VERSION ""

NS_ :

BS_:

BU_: ESP_ABR Vector__XXX

BA_DEF_ BO_ "GenMsgCycleTime" INT 0 65535;
BA_DEF_DEF_ "GenMsgCycleTime" 0;

CM_ "Converted from Mercedes 204_CHASSIS_AEJ2010_1.dat binary database.";

BO_ 1 EIS_A1: 8 ESP_ABR
 SG_ ISw_Stat : 5|3@1+ (1,0) [0|7] "" Vector__XXX

CM_ SG_ 1 ISw_Stat "ISw_Stat [source enum/value-table reference]";
 SG_ Ign_On_StProc_Inact : 4|1@1+ (1,0) [0|1] "" Vector__XXX

CM_ SG_ 1 Ign_On_StProc_Inact "Ign_On_StProc_Inact [source boolean]";
 SG_ TxPkPosn_Rq : 3|1@1+ (1,0) [0|1] "" Vector__XXX

CM_ SG_ 1 TxPkPosn_Rq "TxPkPosn_Rq [source boolean]";
 SG_ TxPkPosn_Emg_Rq : 2|1@1+ (1,0) [0|1] "" Vector__XXX

CM_ SG_ 1 TxPkPosn_Emg_Rq "TxPkPosn_Emg_Rq [source boolean]";
 SG_ TxPkPosn_Rq_SBC_Enbl : 0|1@1+ (1,0) [0|1] "" Vector__XXX

CM_ SG_ 1 TxPkPosn_Rq_SBC_Enbl "TxPkPosn_Rq_SBC_Enbl [source boolean]";
 SG_ KG_IgnCtrl_Actv : 15|1@1+ (1,0) [0|1] "" Vector__XXX

CM_ SG_ 1 KG_IgnCtrl_Actv "KG_IgnCtrl_Actv [source boolean]";
 SG_ EngSt_Enbl_Rq_KG : 14|1@1+ (1,0) [0|1] "" Vector__XXX

CM_ SG_ 1 EngSt_Enbl_Rq_KG "EngSt_Enbl_Rq_KG [source boolean]";
 SG_ KG_StSw_Psd : 13|1@1+ (1,0) [0|1] "" Vector__XXX

CM_ SG_ 1 KG_StSw_Psd "KG_StSw_Psd [source boolean]";
 SG_ AutoDrLk_Rq_Src : 8|2@1+ (1,0) [0|3] "" Vector__XXX

CM_ SG_ 1 AutoDrLk_Rq_Src "AutoDrLk_Rq_Src [source enum/value-table reference]";
 SG_ AutoDrLk_Stat : 18|2@1+ (1,0) [0|3] "" Vector__XXX

CM_ SG_ 1 AutoDrLk_Stat "AutoDrLk_Stat [source enum/value-table reference]";
 SG_ SPCR_Conf_EIS : 30|2@1+ (1,0) [0|3] "" Vector__XXX

CM_ SG_ 1 SPCR_Conf_EIS "SPCR_Conf_EIS [source enum/value-table reference]";
 SG_ CLkS_DL_Stat : 26|2@1+ (1,0) [0|3] "" Vector__XXX

CM_ SG_ 1 CLkS_DL_Stat "CLkS_DL_Stat [source enum/value-table reference]";
 SG_ CLkS_Gas_Dr_Stat : 24|2@1+ (1,0) [0|3] "" Vector__XXX

CM_ SG_ 1 CLkS_Gas_Dr_Stat "CLkS_Gas_Dr_Stat [source enum/value-table reference]";
 SG_ CLkS_Dr_FL_Stat : 38|2@1+ (1,0) [0|3] "" Vector__XXX

CM_ SG_ 1 CLkS_Dr_FL_Stat "CLkS_Dr_FL_Stat [source enum/value-table reference]";
 SG_ CLkS_Dr_FR_Stat : 36|2@1+ (1,0) [0|3] "" Vector__XXX

CM_ SG_ 1 CLkS_Dr_FR_Stat "CLkS_Dr_FR_Stat [source enum/value-table reference]";
 SG_ CLkS_Dr_RL_Stat : 34|2@1+ (1,0) [0|3] "" Vector__XXX

CM_ SG_ 1 CLkS_Dr_RL_Stat "CLkS_Dr_RL_Stat [source enum/value-table reference]";
 SG_ CLkS_Dr_RR_Stat : 32|2@1+ (1,0) [0|3] "" Vector__XXX

CM_ SG_ 1 CLkS_Dr_RR_Stat "CLkS_Dr_RR_Stat [source enum/value-table reference]";
 SG_ KeyLine1_Appr : 47|1@1+ (1,0) [0|1] "" Vector__XXX

CM_ SG_ 1 KeyLine1_Appr "KeyLine1_Appr [source boolean]";
 SG_ KeyLine2_Appr : 46|1@1+ (1,0) [0|1] "" Vector__XXX

CM_ SG_ 1 KeyLine2_Appr "KeyLine2_Appr [source boolean]";
 SG_ KeyLine3_Appr : 45|1@1+ (1,0) [0|1] "" Vector__XXX

CM_ SG_ 1 KeyLine3_Appr "KeyLine3_Appr [source boolean]";
 SG_ KeyLine4_Appr : 44|1@1+ (1,0) [0|1] "" Vector__XXX

CM_ SG_ 1 KeyLine4_Appr "KeyLine4_Appr [source boolean]";
 SG_ KeyLine5_Appr : 43|1@1+ (1,0) [0|1] "" Vector__XXX

CM_ SG_ 1 KeyLine5_Appr "KeyLine5_Appr [source boolean]";
 SG_ KeyLine6_Appr : 42|1@1+ (1,0) [0|1] "" Vector__XXX

CM_ SG_ 1 KeyLine6_Appr "KeyLine6_Appr [source boolean]";
 SG_ KeyLine7_Appr : 41|1@1+ (1,0) [0|1] "" Vector__XXX

CM_ SG_ 1 KeyLine7_Appr "KeyLine7_Appr [source boolean]";
 SG_ KeyLine8_Appr : 40|1@1+ (1,0) [0|1] "" Vector__XXX

CM_ SG_ 1 KeyLine8_Appr "KeyLine8_Appr [source boolean]";
 SG_ CLkS_Lk_Stat3 : 53|3@1+ (1,0) [0|7] "" Vector__XXX

CM_ SG_ 1 CLkS_Lk_Stat3 "CLkS_Lk_Stat3 [source enum/value-table reference]";
 SG_ SPCR_AcustWarn_Rq_EIS : 52|1@1+ (1,0) [0|1] "" Vector__XXX

CM_ SG_ 1 SPCR_AcustWarn_Rq_EIS "SPCR_AcustWarn_Rq_EIS [source boolean]";
 SG_ MC_EIS_A1 : 48|4@1+ (1,0) [0|15] "" Vector__XXX

CM_ SG_ 1 MC_EIS_A1 "MC_EIS_A1";
 SG_ CRC_EIS_A1 : 56|8@1+ (1,0) [0|255] "" Vector__XXX

CM_ SG_ 1 CRC_EIS_A1 "CRC_EIS_A1";

BA_ "GenMsgCycleTime" BO_ 1 29;

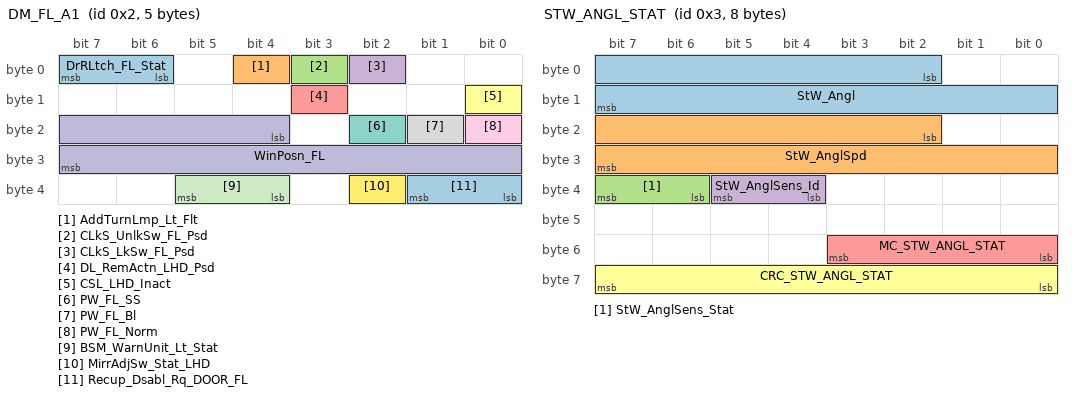
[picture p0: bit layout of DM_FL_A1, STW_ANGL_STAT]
BO_ 2 DM_FL_A1: 5 ESP_ABR
 SG_ DrRLtch_FL_Stat : 6|2@1+ (1,0) [0|3] "" Vector__XXX

CM_ SG_ 2 DrRLtch_FL_Stat "DrRLtch_FL_Stat [source enum/value-table reference]";
 SG_ AddTurnLmp_Lt_Flt : 4|1@1+ (1,0) [0|1] "" Vector__XXX

CM_ SG_ 2 AddTurnLmp_Lt_Flt "AddTurnLmp_Lt_Flt [source boolean]";
 SG_ CLkS_UnlkSw_FL_Psd : 3|1@1+ (1,0) [0|1] "" Vector__XXX

CM_ SG_ 2 CLkS_UnlkSw_FL_Psd "CLkS_UnlkSw_FL_Psd [source boolean]";
 SG_ CLkS_LkSw_FL_Psd : 2|1@1+ (1,0) [0|1] "" Vector__XXX

CM_ SG_ 2 CLkS_LkSw_FL_Psd "CLkS_LkSw_FL_Psd [source boolean]";
 SG_ DL_RemActn_LHD_Psd : 11|1@1+ (1,0) [0|1] "" Vector__XXX

CM_ SG_ 2 DL_RemActn_LHD_Psd "DL_RemActn_LHD_Psd [source boolean]";
 SG_ CSL_LHD_Inact : 8|1@1+ (1,0) [0|1] "" Vector__XXX

CM_ SG_ 2 CSL_LHD_Inact "CSL_LHD_Inact [source boolean]";
 SG_ PW_FL_SS : 18|1@1+ (1,0) [0|1] "" Vector__XXX

CM_ SG_ 2 PW_FL_SS "PW_FL_SS [source boolean]";
 SG_ PW_FL_Bl : 17|1@1+ (1,0) [0|1] "" Vector__XXX

CM_ SG_ 2 PW_FL_Bl "PW_FL_Bl [source boolean]";
 SG_ PW_FL_Norm : 16|1@1+ (1,0) [0|1] "" Vector__XXX

CM_ SG_ 2 PW_FL_Norm "PW_FL_Norm [source boolean]";
 SG_ WinPosn_FL : 20|12@1+ (0.25,-512) [-512|511.75] "1/RotorRevol" Vector__XXX

CM_ SG_ 2 WinPosn_FL "WinPosn_FL";
 SG_ BSM_WarnUnit_Lt_Stat : 36|2@1+ (1,0) [0|3] "" Vector__XXX

CM_ SG_ 2 BSM_WarnUnit_Lt_Stat "BSM_WarnUnit_Lt_Stat [source enum/value-table reference]";
 SG_ MirrAdjSw_Stat_LHD : 34|1@1+ (1,0) [0|1] "" Vector__XXX

CM_ SG_ 2 MirrAdjSw_Stat_LHD "MirrAdjSw_Stat_LHD [source boolean]";
 SG_ Recup_Dsabl_Rq_DOOR_FL : 32|2@1+ (1,0) [0|3] "" Vector__XXX

CM_ SG_ 2 Recup_Dsabl_Rq_DOOR_FL "Recup_Dsabl_Rq_DOOR_FL [source enum/value-table reference]";

BA_ "GenMsgCycleTime" BO_ 2 13;

BO_ 3 STW_ANGL_STAT: 8 ESP_ABR
 SG_ StW_Angl : 2|14@1+ (0.5,-2048) [-2048|6143.5] "deg" Vector__XXX

CM_ SG_ 3 StW_Angl "StW_Angl";
 SG_ StW_AnglSpd : 18|14@1+ (0.5,-2048) [-2048|6143.5] "deg/s" Vector__XXX

CM_ SG_ 3 StW_AnglSpd "StW_AnglSpd";
 SG_ StW_AnglSens_Stat : 38|2@1+ (1,0) [0|3] "" Vector__XXX

CM_ SG_ 3 StW_AnglSens_Stat "StW_AnglSens_Stat [source enum/value-table reference]";
 SG_ StW_AnglSens_Id : 36|2@1+ (1,0) [0|3] "" Vector__XXX

CM_ SG_ 3 StW_AnglSens_Id "StW_AnglSens_Id [source enum/value-table reference]";
 SG_ MC_STW_ANGL_STAT : 48|4@1+ (1,0) [0|15] "" Vector__XXX

CM_ SG_ 3 MC_STW_ANGL_STAT "MC_STW_ANGL_STAT";
 SG_ CRC_STW_ANGL_STAT : 56|8@1+ (1,0) [0|255] "" Vector__XXX

CM_ SG_ 3 CRC_STW_ANGL_STAT "CRC_STW_ANGL_STAT";

BA_ "GenMsgCycleTime" BO_ 3 6;

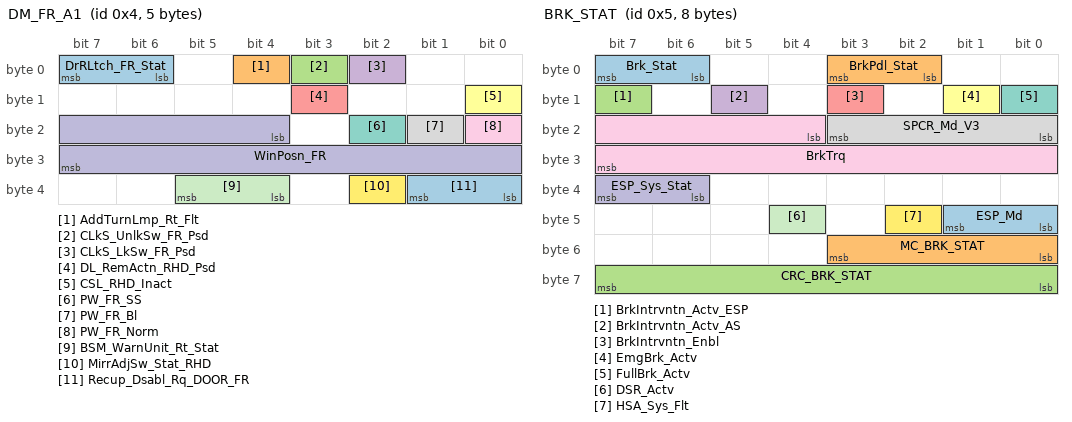
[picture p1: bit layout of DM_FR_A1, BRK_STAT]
BO_ 4 DM_FR_A1: 5 ESP_ABR
 SG_ DrRLtch_FR_Stat : 6|2@1+ (1,0) [0|3] "" Vector__XXX

CM_ SG_ 4 DrRLtch_FR_Stat "DrRLtch_FR_Stat [source enum/value-table reference]";
 SG_ AddTurnLmp_Rt_Flt : 4|1@1+ (1,0) [0|1] "" Vector__XXX

CM_ SG_ 4 AddTurnLmp_Rt_Flt "AddTurnLmp_Rt_Flt [source boolean]";
 SG_ CLkS_UnlkSw_FR_Psd : 3|1@1+ (1,0) [0|1] "" Vector__XXX

CM_ SG_ 4 CLkS_UnlkSw_FR_Psd "CLkS_UnlkSw_FR_Psd [source boolean]";
 SG_ CLkS_LkSw_FR_Psd : 2|1@1+ (1,0) [0|1] "" Vector__XXX

CM_ SG_ 4 CLkS_LkSw_FR_Psd "CLkS_LkSw_FR_Psd [source boolean]";
 SG_ DL_RemActn_RHD_Psd : 11|1@1+ (1,0) [0|1] "" Vector__XXX

CM_ SG_ 4 DL_RemActn_RHD_Psd "DL_RemActn_RHD_Psd [source boolean]";
 SG_ CSL_RHD_Inact : 8|1@1+ (1,0) [0|1] "" Vector__XXX

CM_ SG_ 4 CSL_RHD_Inact "CSL_RHD_Inact [source boolean]";
 SG_ PW_FR_SS : 18|1@1+ (1,0) [0|1] "" Vector__XXX

CM_ SG_ 4 PW_FR_SS "PW_FR_SS [source boolean]";
 SG_ PW_FR_Bl : 17|1@1+ (1,0) [0|1] "" Vector__XXX

CM_ SG_ 4 PW_FR_Bl "PW_FR_Bl [source boolean]";
 SG_ PW_FR_Norm : 16|1@1+ (1,0) [0|1] "" Vector__XXX

CM_ SG_ 4 PW_FR_Norm "PW_FR_Norm [source boolean]";
 SG_ WinPosn_FR : 20|12@1+ (0.25,-512) [-512|511.75] "1/RotorRevol" Vector__XXX

CM_ SG_ 4 WinPosn_FR "WinPosn_FR";
 SG_ BSM_WarnUnit_Rt_Stat : 36|2@1+ (1,0) [0|3] "" Vector__XXX

CM_ SG_ 4 BSM_WarnUnit_Rt_Stat "BSM_WarnUnit_Rt_Stat [source enum/value-table reference]";
 SG_ MirrAdjSw_Stat_RHD : 34|1@1+ (1,0) [0|1] "" Vector__XXX

CM_ SG_ 4 MirrAdjSw_Stat_RHD "MirrAdjSw_Stat_RHD [source boolean]";
 SG_ Recup_Dsabl_Rq_DOOR_FR : 32|2@1+ (1,0) [0|3] "" Vector__XXX

CM_ SG_ 4 Recup_Dsabl_Rq_DOOR_FR "Recup_Dsabl_Rq_DOOR_FR [source enum/value-table reference]";

BA_ "GenMsgCycleTime" BO_ 4 13;

BO_ 5 BRK_STAT: 8 ESP_ABR
 SG_ Brk_Stat : 6|2@1+ (1,0) [0|3] "" Vector__XXX

CM_ SG_ 5 Brk_Stat "Brk_Stat [source enum/value-table reference]";
 SG_ BrkPdl_Stat : 2|2@1+ (1,0) [0|3] "" Vector__XXX

CM_ SG_ 5 BrkPdl_Stat "BrkPdl_Stat [source enum/value-table reference]";
 SG_ BrkIntrvntn_Actv_ESP : 15|1@1+ (1,0) [0|1] "" Vector__XXX

CM_ SG_ 5 BrkIntrvntn_Actv_ESP "BrkIntrvntn_Actv_ESP [source boolean]";
 SG_ BrkIntrvntn_Actv_AS : 13|1@1+ (1,0) [0|1] "" Vector__XXX

CM_ SG_ 5 BrkIntrvntn_Actv_AS "BrkIntrvntn_Actv_AS [source boolean]";
 SG_ BrkIntrvntn_Enbl : 11|1@1+ (1,0) [0|1] "" Vector__XXX

CM_ SG_ 5 BrkIntrvntn_Enbl "BrkIntrvntn_Enbl [source boolean]";
 SG_ EmgBrk_Actv : 9|1@1+ (1,0) [0|1] "" Vector__XXX

CM_ SG_ 5 EmgBrk_Actv "EmgBrk_Actv [source boolean]";
 SG_ FullBrk_Actv : 8|1@1+ (1,0) [0|1] "" Vector__XXX

CM_ SG_ 5 FullBrk_Actv "FullBrk_Actv [source boolean]";
 SG_ SPCR_Md_V3 : 16|4@1+ (1,0) [0|15] "" Vector__XXX

CM_ SG_ 5 SPCR_Md_V3 "SPCR_Md_V3 [source enum/value-table reference]";
 SG_ BrkTrq : 20|12@1+ (3,0) [0|12285] "Nm" Vector__XXX

CM_ SG_ 5 BrkTrq "BrkTrq";
 SG_ ESP_Sys_Stat : 38|2@1+ (1,0) [0|3] "" Vector__XXX

CM_ SG_ 5 ESP_Sys_Stat "ESP_Sys_Stat [source enum/value-table reference]";
 SG_ DSR_Actv : 44|1@1+ (1,0) [0|1] "" Vector__XXX

CM_ SG_ 5 DSR_Actv "DSR_Actv [source boolean]";
 SG_ HSA_Sys_Flt : 42|1@1+ (1,0) [0|1] "" Vector__XXX

CM_ SG_ 5 HSA_Sys_Flt "HSA_Sys_Flt [source boolean]";
 SG_ ESP_Md : 40|2@1+ (1,0) [0|3] "" Vector__XXX

CM_ SG_ 5 ESP_Md "ESP_Md [source enum/value-table reference]";
 SG_ MC_BRK_STAT : 48|4@1+ (1,0) [0|15] "" Vector__XXX

CM_ SG_ 5 MC_BRK_STAT "MC_BRK_STAT";
 SG_ CRC_BRK_STAT : 56|8@1+ (1,0) [0|255] "" Vector__XXX

CM_ SG_ 5 CRC_BRK_STAT "CRC_BRK_STAT";

BA_ "GenMsgCycleTime" BO_ 5 15;

BO_ 14 STW_ANGLHP_STAT: 8 ESP_ABR
 SG_ StW_AnglHP : 2|14@1+ (0.10000000149,-819.200012207) [-819.200012207|819.100012206] "deg" Vector__XXX

CM_ SG_ 14 StW_AnglHP "StW_AnglHP";
 SG_ StW_AnglHP_Sens_Stat : 38|2@1+ (1,0) [0|3] "" Vector__XXX

CM_ SG_ 14 StW_AnglHP_Sens_Stat "StW_AnglHP_Sens_Stat [source enum/value-table reference]";
 SG_ StW_AnglHP_Sens_Id : 36|2@1+ (1,0) [0|3] "" Vector__XXX

CM_ SG_ 14 StW_AnglHP_Sens_Id "StW_AnglHP_Sens_Id [source enum/value-table reference]";
 SG_ MC_STW_ANGLHP_STAT : 48|4@1+ (1,0) [0|15] "" Vector__XXX

CM_ SG_ 14 MC_STW_ANGLHP_STAT "MC_STW_ANGLHP_STAT";
 SG_ CRC_STW_ANGLHP_STAT : 56|8@1+ (1,0) [0|255] "" Vector__XXX

CM_ SG_ 14 CRC_STW_ANGLHP_STAT "CRC_STW_ANGLHP_STAT";

BA_ "GenMsgCycleTime" BO_ 14 5;

BO_ 15 CGW_STAT: 1 ESP_ABR
 SG_ CGW_Rout_Stat : 6|2@1+ (1,0) [0|3] "" Vector__XXX

CM_ SG_ 15 CGW_Rout_Stat "CGW_Rout_Stat [source enum/value-table reference]";
 SG_ BusFlt_PrmntActv : 5|1@1+ (1,0) [0|1] "" Vector__XXX

CM_ SG_ 15 BusFlt_PrmntActv "BusFlt_PrmntActv [source boolean]";

BA_ "GenMsgCycleTime" BO_ 15 2;

BO_ 21 CTRL_U_A2: 2 ESP_ABR
 SG_ SwIllLvl : 0|8@1+ (1,0) [0|255] "%" Vector__XXX

CM_ SG_ 21 SwIllLvl "SwIllLvl";
 SG_ DispBrt_IC : 8|8@1+ (1,0) [0|255] "%" Vector__XXX

CM_ SG_ 21 DispBrt_IC "DispBrt_IC [source enum/value-table reference]";

BA_ "GenMsgCycleTime" BO_ 21 2;

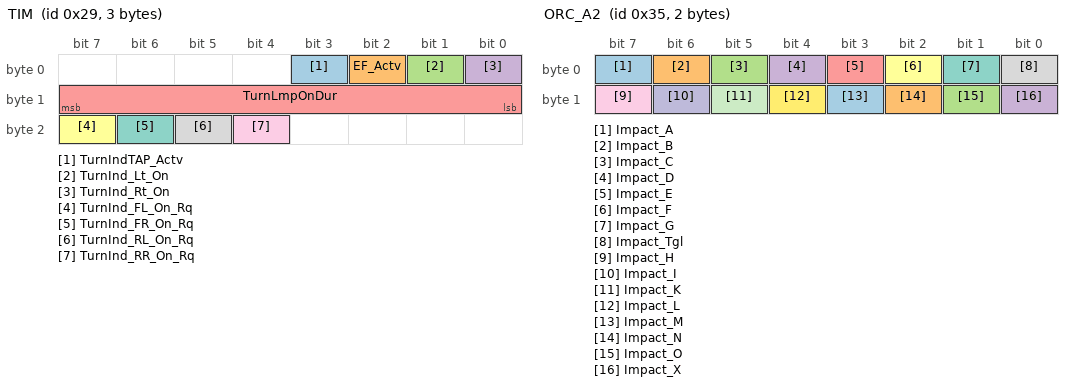
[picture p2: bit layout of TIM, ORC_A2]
BO_ 41 TIM: 3 ESP_ABR
 SG_ TurnIndTAP_Actv : 3|1@1+ (1,0) [0|1] "" Vector__XXX

CM_ SG_ 41 TurnIndTAP_Actv "TurnIndTAP_Actv [source boolean]";
 SG_ EF_Actv : 2|1@1+ (1,0) [0|1] "" Vector__XXX

CM_ SG_ 41 EF_Actv "EF_Actv [source boolean]";
 SG_ TurnInd_Lt_On : 1|1@1+ (1,0) [0|1] "" Vector__XXX

CM_ SG_ 41 TurnInd_Lt_On "TurnInd_Lt_On [source boolean]";
 SG_ TurnInd_Rt_On : 0|1@1+ (1,0) [0|1] "" Vector__XXX

CM_ SG_ 41 TurnInd_Rt_On "TurnInd_Rt_On [source boolean]";
 SG_ TurnLmpOnDur : 8|8@1+ (10,0) [0|2550] "ms" Vector__XXX

CM_ SG_ 41 TurnLmpOnDur "TurnLmpOnDur";
 SG_ TurnInd_FL_On_Rq : 23|1@1+ (1,0) [0|1] "" Vector__XXX

CM_ SG_ 41 TurnInd_FL_On_Rq "TurnInd_FL_On_Rq [source boolean]";
 SG_ TurnInd_FR_On_Rq : 22|1@1+ (1,0) [0|1] "" Vector__XXX

CM_ SG_ 41 TurnInd_FR_On_Rq "TurnInd_FR_On_Rq [source boolean]";
 SG_ TurnInd_RL_On_Rq : 21|1@1+ (1,0) [0|1] "" Vector__XXX

CM_ SG_ 41 TurnInd_RL_On_Rq "TurnInd_RL_On_Rq [source boolean]";
 SG_ TurnInd_RR_On_Rq : 20|1@1+ (1,0) [0|1] "" Vector__XXX

CM_ SG_ 41 TurnInd_RR_On_Rq "TurnInd_RR_On_Rq [source boolean]";

BA_ "GenMsgCycleTime" BO_ 41 9;

BO_ 53 ORC_A2: 2 ESP_ABR
 SG_ Impact_A : 7|1@1+ (1,0) [0|1] "" Vector__XXX

CM_ SG_ 53 Impact_A "Impact_A [source boolean]";
 SG_ Impact_B : 6|1@1+ (1,0) [0|1] "" Vector__XXX

CM_ SG_ 53 Impact_B "Impact_B [source boolean]";
 SG_ Impact_C : 5|1@1+ (1,0) [0|1] "" Vector__XXX

CM_ SG_ 53 Impact_C "Impact_C [source boolean]";
 SG_ Impact_D : 4|1@1+ (1,0) [0|1] "" Vector__XXX

CM_ SG_ 53 Impact_D "Impact_D [source boolean]";
 SG_ Impact_E : 3|1@1+ (1,0) [0|1] "" Vector__XXX

CM_ SG_ 53 Impact_E "Impact_E [source boolean]";
 SG_ Impact_F : 2|1@1+ (1,0) [0|1] "" Vector__XXX

CM_ SG_ 53 Impact_F "Impact_F [source boolean]";
 SG_ Impact_G : 1|1@1+ (1,0) [0|1] "" Vector__XXX

CM_ SG_ 53 Impact_G "Impact_G [source boolean]";
 SG_ Impact_Tgl : 0|1@1+ (1,0) [0|1] "" Vector__XXX

CM_ SG_ 53 Impact_Tgl "Impact_Tgl [source boolean]";
 SG_ Impact_H : 15|1@1+ (1,0) [0|1] "" Vector__XXX

CM_ SG_ 53 Impact_H "Impact_H [source boolean]";
 SG_ Impact_I : 14|1@1+ (1,0) [0|1] "" Vector__XXX

CM_ SG_ 53 Impact_I "Impact_I [source boolean]";
 SG_ Impact_K : 13|1@1+ (1,0) [0|1] "" Vector__XXX

CM_ SG_ 53 Impact_K "Impact_K [source boolean]";
 SG_ Impact_L : 12|1@1+ (1,0) [0|1] "" Vector__XXX

CM_ SG_ 53 Impact_L "Impact_L [source boolean]";
 SG_ Impact_M : 11|1@1+ (1,0) [0|1] "" Vector__XXX

CM_ SG_ 53 Impact_M "Impact_M [source boolean]";
 SG_ Impact_N : 10|1@1+ (1,0) [0|1] "" Vector__XXX

CM_ SG_ 53 Impact_N "Impact_N [source boolean]";
 SG_ Impact_O : 9|1@1+ (1,0) [0|1] "" Vector__XXX

CM_ SG_ 53 Impact_O "Impact_O [source boolean]";
 SG_ Impact_X : 8|1@1+ (1,0) [0|1] "" Vector__XXX

CM_ SG_ 53 Impact_X "Impact_X [source boolean]";

BA_ "GenMsgCycleTime" BO_ 53 16;

BO_ 69 STW_ACTN_RQ: 8 ESP_ABR
 SG_ SpdCtrlLvr_Stat : 2|6@1+ (1,0) [0|63] "" Vector__XXX

CM_ SG_ 69 SpdCtrlLvr_Stat "SpdCtrlLvr_Stat [source enum/value-table reference]";
 SG_ VSL_Enbl_Rq : 1|1@1+ (1,0) [0|1] "" Vector__XXX

CM_ SG_ 69 VSL_Enbl_Rq "VSL_Enbl_Rq [source boolean]";
 SG_ SpdCtrlLvrStat_Inv : 0|1@1+ (1,0) [0|1] "" Vector__XXX

CM_ SG_ 69 SpdCtrlLvrStat_Inv "SpdCtrlLvrStat_Inv [source boolean]";
 SG_ DTR_Dist_Rq : 8|8@1+ (1,0) [0|255] "" Vector__XXX

CM_ SG_ 69 DTR_Dist_Rq "DTR_Dist_Rq";
 SG_ TurnIndLvr_Stat : 22|2@1+ (1,0) [0|3] "" Vector__XXX

CM_ SG_ 69 TurnIndLvr_Stat "TurnIndLvr_Stat [source enum/value-table reference]";
 SG_ HiBmLvr_Stat : 20|2@1+ (1,0) [0|3] "" Vector__XXX

CM_ SG_ 69 HiBmLvr_Stat "HiBmLvr_Stat [source enum/value-table reference]";
 SG_ WprWashSw_Psd : 18|2@1+ (1,0) [0|3] "" Vector__XXX

CM_ SG_ 69 WprWashSw_Psd "WprWashSw_Psd [source enum/value-table reference]";
 SG_ WprWash_R_Sw_Posn_V2 : 16|2@1+ (1,0) [0|3] "" Vector__XXX

CM_ SG_ 69 WprWash_R_Sw_Posn_V2 "WprWash_R_Sw_Posn_V2 [source enum/value-table reference]";
 SG_ StW_Lvr_Stat : 29|3@1+ (1,0) [0|7] "" Vector__XXX

CM_ SG_ 69 StW_Lvr_Stat "StW_Lvr_Stat [source enum/value-table reference]";
 SG_ StW_Cond_Flt : 28|1@1+ (1,0) [0|1] "" Vector__XXX

CM_ SG_ 69 StW_Cond_Flt "StW_Cond_Flt [source boolean]";
 SG_ StW_Cond_Psd : 26|2@1+ (1,0) [0|3] "" Vector__XXX

CM_ SG_ 69 StW_Cond_Psd "StW_Cond_Psd [source enum/value-table reference]";
 SG_ HrnSw_Psd : 24|2@1+ (1,0) [0|3] "" Vector__XXX

CM_ SG_ 69 HrnSw_Psd "HrnSw_Psd [source enum/value-table reference]";
 SG_ StW_Sw00_Psd : 39|1@1+ (1,0) [0|1] "" Vector__XXX

CM_ SG_ 69 StW_Sw00_Psd "StW_Sw00_Psd [source boolean]";
 SG_ StW_Sw01_Psd : 38|1@1+ (1,0) [0|1] "" Vector__XXX

CM_ SG_ 69 StW_Sw01_Psd "StW_Sw01_Psd [source boolean]";
 SG_ StW_Sw02_Psd : 37|1@1+ (1,0) [0|1] "" Vector__XXX

CM_ SG_ 69 StW_Sw02_Psd "StW_Sw02_Psd [source boolean]";
 SG_ StW_Sw03_Psd : 36|1@1+ (1,0) [0|1] "" Vector__XXX

CM_ SG_ 69 StW_Sw03_Psd "StW_Sw03_Psd [source boolean]";
 SG_ StW_Sw04_Psd : 35|1@1+ (1,0) [0|1] "" Vector__XXX

CM_ SG_ 69 StW_Sw04_Psd "StW_Sw04_Psd [source boolean]";
 SG_ StW_Sw05_Psd : 34|1@1+ (1,0) [0|1] "" Vector__XXX

CM_ SG_ 69 StW_Sw05_Psd "StW_Sw05_Psd [source boolean]";
 SG_ StW_Sw06_Psd : 33|1@1+ (1,0) [0|1] "" Vector__XXX

CM_ SG_ 69 StW_Sw06_Psd "StW_Sw06_Psd [source boolean]";
 SG_ StW_Sw07_Psd : 32|1@1+ (1,0) [0|1] "" Vector__XXX

CM_ SG_ 69 StW_Sw07_Psd "StW_Sw07_Psd [source boolean]";
 SG_ StW_Sw08_Psd : 47|1@1+ (1,0) [0|1] "" Vector__XXX

CM_ SG_ 69 StW_Sw08_Psd "StW_Sw08_Psd [source boolean]";
 SG_ StW_Sw09_Psd : 46|1@1+ (1,0) [0|1] "" Vector__XXX

CM_ SG_ 69 StW_Sw09_Psd "StW_Sw09_Psd [source boolean]";
 SG_ StW_Sw10_Psd : 45|1@1+ (1,0) [0|1] "" Vector__XXX

CM_ SG_ 69 StW_Sw10_Psd "StW_Sw10_Psd [source boolean]";
 SG_ StW_Sw11_Psd : 44|1@1+ (1,0) [0|1] "" Vector__XXX

CM_ SG_ 69 StW_Sw11_Psd "StW_Sw11_Psd [source boolean]";
 SG_ StW_Sw12_Psd : 43|1@1+ (1,0) [0|1] "" Vector__XXX

CM_ SG_ 69 StW_Sw12_Psd "StW_Sw12_Psd [source boolean]";
 SG_ StW_Sw13_Psd : 42|1@1+ (1,0) [0|1] "" Vector__XXX

CM_ SG_ 69 StW_Sw13_Psd "StW_Sw13_Psd [source boolean]";
 SG_ StW_Sw14_Psd : 41|1@1+ (1,0) [0|1] "" Vector__XXX

CM_ SG_ 69 StW_Sw14_Psd "StW_Sw14_Psd [source boolean]";
 SG_ StW_Sw15_Psd : 40|1@1+ (1,0) [0|1] "" Vector__XXX

CM_ SG_ 69 StW_Sw15_Psd "StW_Sw15_Psd [source boolean]";
 SG_ WprSw6Posn : 53|3@1+ (1,0) [0|7] "" Vector__XXX

CM_ SG_ 69 WprSw6Posn "WprSw6Posn [source enum/value-table reference]";
 SG_ MC_STW_ACTN_RQ : 48|4@1+ (1,0) [0|15] "" Vector__XXX

CM_ SG_ 69 MC_STW_ACTN_RQ "MC_STW_ACTN_RQ";
 SG_ CRC_STW_ACTN_RQ : 56|8@1+ (1,0) [0|255] "" Vector__XXX

CM_ SG_ 69 CRC_STW_ACTN_RQ "CRC_STW_ACTN_RQ";

BA_ "GenMsgCycleTime" BO_ 69 31;

BO_ 95 BRK_STAT2: 8 ESP_ABR
 SG_ BrkTrq_D : 4|12@1+ (3,0) [0|12285] "Nm" Vector__XXX

CM_ SG_ 95 BrkTrq_D "BrkTrq_D";
 SG_ ECO_StVlvCurr_Rq : 16|4@1+ (100,0) [0|1500] "mA" Vector__XXX

CM_ SG_ 95 ECO_StVlvCurr_Rq "ECO_StVlvCurr_Rq";
 SG_ BrkTrqGrdnt_D : 20|12@1+ (97.6797790527,-200048) [-200048|199950.695221] "Nm/s" Vector__XXX

CM_ SG_ 95 BrkTrqGrdnt_D "BrkTrqGrdnt_D";
 SG_ MC_BRK_STAT2 : 48|4@1+ (1,0) [0|15] "" Vector__XXX

CM_ SG_ 95 MC_BRK_STAT2 "MC_BRK_STAT2";
 SG_ CRC_BRK_STAT2 : 56|8@1+ (1,0) [0|255] "" Vector__XXX

CM_ SG_ 95 CRC_BRK_STAT2 "CRC_BRK_STAT2";

BA_ "GenMsgCycleTime" BO_ 95 5;

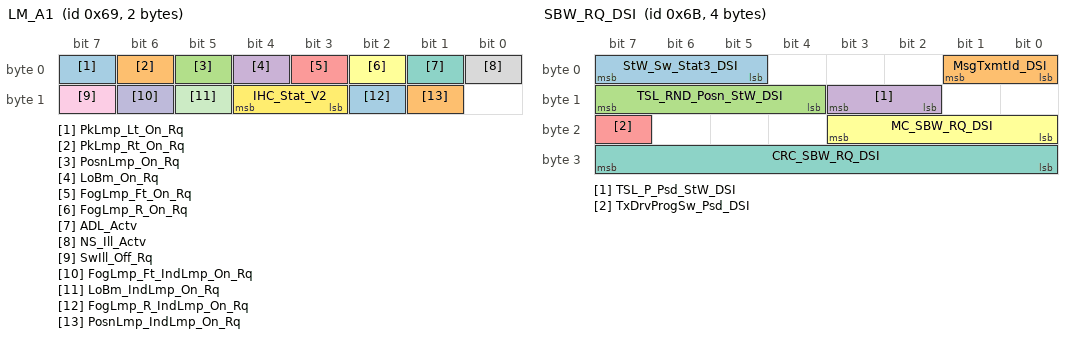
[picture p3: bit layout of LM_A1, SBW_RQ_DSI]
BO_ 105 LM_A1: 2 ESP_ABR
 SG_ PkLmp_Lt_On_Rq : 7|1@1+ (1,0) [0|1] "" Vector__XXX

CM_ SG_ 105 PkLmp_Lt_On_Rq "PkLmp_Lt_On_Rq [source boolean]";
 SG_ PkLmp_Rt_On_Rq : 6|1@1+ (1,0) [0|1] "" Vector__XXX

CM_ SG_ 105 PkLmp_Rt_On_Rq "PkLmp_Rt_On_Rq [source boolean]";
 SG_ PosnLmp_On_Rq : 5|1@1+ (1,0) [0|1] "" Vector__XXX

CM_ SG_ 105 PosnLmp_On_Rq "PosnLmp_On_Rq [source boolean]";
 SG_ LoBm_On_Rq : 4|1@1+ (1,0) [0|1] "" Vector__XXX

CM_ SG_ 105 LoBm_On_Rq "LoBm_On_Rq [source boolean]";
 SG_ FogLmp_Ft_On_Rq : 3|1@1+ (1,0) [0|1] "" Vector__XXX

CM_ SG_ 105 FogLmp_Ft_On_Rq "FogLmp_Ft_On_Rq [source boolean]";
 SG_ FogLmp_R_On_Rq : 2|1@1+ (1,0) [0|1] "" Vector__XXX

CM_ SG_ 105 FogLmp_R_On_Rq "FogLmp_R_On_Rq [source boolean]";
 SG_ ADL_Actv : 1|1@1+ (1,0) [0|1] "" Vector__XXX

CM_ SG_ 105 ADL_Actv "ADL_Actv [source boolean]";
 SG_ NS_Ill_Actv : 0|1@1+ (1,0) [0|1] "" Vector__XXX

CM_ SG_ 105 NS_Ill_Actv "NS_Ill_Actv [source boolean]";
 SG_ SwIll_Off_Rq : 15|1@1+ (1,0) [0|1] "" Vector__XXX

CM_ SG_ 105 SwIll_Off_Rq "SwIll_Off_Rq [source boolean]";
 SG_ FogLmp_Ft_IndLmp_On_Rq : 14|1@1+ (1,0) [0|1] "" Vector__XXX

CM_ SG_ 105 FogLmp_Ft_IndLmp_On_Rq "FogLmp_Ft_IndLmp_On_Rq [source boolean]";
 SG_ LoBm_IndLmp_On_Rq : 13|1@1+ (1,0) [0|1] "" Vector__XXX

CM_ SG_ 105 LoBm_IndLmp_On_Rq "LoBm_IndLmp_On_Rq [source boolean]";
 SG_ IHC_Stat_V2 : 11|2@1+ (1,0) [0|3] "" Vector__XXX

CM_ SG_ 105 IHC_Stat_V2 "IHC_Stat_V2 [source enum/value-table reference]";
 SG_ FogLmp_R_IndLmp_On_Rq : 10|1@1+ (1,0) [0|1] "" Vector__XXX

CM_ SG_ 105 FogLmp_R_IndLmp_On_Rq "FogLmp_R_IndLmp_On_Rq [source boolean]";
 SG_ PosnLmp_IndLmp_On_Rq : 9|1@1+ (1,0) [0|1] "" Vector__XXX

CM_ SG_ 105 PosnLmp_IndLmp_On_Rq "PosnLmp_IndLmp_On_Rq [source boolean]";

BA_ "GenMsgCycleTime" BO_ 105 14;

BO_ 107 SBW_RQ_DSI: 4 ESP_ABR
 SG_ StW_Sw_Stat3_DSI : 5|3@1+ (1,0) [0|7] "" Vector__XXX

CM_ SG_ 107 StW_Sw_Stat3_DSI "StW_Sw_Stat3_DSI [source enum/value-table reference]";
 SG_ MsgTxmtId_DSI : 0|2@1+ (1,0) [0|3] "" Vector__XXX

CM_ SG_ 107 MsgTxmtId_DSI "MsgTxmtId_DSI [source enum/value-table reference]";
 SG_ TSL_RND_Posn_StW_DSI : 12|4@1+ (1,0) [0|15] "" Vector__XXX

CM_ SG_ 107 TSL_RND_Posn_StW_DSI "TSL_RND_Posn_StW_DSI [source enum/value-table reference]";
 SG_ TSL_P_Psd_StW_DSI : 10|2@1+ (1,0) [0|3] "" Vector__XXX

CM_ SG_ 107 TSL_P_Psd_StW_DSI "TSL_P_Psd_StW_DSI [source enum/value-table reference]";
 SG_ TxDrvProgSw_Psd_DSI : 23|1@1+ (1,0) [0|1] "" Vector__XXX

CM_ SG_ 107 TxDrvProgSw_Psd_DSI "TxDrvProgSw_Psd_DSI [source boolean]";
 SG_ MC_SBW_RQ_DSI : 16|4@1+ (1,0) [0|15] "" Vector__XXX

CM_ SG_ 107 MC_SBW_RQ_DSI "MC_SBW_RQ_DSI";
 SG_ CRC_SBW_RQ_DSI : 24|8@1+ (1,0) [0|255] "" Vector__XXX

CM_ SG_ 107 CRC_SBW_RQ_DSI "CRC_SBW_RQ_DSI";

BA_ "GenMsgCycleTime" BO_ 107 7;

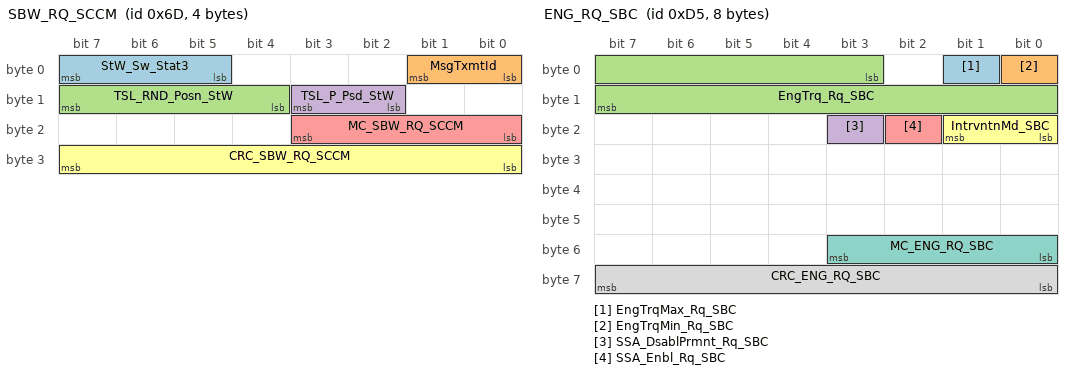
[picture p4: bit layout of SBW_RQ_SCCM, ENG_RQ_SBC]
BO_ 109 SBW_RQ_SCCM: 4 ESP_ABR
 SG_ StW_Sw_Stat3 : 5|3@1+ (1,0) [0|7] "" Vector__XXX

CM_ SG_ 109 StW_Sw_Stat3 "StW_Sw_Stat3 [source enum/value-table reference]";
 SG_ MsgTxmtId : 0|2@1+ (1,0) [0|3] "" Vector__XXX

CM_ SG_ 109 MsgTxmtId "MsgTxmtId [source enum/value-table reference]";
 SG_ TSL_RND_Posn_StW : 12|4@1+ (1,0) [0|15] "" Vector__XXX

CM_ SG_ 109 TSL_RND_Posn_StW "TSL_RND_Posn_StW [source enum/value-table reference]";
 SG_ TSL_P_Psd_StW : 10|2@1+ (1,0) [0|3] "" Vector__XXX

CM_ SG_ 109 TSL_P_Psd_StW "TSL_P_Psd_StW [source enum/value-table reference]";
 SG_ MC_SBW_RQ_SCCM : 16|4@1+ (1,0) [0|15] "" Vector__XXX

CM_ SG_ 109 MC_SBW_RQ_SCCM "MC_SBW_RQ_SCCM";
 SG_ CRC_SBW_RQ_SCCM : 24|8@1+ (1,0) [0|255] "" Vector__XXX

CM_ SG_ 109 CRC_SBW_RQ_SCCM "CRC_SBW_RQ_SCCM";

BA_ "GenMsgCycleTime" BO_ 109 6;

BO_ 115 SBW_RS_ISM: 8 ESP_ABR
 SG_ TSL_Posn_ISM : 4|4@1+ (1,0) [0|15] "" Vector__XXX

CM_ SG_ 115 TSL_Posn_ISM "TSL_Posn_ISM [source enum/value-table reference]";
 SG_ TSL_MtnLk_Actv : 3|1@1+ (1,0) [0|1] "" Vector__XXX

CM_ SG_ 115 TSL_MtnLk_Actv "TSL_MtnLk_Actv [source boolean]";
 SG_ TSL_Posn_P_ISM : 2|1@1+ (1,0) [0|1] "" Vector__XXX

CM_ SG_ 115 TSL_Posn_P_ISM "TSL_Posn_P_ISM [source boolean]";
 SG_ TxDrvProgSw_Psd_V3 : 1|1@1+ (1,0) [0|1] "" Vector__XXX

CM_ SG_ 115 TxDrvProgSw_Psd_V3 "TxDrvProgSw_Psd_V3 [source boolean]";
 SG_ PkBrk_Rq_TCM : 14|2@1+ (1,0) [0|3] "" Vector__XXX

CM_ SG_ 115 PkBrk_Rq_TCM "PkBrk_Rq_TCM [source enum/value-table reference]";
 SG_ TxN_Posn_Rq_D : 13|1@1+ (1,0) [0|1] "" Vector__XXX

CM_ SG_ 115 TxN_Posn_Rq_D "TxN_Posn_Rq_D [source boolean]";
 SG_ SBC_Add_Dsabl_Rq_ISM : 12|1@1+ (1,0) [0|1] "" Vector__XXX

CM_ SG_ 115 SBC_Add_Dsabl_Rq_ISM "SBC_Add_Dsabl_Rq_ISM [source boolean]";
 SG_ TxPkPosn_Emg_Actv : 11|1@1+ (1,0) [0|1] "" Vector__XXX

CM_ SG_ 115 TxPkPosn_Emg_Actv "TxPkPosn_Emg_Actv [source boolean]";
 SG_ Key_P_Enbl : 10|1@1+ (1,0) [0|1] "" Vector__XXX

CM_ SG_ 115 Key_P_Enbl "Key_P_Enbl [source boolean]";
 SG_ EmgPath_Enbl : 9|1@1+ (1,0) [0|1] "" Vector__XXX

CM_ SG_ 115 EmgPath_Enbl "EmgPath_Enbl [source boolean]";
 SG_ ISM_LHOM : 8|1@1+ (1,0) [0|1] "" Vector__XXX

CM_ SG_ 115 ISM_LHOM "ISM_LHOM [source boolean]";
 SG_ TSL_Angle : 16|8@1+ (0.5,0) [0|127.5] "deg" Vector__XXX

CM_ SG_ 115 TSL_Angle "TSL_Angle";
 SG_ ISM_Temp : 24|8@1+ (1,-50) [-50|205] "degC" Vector__XXX

CM_ SG_ 115 ISM_Temp "ISM_Temp";
 SG_ EmgPath_Volt : 32|8@1+ (0.10000000149,0) [0|25.50000038] "V" Vector__XXX

CM_ SG_ 115 EmgPath_Volt "EmgPath_Volt";
 SG_ TSL_ShiftLk_Stat : 40|2@1+ (1,0) [0|3] "" Vector__XXX

CM_ SG_ 115 TSL_ShiftLk_Stat "TSL_ShiftLk_Stat [source enum/value-table reference]";
 SG_ TSL_Posn_Target : 52|4@1+ (1,0) [0|15] "" Vector__XXX

CM_ SG_ 115 TSL_Posn_Target "TSL_Posn_Target [source enum/value-table reference]";
 SG_ MC_SBW_RS_ISM : 48|4@1+ (1,0) [0|15] "" Vector__XXX

CM_ SG_ 115 MC_SBW_RS_ISM "MC_SBW_RS_ISM";
 SG_ CRC_SBW_RS_ISM : 56|8@1+ (1,0) [0|255] "" Vector__XXX

CM_ SG_ 115 CRC_SBW_RS_ISM "CRC_SBW_RS_ISM";

BA_ "GenMsgCycleTime" BO_ 115 18;

BO_ 213 ENG_RQ_SBC: 8 ESP_ABR
 SG_ EngTrqMax_Rq_SBC : 1|1@1+ (1,0) [0|1] "" Vector__XXX

CM_ SG_ 213 EngTrqMax_Rq_SBC "EngTrqMax_Rq_SBC [source boolean]";
 SG_ EngTrqMin_Rq_SBC : 0|1@1+ (1,0) [0|1] "" Vector__XXX

CM_ SG_ 213 EngTrqMin_Rq_SBC "EngTrqMin_Rq_SBC [source boolean]";
 SG_ EngTrq_Rq_SBC : 3|13@1+ (0.25,-500) [-500|1547.75] "Nm" Vector__XXX

CM_ SG_ 213 EngTrq_Rq_SBC "EngTrq_Rq_SBC";
 SG_ SSA_DsablPrmnt_Rq_SBC : 19|1@1+ (1,0) [0|1] "" Vector__XXX

CM_ SG_ 213 SSA_DsablPrmnt_Rq_SBC "SSA_DsablPrmnt_Rq_SBC [source boolean]";
 SG_ SSA_Enbl_Rq_SBC : 18|1@1+ (1,0) [0|1] "" Vector__XXX

CM_ SG_ 213 SSA_Enbl_Rq_SBC "SSA_Enbl_Rq_SBC [source boolean]";
 SG_ IntrvntnMd_SBC : 16|2@1+ (1,0) [0|3] "" Vector__XXX

CM_ SG_ 213 IntrvntnMd_SBC "IntrvntnMd_SBC [source enum/value-table reference]";
 SG_ MC_ENG_RQ_SBC : 48|4@1+ (1,0) [0|15] "" Vector__XXX

CM_ SG_ 213 MC_ENG_RQ_SBC "MC_ENG_RQ_SBC";
 SG_ CRC_ENG_RQ_SBC : 56|8@1+ (1,0) [0|255] "" Vector__XXX

CM_ SG_ 213 CRC_ENG_RQ_SBC "CRC_ENG_RQ_SBC";

BA_ "GenMsgCycleTime" BO_ 213 8;

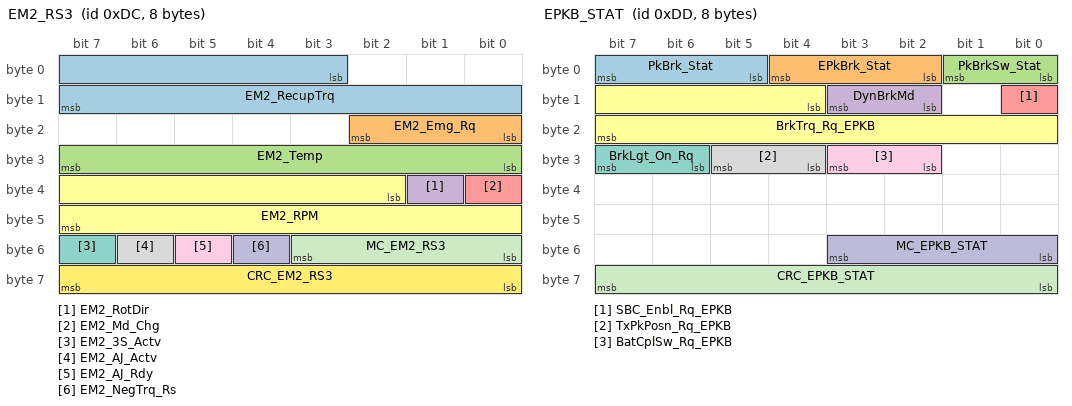
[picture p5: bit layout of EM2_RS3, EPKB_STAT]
BO_ 220 EM2_RS3: 8 ESP_ABR
 SG_ EM2_RecupTrq : 3|13@1+ (0.25,-500) [-500|1547.75] "Nm" Vector__XXX

CM_ SG_ 220 EM2_RecupTrq "EM2_RecupTrq";
 SG_ EM2_Emg_Rq : 16|3@1+ (1,0) [0|7] "" Vector__XXX

CM_ SG_ 220 EM2_Emg_Rq "EM2_Emg_Rq [source enum/value-table reference]";
 SG_ EM2_Temp : 24|8@1+ (1,-30) [-30|225] "degC" Vector__XXX

CM_ SG_ 220 EM2_Temp "EM2_Temp";
 SG_ EM2_RotDir : 33|1@1+ (1,0) [0|1] "" Vector__XXX

CM_ SG_ 220 EM2_RotDir "EM2_RotDir [source boolean]";
 SG_ EM2_Md_Chg : 32|1@1+ (1,0) [0|1] "" Vector__XXX

CM_ SG_ 220 EM2_Md_Chg "EM2_Md_Chg [source boolean]";
 SG_ EM2_RPM : 34|14@1+ (1,0) [0|16383] "rpm" Vector__XXX

CM_ SG_ 220 EM2_RPM "EM2_RPM";
 SG_ EM2_3S_Actv : 55|1@1+ (1,0) [0|1] "" Vector__XXX

CM_ SG_ 220 EM2_3S_Actv "EM2_3S_Actv [source boolean]";
 SG_ EM2_AJ_Actv : 54|1@1+ (1,0) [0|1] "" Vector__XXX

CM_ SG_ 220 EM2_AJ_Actv "EM2_AJ_Actv [source boolean]";
 SG_ EM2_AJ_Rdy : 53|1@1+ (1,0) [0|1] "" Vector__XXX

CM_ SG_ 220 EM2_AJ_Rdy "EM2_AJ_Rdy [source boolean]";
 SG_ EM2_NegTrq_Rs : 52|1@1+ (1,0) [0|1] "" Vector__XXX

CM_ SG_ 220 EM2_NegTrq_Rs "EM2_NegTrq_Rs [source boolean]";
 SG_ MC_EM2_RS3 : 48|4@1+ (1,0) [0|15] "" Vector__XXX

CM_ SG_ 220 MC_EM2_RS3 "MC_EM2_RS3";
 SG_ CRC_EM2_RS3 : 56|8@1+ (1,0) [0|255] "" Vector__XXX

CM_ SG_ 220 CRC_EM2_RS3 "CRC_EM2_RS3";

BA_ "GenMsgCycleTime" BO_ 220 12;

BO_ 221 EPKB_STAT: 8 ESP_ABR
 SG_ PkBrk_Stat : 5|3@1+ (1,0) [0|7] "" Vector__XXX

CM_ SG_ 221 PkBrk_Stat "PkBrk_Stat [source enum/value-table reference]";
 SG_ EPkBrk_Stat : 2|3@1+ (1,0) [0|7] "" Vector__XXX

CM_ SG_ 221 EPkBrk_Stat "EPkBrk_Stat [source enum/value-table reference]";
 SG_ PkBrkSw_Stat : 0|2@1+ (1,0) [0|3] "" Vector__XXX

CM_ SG_ 221 PkBrkSw_Stat "PkBrkSw_Stat [source enum/value-table reference]";
 SG_ DynBrkMd : 10|2@1+ (1,0) [0|3] "" Vector__XXX

CM_ SG_ 221 DynBrkMd "DynBrkMd [source enum/value-table reference]";
 SG_ SBC_Enbl_Rq_EPKB : 8|1@1+ (1,0) [0|1] "" Vector__XXX

CM_ SG_ 221 SBC_Enbl_Rq_EPKB "SBC_Enbl_Rq_EPKB [source boolean]";
 SG_ BrkTrq_Rq_EPKB : 12|12@1+ (3,0) [0|12285] "Nm" Vector__XXX

CM_ SG_ 221 BrkTrq_Rq_EPKB "BrkTrq_Rq_EPKB";
 SG_ BrkLgt_On_Rq : 30|2@1+ (1,0) [0|3] "" Vector__XXX

CM_ SG_ 221 BrkLgt_On_Rq "BrkLgt_On_Rq [source enum/value-table reference]";
 SG_ TxPkPosn_Rq_EPKB : 28|2@1+ (1,0) [0|3] "" Vector__XXX

CM_ SG_ 221 TxPkPosn_Rq_EPKB "TxPkPosn_Rq_EPKB [source enum/value-table reference]";
 SG_ BatCplSw_Rq_EPKB : 26|2@1+ (1,0) [0|3] "" Vector__XXX

CM_ SG_ 221 BatCplSw_Rq_EPKB "BatCplSw_Rq_EPKB [source enum/value-table reference]";
 SG_ MC_EPKB_STAT : 48|4@1+ (1,0) [0|15] "" Vector__XXX

CM_ SG_ 221 MC_EPKB_STAT "MC_EPKB_STAT";
 SG_ CRC_EPKB_STAT : 56|8@1+ (1,0) [0|255] "" Vector__XXX

CM_ SG_ 221 CRC_EPKB_STAT "CRC_EPKB_STAT";

BA_ "GenMsgCycleTime" BO_ 221 11;

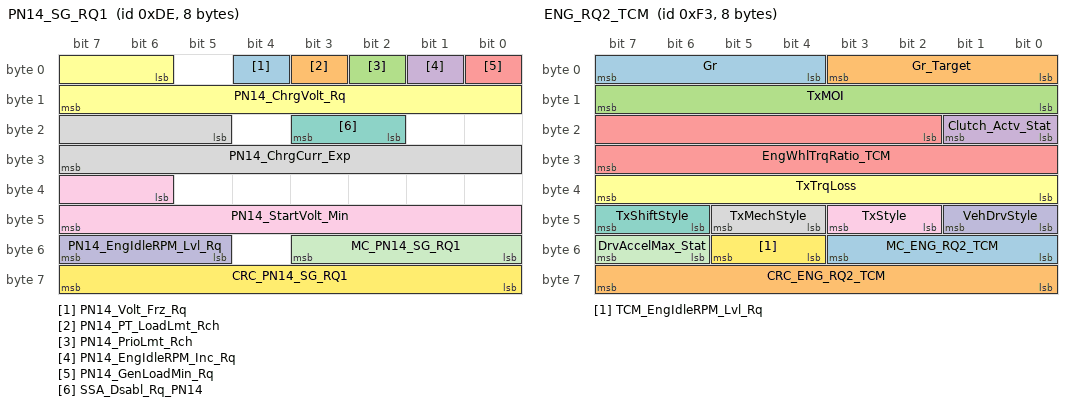
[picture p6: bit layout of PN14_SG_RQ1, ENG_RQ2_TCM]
BO_ 222 PN14_SG_RQ1: 8 ESP_ABR
 SG_ PN14_Volt_Frz_Rq : 4|1@1+ (1,0) [0|1] "" Vector__XXX

CM_ SG_ 222 PN14_Volt_Frz_Rq "PN14_Volt_Frz_Rq [source boolean]";
 SG_ PN14_PT_LoadLmt_Rch : 3|1@1+ (1,0) [0|1] "" Vector__XXX

CM_ SG_ 222 PN14_PT_LoadLmt_Rch "PN14_PT_LoadLmt_Rch [source boolean]";
 SG_ PN14_PrioLmt_Rch : 2|1@1+ (1,0) [0|1] "" Vector__XXX

CM_ SG_ 222 PN14_PrioLmt_Rch "PN14_PrioLmt_Rch [source boolean]";
 SG_ PN14_EngIdleRPM_Inc_Rq : 1|1@1+ (1,0) [0|1] "" Vector__XXX

CM_ SG_ 222 PN14_EngIdleRPM_Inc_Rq "PN14_EngIdleRPM_Inc_Rq [source boolean]";
 SG_ PN14_GenLoadMin_Rq : 0|1@1+ (1,0) [0|1] "" Vector__XXX

CM_ SG_ 222 PN14_GenLoadMin_Rq "PN14_GenLoadMin_Rq [source boolean]";
 SG_ PN14_ChrgVolt_Rq : 6|10@1+ (0.10000000149,0) [0|102.300001524] "V" Vector__XXX

CM_ SG_ 222 PN14_ChrgVolt_Rq "PN14_ChrgVolt_Rq";
 SG_ SSA_Dsabl_Rq_PN14 : 18|2@1+ (1,0) [0|3] "" Vector__XXX

CM_ SG_ 222 SSA_Dsabl_Rq_PN14 "SSA_Dsabl_Rq_PN14 [source enum/value-table reference]";
 SG_ PN14_ChrgCurr_Exp : 21|11@1+ (1,-1024) [-1024|1023] "A" Vector__XXX

CM_ SG_ 222 PN14_ChrgCurr_Exp "PN14_ChrgCurr_Exp";
 SG_ PN14_StartVolt_Min : 38|10@1+ (0.10000000149,0) [0|102.300001524] "V" Vector__XXX

CM_ SG_ 222 PN14_StartVolt_Min "PN14_StartVolt_Min";
 SG_ PN14_EngIdleRPM_Lvl_Rq : 53|3@1+ (1,0) [0|7] "" Vector__XXX

CM_ SG_ 222 PN14_EngIdleRPM_Lvl_Rq "PN14_EngIdleRPM_Lvl_Rq [source enum/value-table reference]";
 SG_ MC_PN14_SG_RQ1 : 48|4@1+ (1,0) [0|15] "" Vector__XXX

CM_ SG_ 222 MC_PN14_SG_RQ1 "MC_PN14_SG_RQ1";
 SG_ CRC_PN14_SG_RQ1 : 56|8@1+ (1,0) [0|255] "" Vector__XXX

CM_ SG_ 222 CRC_PN14_SG_RQ1 "CRC_PN14_SG_RQ1";

BA_ "GenMsgCycleTime" BO_ 222 12;

BO_ 243 ENG_RQ2_TCM: 8 ESP_ABR
 SG_ Gr : 4|4@1+ (1,0) [0|15] "" Vector__XXX

CM_ SG_ 243 Gr "Gr [source enum/value-table reference]";
 SG_ Gr_Target : 0|4@1+ (1,0) [0|15] "" Vector__XXX

CM_ SG_ 243 Gr_Target "Gr_Target [source enum/value-table reference]";
 SG_ TxMOI : 8|8@1+ (0.00999999977648,0) [0|2.549999943] "kgm2" Vector__XXX

CM_ SG_ 243 TxMOI "TxMOI";
 SG_ Clutch_Actv_Stat : 16|2@1+ (1,0) [0|3] "" Vector__XXX

CM_ SG_ 243 Clutch_Actv_Stat "Clutch_Actv_Stat [source enum/value-table reference]";
 SG_ EngWhlTrqRatio_TCM : 18|14@1+ (0.00999999977648,0) [0|163.829996338] "" Vector__XXX

CM_ SG_ 243 EngWhlTrqRatio_TCM "EngWhlTrqRatio_TCM";
 SG_ TxTrqLoss : 32|8@1+ (0.25,0) [0|63.75] "Nm" Vector__XXX

CM_ SG_ 243 TxTrqLoss "TxTrqLoss";
 SG_ TxShiftStyle : 46|2@1+ (1,0) [0|3] "" Vector__XXX

CM_ SG_ 243 TxShiftStyle "TxShiftStyle [source enum/value-table reference]";
 SG_ TxMechStyle : 44|2@1+ (1,0) [0|3] "" Vector__XXX

CM_ SG_ 243 TxMechStyle "TxMechStyle [source enum/value-table reference]";
 SG_ TxStyle : 42|2@1+ (1,0) [0|3] "" Vector__XXX

CM_ SG_ 243 TxStyle "TxStyle [source enum/value-table reference]";
 SG_ VehDrvStyle : 40|2@1+ (1,0) [0|3] "" Vector__XXX

CM_ SG_ 243 VehDrvStyle "VehDrvStyle [source enum/value-table reference]";
 SG_ DrvAccelMax_Stat : 54|2@1+ (1,0) [0|3] "" Vector__XXX

CM_ SG_ 243 DrvAccelMax_Stat "DrvAccelMax_Stat [source enum/value-table reference]";
 SG_ TCM_EngIdleRPM_Lvl_Rq : 52|2@1+ (1,0) [0|3] "" Vector__XXX

CM_ SG_ 243 TCM_EngIdleRPM_Lvl_Rq "TCM_EngIdleRPM_Lvl_Rq [source enum/value-table reference]";
 SG_ MC_ENG_RQ2_TCM : 48|4@1+ (1,0) [0|15] "" Vector__XXX

CM_ SG_ 243 MC_ENG_RQ2_TCM "MC_ENG_RQ2_TCM";
 SG_ CRC_ENG_RQ2_TCM : 56|8@1+ (1,0) [0|255] "" Vector__XXX

CM_ SG_ 243 CRC_ENG_RQ2_TCM "CRC_ENG_RQ2_TCM";

BA_ "GenMsgCycleTime" BO_ 243 14;

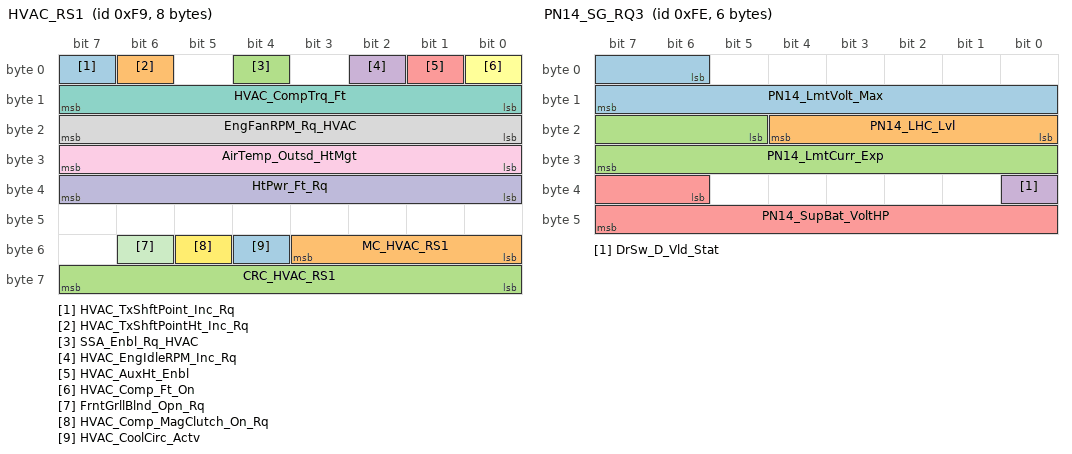
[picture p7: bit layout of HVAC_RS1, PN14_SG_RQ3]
BO_ 249 HVAC_RS1: 8 ESP_ABR
 SG_ HVAC_TxShftPoint_Inc_Rq : 7|1@1+ (1,0) [0|1] "" Vector__XXX

CM_ SG_ 249 HVAC_TxShftPoint_Inc_Rq "HVAC_TxShftPoint_Inc_Rq [source boolean]";
 SG_ HVAC_TxShftPointHt_Inc_Rq : 6|1@1+ (1,0) [0|1] "" Vector__XXX

CM_ SG_ 249 HVAC_TxShftPointHt_Inc_Rq "HVAC_TxShftPointHt_Inc_Rq [source boolean]";
 SG_ SSA_Enbl_Rq_HVAC : 4|1@1+ (1,0) [0|1] "" Vector__XXX

CM_ SG_ 249 SSA_Enbl_Rq_HVAC "SSA_Enbl_Rq_HVAC [source boolean]";
 SG_ HVAC_EngIdleRPM_Inc_Rq : 2|1@1+ (1,0) [0|1] "" Vector__XXX

CM_ SG_ 249 HVAC_EngIdleRPM_Inc_Rq "HVAC_EngIdleRPM_Inc_Rq [source boolean]";
 SG_ HVAC_AuxHt_Enbl : 1|1@1+ (1,0) [0|1] "" Vector__XXX

CM_ SG_ 249 HVAC_AuxHt_Enbl "HVAC_AuxHt_Enbl [source boolean]";
 SG_ HVAC_Comp_Ft_On : 0|1@1+ (1,0) [0|1] "" Vector__XXX

CM_ SG_ 249 HVAC_Comp_Ft_On "HVAC_Comp_Ft_On [source boolean]";
 SG_ HVAC_CompTrq_Ft : 8|8@1+ (0.25,0) [0|63.75] "Nm" Vector__XXX

CM_ SG_ 249 HVAC_CompTrq_Ft "HVAC_CompTrq_Ft";
 SG_ EngFanRPM_Rq_HVAC : 16|8@1+ (1,0) [0|255] "%" Vector__XXX

CM_ SG_ 249 EngFanRPM_Rq_HVAC "EngFanRPM_Rq_HVAC";
 SG_ AirTemp_Outsd_HtMgt : 24|8@1+ (0.5,-40) [-40|87.5] "degC" Vector__XXX

CM_ SG_ 249 AirTemp_Outsd_HtMgt "AirTemp_Outsd_HtMgt";
 SG_ HtPwr_Ft_Rq : 32|8@1+ (1,0) [0|255] "%" Vector__XXX

CM_ SG_ 249 HtPwr_Ft_Rq "HtPwr_Ft_Rq";
 SG_ FrntGrllBlnd_Opn_Rq : 54|1@1+ (1,0) [0|1] "" Vector__XXX

CM_ SG_ 249 FrntGrllBlnd_Opn_Rq "FrntGrllBlnd_Opn_Rq [source boolean]";
 SG_ HVAC_Comp_MagClutch_On_Rq : 53|1@1+ (1,0) [0|1] "" Vector__XXX

CM_ SG_ 249 HVAC_Comp_MagClutch_On_Rq "HVAC_Comp_MagClutch_On_Rq [source boolean]";
 SG_ HVAC_CoolCirc_Actv : 52|1@1+ (1,0) [0|1] "" Vector__XXX

CM_ SG_ 249 HVAC_CoolCirc_Actv "HVAC_CoolCirc_Actv [source boolean]";
 SG_ MC_HVAC_RS1 : 48|4@1+ (1,0) [0|15] "" Vector__XXX

CM_ SG_ 249 MC_HVAC_RS1 "MC_HVAC_RS1";
 SG_ CRC_HVAC_RS1 : 56|8@1+ (1,0) [0|255] "" Vector__XXX

CM_ SG_ 249 CRC_HVAC_RS1 "CRC_HVAC_RS1";

BA_ "GenMsgCycleTime" BO_ 249 15;

BO_ 254 PN14_SG_RQ3: 6 ESP_ABR
 SG_ PN14_LmtVolt_Max : 6|10@1+ (0.10000000149,0) [0|102.300001524] "V" Vector__XXX

CM_ SG_ 254 PN14_LmtVolt_Max "PN14_LmtVolt_Max";
 SG_ PN14_LHC_Lvl : 16|5@1+ (1,0) [0|31] "Steps" Vector__XXX

CM_ SG_ 254 PN14_LHC_Lvl "PN14_LHC_Lvl";
 SG_ PN14_LmtCurr_Exp : 21|11@1+ (1,-1024) [-1024|1023] "A" Vector__XXX

CM_ SG_ 254 PN14_LmtCurr_Exp "PN14_LmtCurr_Exp";
 SG_ DrSw_D_Vld_Stat : 32|1@1+ (1,0) [0|1] "" Vector__XXX

CM_ SG_ 254 DrSw_D_Vld_Stat "DrSw_D_Vld_Stat [source boolean]";
 SG_ PN14_SupBat_VoltHP : 38|10@1+ (0.0250000003725,0) [0|25.5750003811] "V" Vector__XXX

CM_ SG_ 254 PN14_SupBat_VoltHP "PN14_SupBat_VoltHP";

BA_ "GenMsgCycleTime" BO_ 254 5;

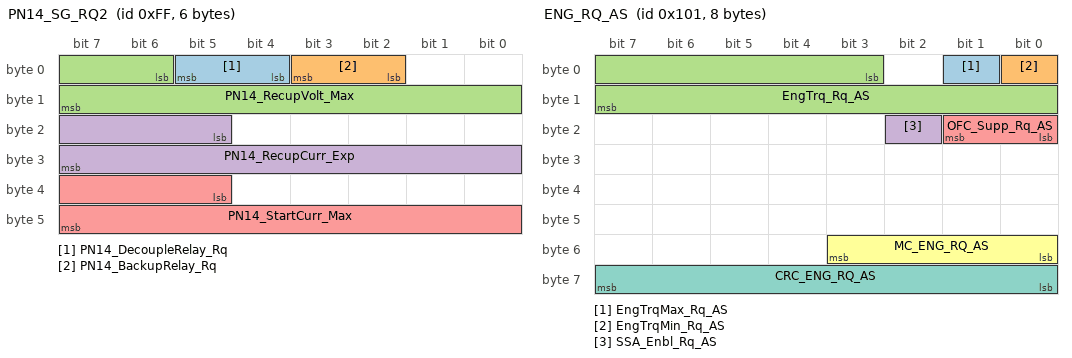
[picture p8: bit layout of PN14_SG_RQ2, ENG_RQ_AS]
BO_ 255 PN14_SG_RQ2: 6 ESP_ABR
 SG_ PN14_DecoupleRelay_Rq : 4|2@1+ (1,0) [0|3] "" Vector__XXX

CM_ SG_ 255 PN14_DecoupleRelay_Rq "PN14_DecoupleRelay_Rq [source enum/value-table reference]";
 SG_ PN14_BackupRelay_Rq : 2|2@1+ (1,0) [0|3] "" Vector__XXX

CM_ SG_ 255 PN14_BackupRelay_Rq "PN14_BackupRelay_Rq [source enum/value-table reference]";
 SG_ PN14_RecupVolt_Max : 6|10@1+ (0.10000000149,0) [0|102.300001524] "V" Vector__XXX

CM_ SG_ 255 PN14_RecupVolt_Max "PN14_RecupVolt_Max";
 SG_ PN14_RecupCurr_Exp : 21|11@1+ (1,-1024) [-1024|1023] "A" Vector__XXX

CM_ SG_ 255 PN14_RecupCurr_Exp "PN14_RecupCurr_Exp";
 SG_ PN14_StartCurr_Max : 37|11@1+ (1,-1024) [-1024|1023] "A" Vector__XXX

CM_ SG_ 255 PN14_StartCurr_Max "PN14_StartCurr_Max";

BA_ "GenMsgCycleTime" BO_ 255 5;

BO_ 257 ENG_RQ_AS: 8 ESP_ABR
 SG_ EngTrqMax_Rq_AS : 1|1@1+ (1,0) [0|1] "" Vector__XXX

CM_ SG_ 257 EngTrqMax_Rq_AS "EngTrqMax_Rq_AS [source boolean]";
 SG_ EngTrqMin_Rq_AS : 0|1@1+ (1,0) [0|1] "" Vector__XXX

CM_ SG_ 257 EngTrqMin_Rq_AS "EngTrqMin_Rq_AS [source boolean]";
 SG_ EngTrq_Rq_AS : 3|13@1+ (0.25,-500) [-500|1547.75] "Nm" Vector__XXX

CM_ SG_ 257 EngTrq_Rq_AS "EngTrq_Rq_AS";
 SG_ SSA_Enbl_Rq_AS : 18|1@1+ (1,0) [0|1] "" Vector__XXX

CM_ SG_ 257 SSA_Enbl_Rq_AS "SSA_Enbl_Rq_AS [source boolean]";
 SG_ OFC_Supp_Rq_AS : 16|2@1+ (1,0) [0|3] "" Vector__XXX

CM_ SG_ 257 OFC_Supp_Rq_AS "OFC_Supp_Rq_AS [source enum/value-table reference]";
 SG_ MC_ENG_RQ_AS : 48|4@1+ (1,0) [0|15] "" Vector__XXX

CM_ SG_ 257 MC_ENG_RQ_AS "MC_ENG_RQ_AS";
 SG_ CRC_ENG_RQ_AS : 56|8@1+ (1,0) [0|255] "" Vector__XXX

CM_ SG_ 257 CRC_ENG_RQ_AS "CRC_ENG_RQ_AS";

BA_ "GenMsgCycleTime" BO_ 257 7;

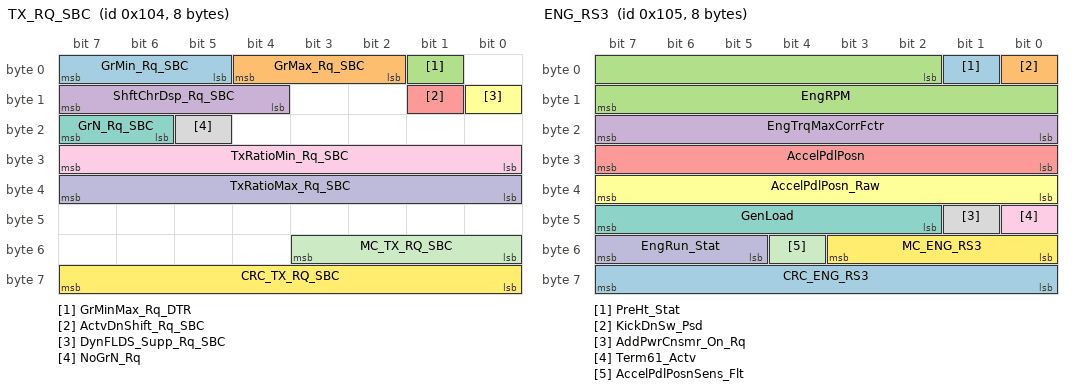
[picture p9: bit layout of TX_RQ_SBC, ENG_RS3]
BO_ 260 TX_RQ_SBC: 8 ESP_ABR
 SG_ GrMin_Rq_SBC : 5|3@1+ (1,0) [0|7] "" Vector__XXX

CM_ SG_ 260 GrMin_Rq_SBC "GrMin_Rq_SBC [source enum/value-table reference]";
 SG_ GrMax_Rq_SBC : 2|3@1+ (1,0) [0|7] "" Vector__XXX

CM_ SG_ 260 GrMax_Rq_SBC "GrMax_Rq_SBC [source enum/value-table reference]";
 SG_ GrMinMax_Rq_DTR : 1|1@1+ (1,0) [0|1] "" Vector__XXX

CM_ SG_ 260 GrMinMax_Rq_DTR "GrMinMax_Rq_DTR [source boolean]";
 SG_ ShftChrDsp_Rq_SBC : 12|4@1+ (1,0) [0|15] "" Vector__XXX

CM_ SG_ 260 ShftChrDsp_Rq_SBC "ShftChrDsp_Rq_SBC [source enum/value-table reference]";
 SG_ ActvDnShift_Rq_SBC : 9|1@1+ (1,0) [0|1] "" Vector__XXX

CM_ SG_ 260 ActvDnShift_Rq_SBC "ActvDnShift_Rq_SBC [source boolean]";
 SG_ DynFLDS_Supp_Rq_SBC : 8|1@1+ (1,0) [0|1] "" Vector__XXX

CM_ SG_ 260 DynFLDS_Supp_Rq_SBC "DynFLDS_Supp_Rq_SBC [source boolean]";
 SG_ GrN_Rq_SBC : 22|2@1+ (1,0) [0|3] "" Vector__XXX

CM_ SG_ 260 GrN_Rq_SBC "GrN_Rq_SBC [source enum/value-table reference]";
 SG_ NoGrN_Rq : 21|1@1+ (1,0) [0|1] "" Vector__XXX

CM_ SG_ 260 NoGrN_Rq "NoGrN_Rq [source boolean]";
 SG_ TxRatioMin_Rq_SBC : 24|8@1+ (0.019999999553,0) [0|5.09999988601] "" Vector__XXX

CM_ SG_ 260 TxRatioMin_Rq_SBC "TxRatioMin_Rq_SBC";
 SG_ TxRatioMax_Rq_SBC : 32|8@1+ (0.019999999553,0) [0|5.09999988601] "" Vector__XXX

CM_ SG_ 260 TxRatioMax_Rq_SBC "TxRatioMax_Rq_SBC";
 SG_ MC_TX_RQ_SBC : 48|4@1+ (1,0) [0|15] "" Vector__XXX

CM_ SG_ 260 MC_TX_RQ_SBC "MC_TX_RQ_SBC";
 SG_ CRC_TX_RQ_SBC : 56|8@1+ (1,0) [0|255] "" Vector__XXX

CM_ SG_ 260 CRC_TX_RQ_SBC "CRC_TX_RQ_SBC";

BA_ "GenMsgCycleTime" BO_ 260 12;

BO_ 261 ENG_RS3: 8 ESP_ABR
 SG_ PreHt_Stat : 1|1@1+ (1,0) [0|1] "" Vector__XXX

CM_ SG_ 261 PreHt_Stat "PreHt_Stat [source boolean]";
 SG_ KickDnSw_Psd : 0|1@1+ (1,0) [0|1] "" Vector__XXX

CM_ SG_ 261 KickDnSw_Psd "KickDnSw_Psd [source boolean]";
 SG_ EngRPM : 2|14@1+ (1,0) [0|16383] "rpm" Vector__XXX

CM_ SG_ 261 EngRPM "EngRPM";
 SG_ EngTrqMaxCorrFctr : 16|8@1+ (0.00779527565464,0) [0|1.98779529193] "" Vector__XXX

CM_ SG_ 261 EngTrqMaxCorrFctr "EngTrqMaxCorrFctr";
 SG_ AccelPdlPosn : 24|8@1+ (0.40000000596,0) [0|102.00000152] "%" Vector__XXX

CM_ SG_ 261 AccelPdlPosn "AccelPdlPosn";
 SG_ AccelPdlPosn_Raw : 32|8@1+ (0.40000000596,0) [0|102.00000152] "%" Vector__XXX

CM_ SG_ 261 AccelPdlPosn_Raw "AccelPdlPosn_Raw";
 SG_ GenLoad : 42|6@1+ (3.22580647469,0) [0|203.225807905] "%" Vector__XXX

CM_ SG_ 261 GenLoad "GenLoad";
 SG_ AddPwrCnsmr_On_Rq : 41|1@1+ (1,0) [0|1] "" Vector__XXX

CM_ SG_ 261 AddPwrCnsmr_On_Rq "AddPwrCnsmr_On_Rq [source boolean]";
 SG_ Term61_Actv : 40|1@1+ (1,0) [0|1] "" Vector__XXX

CM_ SG_ 261 Term61_Actv "Term61_Actv [source boolean]";
 SG_ EngRun_Stat : 53|3@1+ (1,0) [0|7] "" Vector__XXX

CM_ SG_ 261 EngRun_Stat "EngRun_Stat [source enum/value-table reference]";
 SG_ AccelPdlPosnSens_Flt : 52|1@1+ (1,0) [0|1] "" Vector__XXX

CM_ SG_ 261 AccelPdlPosnSens_Flt "AccelPdlPosnSens_Flt [source boolean]";
 SG_ MC_ENG_RS3 : 48|4@1+ (1,0) [0|15] "" Vector__XXX

CM_ SG_ 261 MC_ENG_RS3 "MC_ENG_RS3";
 SG_ CRC_ENG_RS3 : 56|8@1+ (1,0) [0|255] "" Vector__XXX

CM_ SG_ 261 CRC_ENG_RS3 "CRC_ENG_RS3";

BA_ "GenMsgCycleTime" BO_ 261 13;

BO_ 262 ENG_RQ_ABC: 8 ESP_ABR
 SG_ ABC_PmpTrq : 8|8@1+ (0.25,0) [0|63.75] "Nm" Vector__XXX

CM_ SG_ 262 ABC_PmpTrq "ABC_PmpTrq";
 SG_ MC_ENG_RQ_ABC : 48|4@1+ (1,0) [0|15] "" Vector__XXX

CM_ SG_ 262 MC_ENG_RQ_ABC "MC_ENG_RQ_ABC";
 SG_ CRC_ENG_RQ_ABC : 56|8@1+ (1,0) [0|255] "" Vector__XXX

CM_ SG_ 262 CRC_ENG_RQ_ABC "CRC_ENG_RQ_ABC";

BA_ "GenMsgCycleTime" BO_ 262 3;

BO_ 301 EIS_A2: 8 ESP_ABR
 SG_ KeyLine : 4|4@1+ (1,0) [0|15] "" Vector__XXX

CM_ SG_ 301 KeyLine "KeyLine";
 SG_ CLkS_Dsabl : 3|1@1+ (1,0) [0|1] "" Vector__XXX

CM_ SG_ 301 CLkS_Dsabl "CLkS_Dsabl [source boolean]";
 SG_ RemAlm_Rq_MPM : 2|1@1+ (1,0) [0|1] "" Vector__XXX

CM_ SG_ 301 RemAlm_Rq_MPM "RemAlm_Rq_MPM [source boolean]";
 SG_ PncAlm_On_Rq : 1|1@1+ (1,0) [0|1] "" Vector__XXX

CM_ SG_ 301 PncAlm_On_Rq "PncAlm_On_Rq [source boolean]";
 SG_ PncAlm_Off_Rq : 0|1@1+ (1,0) [0|1] "" Vector__XXX

CM_ SG_ 301 PncAlm_Off_Rq "PncAlm_Off_Rq [source boolean]";
 SG_ CLkS_Src : 12|4@1+ (1,0) [0|15] "" Vector__XXX

CM_ SG_ 301 CLkS_Src "CLkS_Src [source enum/value-table reference]";
 SG_ CLkS_TurnLmp_Unlk_Rq : 11|1@1+ (1,0) [0|1] "" Vector__XXX

CM_ SG_ 301 CLkS_TurnLmp_Unlk_Rq "CLkS_TurnLmp_Unlk_Rq [source boolean]";
 SG_ CLkS_TurnLmp_Lk_Rq : 10|1@1+ (1,0) [0|1] "" Vector__XXX

CM_ SG_ 301 CLkS_TurnLmp_Lk_Rq "CLkS_TurnLmp_Lk_Rq [source boolean]";
 SG_ Ext_Lk_Rq : 9|1@1+ (1,0) [0|1] "" Vector__XXX

CM_ SG_ 301 Ext_Lk_Rq "Ext_Lk_Rq [source boolean]";
 SG_ Ext_Unlk_Rq : 8|1@1+ (1,0) [0|1] "" Vector__XXX

CM_ SG_ 301 Ext_Unlk_Rq "Ext_Unlk_Rq [source boolean]";
 SG_ CLkS_Ovruse_Prot_Actv : 23|1@1+ (1,0) [0|1] "" Vector__XXX

CM_ SG_ 301 CLkS_Ovruse_Prot_Actv "CLkS_Ovruse_Prot_Actv [source boolean]";
 SG_ DL_Rem_Cls_Rq : 22|1@1+ (1,0) [0|1] "" Vector__XXX

CM_ SG_ 301 DL_Rem_Cls_Rq "DL_Rem_Cls_Rq [source boolean]";
 SG_ DL_Rem_Opn_Rq : 21|1@1+ (1,0) [0|1] "" Vector__XXX

CM_ SG_ 301 DL_Rem_Opn_Rq "DL_Rem_Opn_Rq [source boolean]";
 SG_ DL_Sp_Rq : 20|1@1+ (1,0) [0|1] "" Vector__XXX

CM_ SG_ 301 DL_Sp_Rq "DL_Sp_Rq [source boolean]";
 SG_ DL_Unlk_Rq : 19|1@1+ (1,0) [0|1] "" Vector__XXX

CM_ SG_ 301 DL_Unlk_Rq "DL_Unlk_Rq [source boolean]";
 SG_ DL_Lk_Rq : 18|1@1+ (1,0) [0|1] "" Vector__XXX

CM_ SG_ 301 DL_Lk_Rq "DL_Lk_Rq [source boolean]";
 SG_ Gas_Dr_Unlk_Rq : 17|1@1+ (1,0) [0|1] "" Vector__XXX

CM_ SG_ 301 Gas_Dr_Unlk_Rq "Gas_Dr_Unlk_Rq [source boolean]";
 SG_ Gas_Dr_Lk_Rq : 16|1@1+ (1,0) [0|1] "" Vector__XXX

CM_ SG_ 301 Gas_Dr_Lk_Rq "Gas_Dr_Lk_Rq [source boolean]";
 SG_ Dr_FL_Unlk_Rq : 31|1@1+ (1,0) [0|1] "" Vector__XXX

CM_ SG_ 301 Dr_FL_Unlk_Rq "Dr_FL_Unlk_Rq [source boolean]";
 SG_ Dr_FL_Lk_Rq : 30|1@1+ (1,0) [0|1] "" Vector__XXX

CM_ SG_ 301 Dr_FL_Lk_Rq "Dr_FL_Lk_Rq [source boolean]";
 SG_ Dr_FR_Unlk_Rq : 29|1@1+ (1,0) [0|1] "" Vector__XXX

CM_ SG_ 301 Dr_FR_Unlk_Rq "Dr_FR_Unlk_Rq [source boolean]";
 SG_ Dr_FR_Lk_Rq : 28|1@1+ (1,0) [0|1] "" Vector__XXX

CM_ SG_ 301 Dr_FR_Lk_Rq "Dr_FR_Lk_Rq [source boolean]";
 SG_ Dr_RL_Unlk_Rq : 27|1@1+ (1,0) [0|1] "" Vector__XXX

CM_ SG_ 301 Dr_RL_Unlk_Rq "Dr_RL_Unlk_Rq [source boolean]";
 SG_ Dr_RL_Lk_Rq : 26|1@1+ (1,0) [0|1] "" Vector__XXX

CM_ SG_ 301 Dr_RL_Lk_Rq "Dr_RL_Lk_Rq [source boolean]";
 SG_ Dr_RR_Unlk_Rq : 25|1@1+ (1,0) [0|1] "" Vector__XXX

CM_ SG_ 301 Dr_RR_Unlk_Rq "Dr_RR_Unlk_Rq [source boolean]";
 SG_ Dr_RR_Lk_Rq : 24|1@1+ (1,0) [0|1] "" Vector__XXX

CM_ SG_ 301 Dr_RR_Lk_Rq "Dr_RR_Lk_Rq [source boolean]";
 SG_ KeyId : 32|32@1+ (1,0) [0|4294967295] "" Vector__XXX

CM_ SG_ 301 KeyId "KeyId";

BA_ "GenMsgCycleTime" BO_ 301 27;

BO_ 307 DM_FL_A2: 4 ESP_ABR
 SG_ SeatPosn_FL_Fwd_Rq : 7|1@1+ (1,0) [0|1] "" Vector__XXX

CM_ SG_ 307 SeatPosn_FL_Fwd_Rq "SeatPosn_FL_Fwd_Rq [source boolean]";
 SG_ SeatPosn_FL_Rwd_Rq : 6|1@1+ (1,0) [0|1] "" Vector__XXX

CM_ SG_ 307 SeatPosn_FL_Rwd_Rq "SeatPosn_FL_Rwd_Rq [source boolean]";
 SG_ SeatHght_FL_UP_Rq : 5|1@1+ (1,0) [0|1] "" Vector__XXX

CM_ SG_ 307 SeatHght_FL_UP_Rq "SeatHght_FL_UP_Rq [source boolean]";
 SG_ SeatHght_FL_Dn_Rq : 4|1@1+ (1,0) [0|1] "" Vector__XXX

CM_ SG_ 307 SeatHght_FL_Dn_Rq "SeatHght_FL_Dn_Rq [source boolean]";
 SG_ SeatSwAdj_FL_Psd : 1|1@1+ (1,0) [0|1] "" Vector__XXX

CM_ SG_ 307 SeatSwAdj_FL_Psd "SeatSwAdj_FL_Psd [source boolean]";
 SG_ Seat_FL_Tgl : 0|1@1+ (1,0) [0|1] "" Vector__XXX

CM_ SG_ 307 Seat_FL_Tgl "Seat_FL_Tgl [source boolean]";
 SG_ SeatTilt_FL_Up_Rq : 15|1@1+ (1,0) [0|1] "" Vector__XXX

CM_ SG_ 307 SeatTilt_FL_Up_Rq "SeatTilt_FL_Up_Rq [source boolean]";
 SG_ SeatTilt_FL_Dn_Rq : 14|1@1+ (1,0) [0|1] "" Vector__XXX

CM_ SG_ 307 SeatTilt_FL_Dn_Rq "SeatTilt_FL_Dn_Rq [source boolean]";
 SG_ SeatCsn_FL_Fwd_Rq : 13|1@1+ (1,0) [0|1] "" Vector__XXX

CM_ SG_ 307 SeatCsn_FL_Fwd_Rq "SeatCsn_FL_Fwd_Rq [source boolean]";
 SG_ SeatCsn_FL_Rwd_Rq : 12|1@1+ (1,0) [0|1] "" Vector__XXX

CM_ SG_ 307 SeatCsn_FL_Rwd_Rq "SeatCsn_FL_Rwd_Rq [source boolean]";
 SG_ SeatBkRst_FL_Fwd_Rq : 11|1@1+ (1,0) [0|1] "" Vector__XXX

CM_ SG_ 307 SeatBkRst_FL_Fwd_Rq "SeatBkRst_FL_Fwd_Rq [source boolean]";
 SG_ SeatBkRst_FL_Rwd_Rq : 10|1@1+ (1,0) [0|1] "" Vector__XXX

CM_ SG_ 307 SeatBkRst_FL_Rwd_Rq "SeatBkRst_FL_Rwd_Rq [source boolean]";
 SG_ SeatHdRst_FL_Up_Rq : 9|1@1+ (1,0) [0|1] "" Vector__XXX

CM_ SG_ 307 SeatHdRst_FL_Up_Rq "SeatHdRst_FL_Up_Rq [source boolean]";
 SG_ SeatHdRst_FL_Dn_Rq : 8|1@1+ (1,0) [0|1] "" Vector__XXX

CM_ SG_ 307 SeatHdRst_FL_Dn_Rq "SeatHdRst_FL_Dn_Rq [source boolean]";
 SG_ MemPosn_FL : 20|2@1+ (1,0) [0|3] "" Vector__XXX

CM_ SG_ 307 MemPosn_FL "MemPosn_FL [source enum/value-table reference]";
 SG_ MemPosn_FL_Rc_Rq : 19|1@1+ (1,0) [0|1] "" Vector__XXX

CM_ SG_ 307 MemPosn_FL_Rc_Rq "MemPosn_FL_Rc_Rq [source boolean]";
 SG_ MemPosn_FL_Sv_Rq : 18|1@1+ (1,0) [0|1] "" Vector__XXX

CM_ SG_ 307 MemPosn_FL_Sv_Rq "MemPosn_FL_Sv_Rq [source boolean]";
 SG_ MirrAdjSw_Lt_Psd : 29|1@1+ (1,0) [0|1] "" Vector__XXX

CM_ SG_ 307 MirrAdjSw_Lt_Psd "MirrAdjSw_Lt_Psd [source boolean]";
 SG_ MirrPkPosn_Rt_Sv_Rq : 28|1@1+ (1,0) [0|1] "" Vector__XXX

CM_ SG_ 307 MirrPkPosn_Rt_Sv_Rq "MirrPkPosn_Rt_Sv_Rq [source boolean]";

BA_ "GenMsgCycleTime" BO_ 307 19;

BO_ 309 DM_FR_A2: 4 ESP_ABR
 SG_ SeatPosn_FR_Fwd_Rq : 7|1@1+ (1,0) [0|1] "" Vector__XXX

CM_ SG_ 309 SeatPosn_FR_Fwd_Rq "SeatPosn_FR_Fwd_Rq [source boolean]";
 SG_ SeatPosn_FR_Rwd_Rq : 6|1@1+ (1,0) [0|1] "" Vector__XXX

CM_ SG_ 309 SeatPosn_FR_Rwd_Rq "SeatPosn_FR_Rwd_Rq [source boolean]";
 SG_ SeatHght_FR_Up_Rq : 5|1@1+ (1,0) [0|1] "" Vector__XXX

CM_ SG_ 309 SeatHght_FR_Up_Rq "SeatHght_FR_Up_Rq [source boolean]";
 SG_ SeatHght_FR_Dn_Rq : 4|1@1+ (1,0) [0|1] "" Vector__XXX

CM_ SG_ 309 SeatHght_FR_Dn_Rq "SeatHght_FR_Dn_Rq [source boolean]";
 SG_ SeatSwAdj_FR_Psd : 1|1@1+ (1,0) [0|1] "" Vector__XXX

CM_ SG_ 309 SeatSwAdj_FR_Psd "SeatSwAdj_FR_Psd [source boolean]";
 SG_ Seat_FR_Tgl : 0|1@1+ (1,0) [0|1] "" Vector__XXX

CM_ SG_ 309 Seat_FR_Tgl "Seat_FR_Tgl [source boolean]";
 SG_ SeatTilt_FR_Up_Rq : 15|1@1+ (1,0) [0|1] "" Vector__XXX

CM_ SG_ 309 SeatTilt_FR_Up_Rq "SeatTilt_FR_Up_Rq [source boolean]";
 SG_ SeatTilt_FR_Dn_Rq : 14|1@1+ (1,0) [0|1] "" Vector__XXX

CM_ SG_ 309 SeatTilt_FR_Dn_Rq "SeatTilt_FR_Dn_Rq [source boolean]";
 SG_ SeatCsn_FR_Fwd_Rq : 13|1@1+ (1,0) [0|1] "" Vector__XXX

CM_ SG_ 309 SeatCsn_FR_Fwd_Rq "SeatCsn_FR_Fwd_Rq [source boolean]";
 SG_ SeatCsn_FR_Rwd_Rq : 12|1@1+ (1,0) [0|1] "" Vector__XXX

CM_ SG_ 309 SeatCsn_FR_Rwd_Rq "SeatCsn_FR_Rwd_Rq [source boolean]";
 SG_ SeatBkRst_FR_Fwd_Rq : 11|1@1+ (1,0) [0|1] "" Vector__XXX

CM_ SG_ 309 SeatBkRst_FR_Fwd_Rq "SeatBkRst_FR_Fwd_Rq [source boolean]";
 SG_ SeatBkRst_FR_Rwd_Rq : 10|1@1+ (1,0) [0|1] "" Vector__XXX

CM_ SG_ 309 SeatBkRst_FR_Rwd_Rq "SeatBkRst_FR_Rwd_Rq [source boolean]";
 SG_ SeatHdRst_FR_Up_Rq : 9|1@1+ (1,0) [0|1] "" Vector__XXX

CM_ SG_ 309 SeatHdRst_FR_Up_Rq "SeatHdRst_FR_Up_Rq [source boolean]";
 SG_ SeatHdRst_FR_Dn_Rq : 8|1@1+ (1,0) [0|1] "" Vector__XXX

CM_ SG_ 309 SeatHdRst_FR_Dn_Rq "SeatHdRst_FR_Dn_Rq [source boolean]";
 SG_ MemPosn_FR : 20|2@1+ (1,0) [0|3] "" Vector__XXX

CM_ SG_ 309 MemPosn_FR "MemPosn_FR [source enum/value-table reference]";
 SG_ MemPosn_FR_Rc_Rq : 19|1@1+ (1,0) [0|1] "" Vector__XXX

CM_ SG_ 309 MemPosn_FR_Rc_Rq "MemPosn_FR_Rc_Rq [source boolean]";
 SG_ MemPosn_FR_Sv_Rq : 18|1@1+ (1,0) [0|1] "" Vector__XXX

CM_ SG_ 309 MemPosn_FR_Sv_Rq "MemPosn_FR_Sv_Rq [source boolean]";
 SG_ MirrAdj_Rt_Stat : 30|2@1+ (1,0) [0|3] "" Vector__XXX

CM_ SG_ 309 MirrAdj_Rt_Stat "MirrAdj_Rt_Stat [source enum/value-table reference]";
 SG_ MirrAdjSw_Rt_Psd : 29|1@1+ (1,0) [0|1] "" Vector__XXX

CM_ SG_ 309 MirrAdjSw_Rt_Psd "MirrAdjSw_Rt_Psd [source boolean]";
 SG_ MirrPkPosn_Lt_Sv_Rq : 28|1@1+ (1,0) [0|1] "" Vector__XXX

CM_ SG_ 309 MirrPkPosn_Lt_Sv_Rq "MirrPkPosn_Lt_Sv_Rq [source boolean]";

BA_ "GenMsgCycleTime" BO_ 309 20;

BO_ 327 ECM_STAT: 1 ESP_ABR
 SG_ ECM_Rout_Stat : 6|2@1+ (1,0) [0|3] "" Vector__XXX

CM_ SG_ 327 ECM_Rout_Stat "ECM_Rout_Stat [source enum/value-table reference]";

BA_ "GenMsgCycleTime" BO_ 327 1;

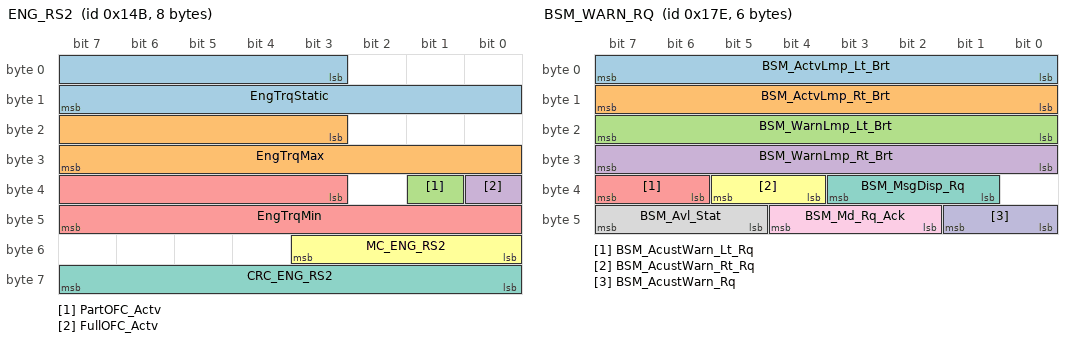
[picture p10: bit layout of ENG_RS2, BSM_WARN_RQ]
BO_ 331 ENG_RS2: 8 ESP_ABR
 SG_ EngTrqStatic : 3|13@1+ (0.25,-500) [-500|1547.75] "Nm" Vector__XXX

CM_ SG_ 331 EngTrqStatic "EngTrqStatic";
 SG_ EngTrqMax : 19|13@1+ (0.25,-500) [-500|1547.75] "Nm" Vector__XXX

CM_ SG_ 331 EngTrqMax "EngTrqMax";
 SG_ PartOFC_Actv : 33|1@1+ (1,0) [0|1] "" Vector__XXX

CM_ SG_ 331 PartOFC_Actv "PartOFC_Actv [source boolean]";
 SG_ FullOFC_Actv : 32|1@1+ (1,0) [0|1] "" Vector__XXX

CM_ SG_ 331 FullOFC_Actv "FullOFC_Actv [source boolean]";
 SG_ EngTrqMin : 35|13@1+ (0.25,-500) [-500|1547.75] "Nm" Vector__XXX

CM_ SG_ 331 EngTrqMin "EngTrqMin";
 SG_ MC_ENG_RS2 : 48|4@1+ (1,0) [0|15] "" Vector__XXX

CM_ SG_ 331 MC_ENG_RS2 "MC_ENG_RS2";
 SG_ CRC_ENG_RS2 : 56|8@1+ (1,0) [0|255] "" Vector__XXX

CM_ SG_ 331 CRC_ENG_RS2 "CRC_ENG_RS2";

BA_ "GenMsgCycleTime" BO_ 331 7;

BO_ 373 PRESF_CTRL_ESP: 8 ESP_ABR
 SG_ Presf_Enbl : 7|1@1+ (1,0) [0|1] "" Vector__XXX

CM_ SG_ 373 Presf_Enbl "Presf_Enbl [source boolean]";
 SG_ Presf_Stat_V2 : 3|4@1+ (1,0) [0|15] "" Vector__XXX

CM_ SG_ 373 Presf_Stat_V2 "Presf_Stat_V2 [source enum/value-table reference]";
 SG_ PresfGroup1_Adj_Rq : 2|1@1+ (1,0) [0|1] "" Vector__XXX

CM_ SG_ 373 PresfGroup1_Adj_Rq "PresfGroup1_Adj_Rq [source boolean]";
 SG_ PresfGroup2_Adj_Rq : 1|1@1+ (1,0) [0|1] "" Vector__XXX

CM_ SG_ 373 PresfGroup2_Adj_Rq "PresfGroup2_Adj_Rq [source boolean]";
 SG_ Presf_FricFctr_Lo : 0|1@1+ (1,0) [0|1] "" Vector__XXX

CM_ SG_ 373 Presf_FricFctr_Lo "Presf_FricFctr_Lo [source boolean]";
 SG_ PresfGroup2_Adj_Tgl : 15|1@1+ (1,0) [0|1] "" Vector__XXX

CM_ SG_ 373 PresfGroup2_Adj_Tgl "PresfGroup2_Adj_Tgl [source boolean]";
 SG_ PresfGroup2_AdjMd_Rq : 14|1@1+ (1,0) [0|1] "" Vector__XXX

CM_ SG_ 373 PresfGroup2_AdjMd_Rq "PresfGroup2_AdjMd_Rq [source boolean]";
 SG_ PresfGroup2_AdjDir_Rq : 13|1@1+ (1,0) [0|1] "" Vector__XXX

CM_ SG_ 373 PresfGroup2_AdjDir_Rq "PresfGroup2_AdjDir_Rq [source boolean]";
 SG_ PresfGroup2_AdjTSSR_Rq : 12|1@1+ (1,0) [0|1] "" Vector__XXX

CM_ SG_ 373 PresfGroup2_AdjTSSR_Rq "PresfGroup2_AdjTSSR_Rq [source boolean]";
 SG_ PresfGroup2_AdjWin_FL_Rq : 11|1@1+ (1,0) [0|1] "" Vector__XXX

CM_ SG_ 373 PresfGroup2_AdjWin_FL_Rq "PresfGroup2_AdjWin_FL_Rq [source boolean]";
 SG_ PresfGroup2_AdjWin_FR_Rq : 10|1@1+ (1,0) [0|1] "" Vector__XXX

CM_ SG_ 373 PresfGroup2_AdjWin_FR_Rq "PresfGroup2_AdjWin_FR_Rq [source boolean]";
 SG_ PresfGroup2_AdjWin_RL_Rq : 9|1@1+ (1,0) [0|1] "" Vector__XXX

CM_ SG_ 373 PresfGroup2_AdjWin_RL_Rq "PresfGroup2_AdjWin_RL_Rq [source boolean]";
 SG_ PresfGroup2_AdjWin_RR_Rq : 8|1@1+ (1,0) [0|1] "" Vector__XXX

CM_ SG_ 373 PresfGroup2_AdjWin_RR_Rq "PresfGroup2_AdjWin_RR_Rq [source boolean]";
 SG_ CMS_WarnLvl : 21|3@1+ (1,0) [0|7] "" Vector__XXX

CM_ SG_ 373 CMS_WarnLvl "CMS_WarnLvl [source enum/value-table reference]";
 SG_ Presf_Lvl : 28|4@1+ (1,0) [0|15] "" Vector__XXX

CM_ SG_ 373 Presf_Lvl "Presf_Lvl [source enum/value-table reference]";
 SG_ BltSlckDec_On_Rq : 52|1@1+ (1,0) [0|1] "" Vector__XXX

CM_ SG_ 373 BltSlckDec_On_Rq "BltSlckDec_On_Rq [source boolean]";
 SG_ MC_PRESF_CTRL_ESP : 48|4@1+ (1,0) [0|15] "" Vector__XXX

CM_ SG_ 373 MC_PRESF_CTRL_ESP "MC_PRESF_CTRL_ESP";
 SG_ CRC_PRESF_CTRL_ESP : 56|8@1+ (1,0) [0|255] "" Vector__XXX

CM_ SG_ 373 CRC_PRESF_CTRL_ESP "CRC_PRESF_CTRL_ESP";

BA_ "GenMsgCycleTime" BO_ 373 18;

BO_ 375 WIM_TELEAID: 1 ESP_ABR
 SG_ WarnPrio_Stat_TELEAID : 5|3@1+ (1,0) [0|7] "" Vector__XXX

CM_ SG_ 375 WarnPrio_Stat_TELEAID "WarnPrio_Stat_TELEAID [source enum/value-table reference]";
 SG_ AcustWarn_Actv_TELEAID : 4|1@1+ (1,0) [0|1] "" Vector__XXX

CM_ SG_ 375 AcustWarn_Actv_TELEAID "AcustWarn_Actv_TELEAID [source boolean]";
 SG_ WarnPrio_Wait_TELEAID : 1|3@1+ (1,0) [0|7] "" Vector__XXX

CM_ SG_ 375 WarnPrio_Wait_TELEAID "WarnPrio_Wait_TELEAID [source enum/value-table reference]";
 SG_ WarnPrio1_Mute_Rq_TELEAID : 0|1@1+ (1,0) [0|1] "" Vector__XXX

CM_ SG_ 375 WarnPrio1_Mute_Rq_TELEAID "WarnPrio1_Mute_Rq_TELEAID [source boolean]";

BA_ "GenMsgCycleTime" BO_ 375 4;

BO_ 376 NV_A1: 3 ESP_ABR
 SG_ IrLmp_On_Rq : 6|2@1+ (1,0) [0|3] "" Vector__XXX

CM_ SG_ 376 IrLmp_On_Rq "IrLmp_On_Rq [source enum/value-table reference]";
 SG_ HiBm_Off_Rq : 4|2@1+ (1,0) [0|3] "" Vector__XXX

CM_ SG_ 376 HiBm_Off_Rq "HiBm_Off_Rq [source enum/value-table reference]";
 SG_ NV_Sys_Stat : 11|5@1+ (1,0) [0|31] "" Vector__XXX

CM_ SG_ 376 NV_Sys_Stat "NV_Sys_Stat [source enum/value-table reference]";
 SG_ NV_Err_Stat : 8|3@1+ (1,0) [0|7] "" Vector__XXX

CM_ SG_ 376 NV_Err_Stat "NV_Err_Stat [source enum/value-table reference]";
 SG_ NV_Warn_Stat : 21|3@1+ (1,0) [0|7] "" Vector__XXX

CM_ SG_ 376 NV_Warn_Stat "NV_Warn_Stat [source enum/value-table reference]";

BA_ "GenMsgCycleTime" BO_ 376 5;

BO_ 378 EPKB_DISP_RQ: 2 ESP_ABR
 SG_ EPKB_Msg_Disp_Rq : 1|7@1+ (1,0) [0|127] "" Vector__XXX

CM_ SG_ 378 EPKB_Msg_Disp_Rq "EPKB_Msg_Disp_Rq [source enum/value-table reference]";
 SG_ EPKB_Msg_Disp_TrgrRq : 0|1@1+ (1,0) [0|1] "" Vector__XXX

CM_ SG_ 378 EPKB_Msg_Disp_TrgrRq "EPKB_Msg_Disp_TrgrRq [source boolean]";
 SG_ PkBrkIndLmp_On_Rq : 14|2@1+ (1,0) [0|3] "" Vector__XXX

CM_ SG_ 378 PkBrkIndLmp_On_Rq "PkBrkIndLmp_On_Rq [source enum/value-table reference]";
 SG_ BrkIndLmp_On_Rq_EPkB : 12|2@1+ (1,0) [0|3] "" Vector__XXX

CM_ SG_ 378 BrkIndLmp_On_Rq_EPkB "BrkIndLmp_On_Rq_EPkB [source enum/value-table reference]";

BA_ "GenMsgCycleTime" BO_ 378 4;

BO_ 379 ROOF_A3: 1 ESP_ABR
 SG_ Wpr_Stat : 4|4@1+ (1,0) [0|15] "Steps" Vector__XXX

CM_ SG_ 379 Wpr_Stat "Wpr_Stat";

BA_ "GenMsgCycleTime" BO_ 379 1;

BO_ 382 BSM_WARN_RQ: 6 ESP_ABR
 SG_ BSM_ActvLmp_Lt_Brt : 0|8@1+ (1,0) [0|255] "%" Vector__XXX

CM_ SG_ 382 BSM_ActvLmp_Lt_Brt "BSM_ActvLmp_Lt_Brt";
 SG_ BSM_ActvLmp_Rt_Brt : 8|8@1+ (1,0) [0|255] "%" Vector__XXX

CM_ SG_ 382 BSM_ActvLmp_Rt_Brt "BSM_ActvLmp_Rt_Brt";
 SG_ BSM_WarnLmp_Lt_Brt : 16|8@1+ (1,0) [0|255] "%" Vector__XXX

CM_ SG_ 382 BSM_WarnLmp_Lt_Brt "BSM_WarnLmp_Lt_Brt";
 SG_ BSM_WarnLmp_Rt_Brt : 24|8@1+ (1,0) [0|255] "%" Vector__XXX

CM_ SG_ 382 BSM_WarnLmp_Rt_Brt "BSM_WarnLmp_Rt_Brt";
 SG_ BSM_AcustWarn_Lt_Rq : 38|2@1+ (1,0) [0|3] "" Vector__XXX

CM_ SG_ 382 BSM_AcustWarn_Lt_Rq "BSM_AcustWarn_Lt_Rq [source enum/value-table reference]";
 SG_ BSM_AcustWarn_Rt_Rq : 36|2@1+ (1,0) [0|3] "" Vector__XXX

CM_ SG_ 382 BSM_AcustWarn_Rt_Rq "BSM_AcustWarn_Rt_Rq [source enum/value-table reference]";
 SG_ BSM_MsgDisp_Rq : 33|3@1+ (1,0) [0|7] "" Vector__XXX

CM_ SG_ 382 BSM_MsgDisp_Rq "BSM_MsgDisp_Rq [source enum/value-table reference]";
 SG_ BSM_Avl_Stat : 45|3@1+ (1,0) [0|7] "" Vector__XXX

CM_ SG_ 382 BSM_Avl_Stat "BSM_Avl_Stat [source enum/value-table reference]";
 SG_ BSM_Md_Rq_Ack : 42|3@1+ (1,0) [0|7] "" Vector__XXX

CM_ SG_ 382 BSM_Md_Rq_Ack "BSM_Md_Rq_Ack [source enum/value-table reference]";
 SG_ BSM_AcustWarn_Rq : 40|2@1+ (1,0) [0|3] "" Vector__XXX

CM_ SG_ 382 BSM_AcustWarn_Rq "BSM_AcustWarn_Rq [source enum/value-table reference]";

BA_ "GenMsgCycleTime" BO_ 382 10;

BO_ 384 RBTM_FL_STAT: 2 ESP_ABR
 SG_ RBT_FL_ComfCyc_Actv : 2|1@1+ (1,0) [0|1] "" Vector__XXX

CM_ SG_ 384 RBT_FL_ComfCyc_Actv "RBT_FL_ComfCyc_Actv [source boolean]";
 SG_ RBT_FL_SafeCyc_Actv : 1|1@1+ (1,0) [0|1] "" Vector__XXX

CM_ SG_ 384 RBT_FL_SafeCyc_Actv "RBT_FL_SafeCyc_Actv [source boolean]";
 SG_ Presf_FL_Tgl : 0|1@1+ (1,0) [0|1] "" Vector__XXX

CM_ SG_ 384 Presf_FL_Tgl "Presf_FL_Tgl [source boolean]";
 SG_ Presf_FL_Disp_Rq : 14|2@1+ (1,0) [0|3] "" Vector__XXX

CM_ SG_ 384 Presf_FL_Disp_Rq "Presf_FL_Disp_Rq [source enum/value-table reference]";

BA_ "GenMsgCycleTime" BO_ 384 4;

BO_ 385 RBTM_FR_STAT: 2 ESP_ABR
 SG_ RBT_FR_ComfCyc_Actv : 2|1@1+ (1,0) [0|1] "" Vector__XXX

CM_ SG_ 385 RBT_FR_ComfCyc_Actv "RBT_FR_ComfCyc_Actv [source boolean]";
 SG_ RBT_FR_SafeCyc_Actv : 1|1@1+ (1,0) [0|1] "" Vector__XXX

CM_ SG_ 385 RBT_FR_SafeCyc_Actv "RBT_FR_SafeCyc_Actv [source boolean]";
 SG_ Presf_FR_Tgl : 0|1@1+ (1,0) [0|1] "" Vector__XXX

CM_ SG_ 385 Presf_FR_Tgl "Presf_FR_Tgl [source boolean]";
 SG_ Presf_FR_Disp_Rq : 14|2@1+ (1,0) [0|3] "" Vector__XXX

CM_ SG_ 385 Presf_FR_Disp_Rq "Presf_FR_Disp_Rq [source enum/value-table reference]";

BA_ "GenMsgCycleTime" BO_ 385 4;

BO_ 387 PKAS_WARN_RQ: 7 ESP_ABR
 SG_ PKAS_Freq_Ft_Rq : 6|2@1+ (1,0) [0|3] "" Vector__XXX

CM_ SG_ 387 PKAS_Freq_Ft_Rq "PKAS_Freq_Ft_Rq [source enum/value-table reference]";
 SG_ PKAS_Vol_Ft_Rq : 4|2@1+ (1,0) [0|3] "" Vector__XXX

CM_ SG_ 387 PKAS_Vol_Ft_Rq "PKAS_Vol_Ft_Rq [source enum/value-table reference]";
 SG_ PKAS_AcustWarn_RL_Rq : 3|1@1+ (1,0) [0|1] "" Vector__XXX

CM_ SG_ 387 PKAS_AcustWarn_RL_Rq "PKAS_AcustWarn_RL_Rq [source boolean]";
 SG_ PKAS_AcustWarn_RR_Rq : 2|1@1+ (1,0) [0|1] "" Vector__XXX

CM_ SG_ 387 PKAS_AcustWarn_RR_Rq "PKAS_AcustWarn_RR_Rq [source boolean]";
 SG_ PKAS_Warn : 1|1@1+ (1,0) [0|1] "" Vector__XXX

CM_ SG_ 387 PKAS_Warn "PKAS_Warn [source boolean]";
 SG_ PKAS_Off : 0|1@1+ (1,0) [0|1] "" Vector__XXX

CM_ SG_ 387 PKAS_Off "PKAS_Off [source boolean]";
 SG_ PKAS_WarnLED1_FL_On_Rq : 14|1@1+ (1,0) [0|1] "" Vector__XXX

CM_ SG_ 387 PKAS_WarnLED1_FL_On_Rq "PKAS_WarnLED1_FL_On_Rq [source boolean]";
 SG_ PKAS_WarnLED2_FL_On_Rq : 13|1@1+ (1,0) [0|1] "" Vector__XXX

CM_ SG_ 387 PKAS_WarnLED2_FL_On_Rq "PKAS_WarnLED2_FL_On_Rq [source boolean]";
 SG_ PKAS_WarnLED3_FL_On_Rq : 12|1@1+ (1,0) [0|1] "" Vector__XXX

CM_ SG_ 387 PKAS_WarnLED3_FL_On_Rq "PKAS_WarnLED3_FL_On_Rq [source boolean]";
 SG_ PKAS_WarnLED4_FL_On_Rq : 11|1@1+ (1,0) [0|1] "" Vector__XXX

CM_ SG_ 387 PKAS_WarnLED4_FL_On_Rq "PKAS_WarnLED4_FL_On_Rq [source boolean]";
 SG_ PKAS_WarnLED5_FL_On_Rq : 10|1@1+ (1,0) [0|1] "" Vector__XXX

CM_ SG_ 387 PKAS_WarnLED5_FL_On_Rq "PKAS_WarnLED5_FL_On_Rq [source boolean]";
 SG_ PKAS_WarnFrm_FL_On_Rq : 8|1@1+ (1,0) [0|1] "" Vector__XXX

CM_ SG_ 387 PKAS_WarnFrm_FL_On_Rq "PKAS_WarnFrm_FL_On_Rq [source boolean]";
 SG_ PKAS_WarnLED6_FL_On_Rq : 22|2@1+ (1,0) [0|3] "" Vector__XXX

CM_ SG_ 387 PKAS_WarnLED6_FL_On_Rq "PKAS_WarnLED6_FL_On_Rq [source enum/value-table reference]";
 SG_ PKAS_WarnLED7_FL_On_Rq : 20|2@1+ (1,0) [0|3] "" Vector__XXX

CM_ SG_ 387 PKAS_WarnLED7_FL_On_Rq "PKAS_WarnLED7_FL_On_Rq [source enum/value-table reference]";
 SG_ PKAS_WarnLED6_FR_On_Rq : 18|2@1+ (1,0) [0|3] "" Vector__XXX

CM_ SG_ 387 PKAS_WarnLED6_FR_On_Rq "PKAS_WarnLED6_FR_On_Rq [source enum/value-table reference]";
 SG_ PKAS_WarnLED7_FR_On_Rq : 16|2@1+ (1,0) [0|3] "" Vector__XXX

CM_ SG_ 387 PKAS_WarnLED7_FR_On_Rq "PKAS_WarnLED7_FR_On_Rq [source enum/value-table reference]";
 SG_ PKAS_WarnLED1_FR_On_Rq : 30|1@1+ (1,0) [0|1] "" Vector__XXX

CM_ SG_ 387 PKAS_WarnLED1_FR_On_Rq "PKAS_WarnLED1_FR_On_Rq [source boolean]";
 SG_ PKAS_WarnLED2_FR_On_Rq : 29|1@1+ (1,0) [0|1] "" Vector__XXX

CM_ SG_ 387 PKAS_WarnLED2_FR_On_Rq "PKAS_WarnLED2_FR_On_Rq [source boolean]";
 SG_ PKAS_WarnLED3_FR_On_Rq : 28|1@1+ (1,0) [0|1] "" Vector__XXX

CM_ SG_ 387 PKAS_WarnLED3_FR_On_Rq "PKAS_WarnLED3_FR_On_Rq [source boolean]";
 SG_ PKAS_WarnLED4_FR_On_Rq : 27|1@1+ (1,0) [0|1] "" Vector__XXX

CM_ SG_ 387 PKAS_WarnLED4_FR_On_Rq "PKAS_WarnLED4_FR_On_Rq [source boolean]";
 SG_ PKAS_WarnLED5_FR_On_Rq : 26|1@1+ (1,0) [0|1] "" Vector__XXX

CM_ SG_ 387 PKAS_WarnLED5_FR_On_Rq "PKAS_WarnLED5_FR_On_Rq [source boolean]";
 SG_ PKAS_WarnFrm_FR_On_Rq : 24|1@1+ (1,0) [0|1] "" Vector__XXX

CM_ SG_ 387 PKAS_WarnFrm_FR_On_Rq "PKAS_WarnFrm_FR_On_Rq [source boolean]";
 SG_ PKAS_Snd_FL_Rq : 36|4@1+ (1,0) [0|15] "" Vector__XXX

CM_ SG_ 387 PKAS_Snd_FL_Rq "PKAS_Snd_FL_Rq [source enum/value-table reference]";
 SG_ PKAS_Snd_FR_Rq : 32|4@1+ (1,0) [0|15] "" Vector__XXX

CM_ SG_ 387 PKAS_Snd_FR_Rq "PKAS_Snd_FR_Rq [source enum/value-table reference]";
 SG_ PKAS_SwLED_Rq : 54|2@1+ (1,0) [0|3] "" Vector__XXX

CM_ SG_ 387 PKAS_SwLED_Rq "PKAS_SwLED_Rq [source enum/value-table reference]";
 SG_ PTS_SwLED_Rq : 52|2@1+ (1,0) [0|3] "" Vector__XXX

CM_ SG_ 387 PTS_SwLED_Rq "PTS_SwLED_Rq [source enum/value-table reference]";

BA_ "GenMsgCycleTime" BO_ 387 26;

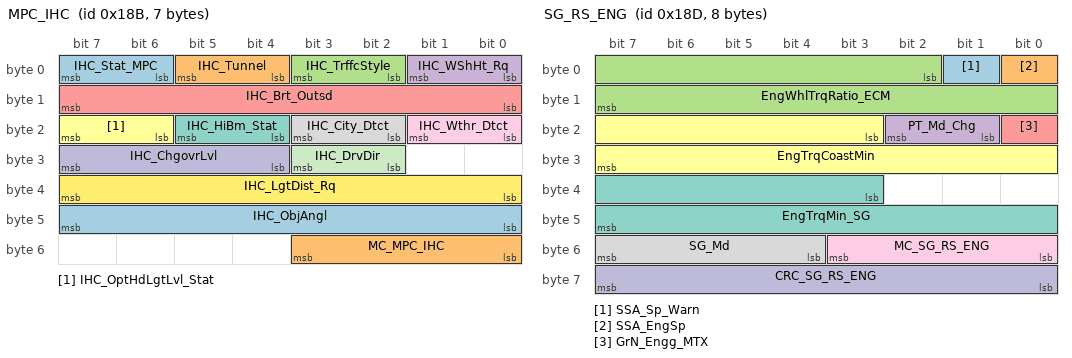
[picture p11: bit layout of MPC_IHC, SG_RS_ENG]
BO_ 395 MPC_IHC: 7 ESP_ABR
 SG_ IHC_Stat_MPC : 6|2@1+ (1,0) [0|3] "" Vector__XXX

CM_ SG_ 395 IHC_Stat_MPC "IHC_Stat_MPC [source enum/value-table reference]";
 SG_ IHC_Tunnel : 4|2@1+ (1,0) [0|3] "" Vector__XXX

CM_ SG_ 395 IHC_Tunnel "IHC_Tunnel [source enum/value-table reference]";
 SG_ IHC_TrffcStyle : 2|2@1+ (1,0) [0|3] "" Vector__XXX

CM_ SG_ 395 IHC_TrffcStyle "IHC_TrffcStyle [source enum/value-table reference]";
 SG_ IHC_WShHt_Rq : 0|2@1+ (1,0) [0|3] "" Vector__XXX

CM_ SG_ 395 IHC_WShHt_Rq "IHC_WShHt_Rq [source enum/value-table reference]";
 SG_ IHC_Brt_Outsd : 8|8@1+ (1,0) [0|255] "" Vector__XXX

CM_ SG_ 395 IHC_Brt_Outsd "IHC_Brt_Outsd";
 SG_ IHC_OptHdLgtLvl_Stat : 22|2@1+ (1,0) [0|3] "" Vector__XXX

CM_ SG_ 395 IHC_OptHdLgtLvl_Stat "IHC_OptHdLgtLvl_Stat [source enum/value-table reference]";
 SG_ IHC_HiBm_Stat : 20|2@1+ (1,0) [0|3] "" Vector__XXX

CM_ SG_ 395 IHC_HiBm_Stat "IHC_HiBm_Stat [source enum/value-table reference]";
 SG_ IHC_City_Dtct : 18|2@1+ (1,0) [0|3] "" Vector__XXX

CM_ SG_ 395 IHC_City_Dtct "IHC_City_Dtct [source enum/value-table reference]";
 SG_ IHC_Wthr_Dtct : 16|2@1+ (1,0) [0|3] "" Vector__XXX

CM_ SG_ 395 IHC_Wthr_Dtct "IHC_Wthr_Dtct [source enum/value-table reference]";
 SG_ IHC_ChgovrLvl : 28|4@1+ (1,0) [0|15] "" Vector__XXX

CM_ SG_ 395 IHC_ChgovrLvl "IHC_ChgovrLvl";
 SG_ IHC_DrvDir : 26|2@1+ (1,0) [0|3] "" Vector__XXX

CM_ SG_ 395 IHC_DrvDir "IHC_DrvDir [source enum/value-table reference]";
 SG_ IHC_LgtDist_Rq : 32|8@1+ (2.5,0) [0|637.5] "m" Vector__XXX

CM_ SG_ 395 IHC_LgtDist_Rq "IHC_LgtDist_Rq";
 SG_ IHC_ObjAngl : 40|8@1+ (0.20000000298,-20) [-20|31.00000076] "deg" Vector__XXX

CM_ SG_ 395 IHC_ObjAngl "IHC_ObjAngl";
 SG_ MC_MPC_IHC : 48|4@1+ (1,0) [0|15] "" Vector__XXX

CM_ SG_ 395 MC_MPC_IHC "MC_MPC_IHC";

BA_ "GenMsgCycleTime" BO_ 395 14;

BO_ 397 SG_RS_ENG: 8 ESP_ABR
 SG_ SSA_Sp_Warn : 1|1@1+ (1,0) [0|1] "" Vector__XXX

CM_ SG_ 397 SSA_Sp_Warn "SSA_Sp_Warn [source boolean]";
 SG_ SSA_EngSp : 0|1@1+ (1,0) [0|1] "" Vector__XXX

CM_ SG_ 397 SSA_EngSp "SSA_EngSp [source boolean]";
 SG_ EngWhlTrqRatio_ECM : 2|14@1+ (0.00999999977648,0) [0|163.829996338] "" Vector__XXX

CM_ SG_ 397 EngWhlTrqRatio_ECM "EngWhlTrqRatio_ECM";
 SG_ PT_Md_Chg : 17|2@1+ (1,0) [0|3] "" Vector__XXX

CM_ SG_ 397 PT_Md_Chg "PT_Md_Chg [source enum/value-table reference]";
 SG_ GrN_Engg_MTX : 16|1@1+ (1,0) [0|1] "" Vector__XXX

CM_ SG_ 397 GrN_Engg_MTX "GrN_Engg_MTX [source boolean]";
 SG_ EngTrqCoastMin : 19|13@1+ (0.25,-500) [-500|1547.75] "Nm" Vector__XXX

CM_ SG_ 397 EngTrqCoastMin "EngTrqCoastMin";
 SG_ EngTrqMin_SG : 35|13@1+ (0.25,-500) [-500|1547.75] "Nm" Vector__XXX

CM_ SG_ 397 EngTrqMin_SG "EngTrqMin_SG";
 SG_ SG_Md : 52|4@1+ (1,0) [0|15] "" Vector__XXX

CM_ SG_ 397 SG_Md "SG_Md [source enum/value-table reference]";
 SG_ MC_SG_RS_ENG : 48|4@1+ (1,0) [0|15] "" Vector__XXX

CM_ SG_ 397 MC_SG_RS_ENG "MC_SG_RS_ENG";
 SG_ CRC_SG_RS_ENG : 56|8@1+ (1,0) [0|255] "" Vector__XXX

CM_ SG_ 397 CRC_SG_RS_ENG "CRC_SG_RS_ENG";

BA_ "GenMsgCycleTime" BO_ 397 10;

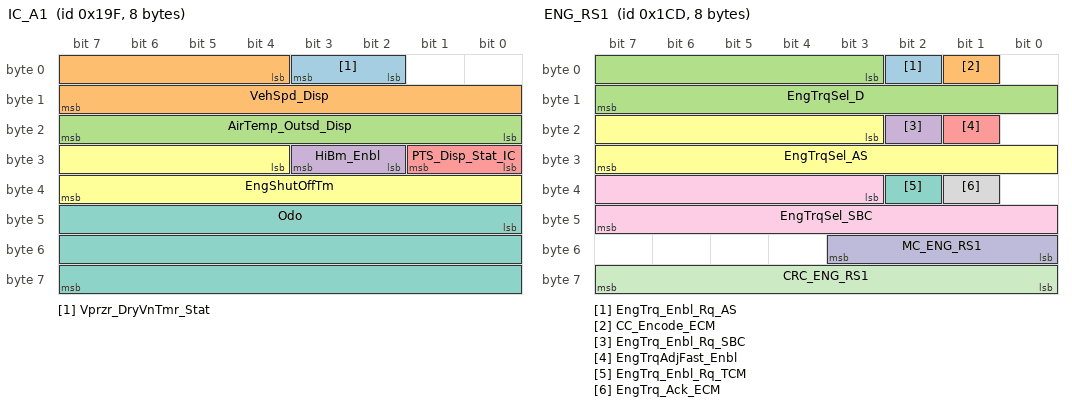
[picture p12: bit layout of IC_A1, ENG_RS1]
BO_ 415 IC_A1: 8 ESP_ABR
 SG_ Vprzr_DryVnTmr_Stat : 2|2@1+ (1,0) [0|3] "" Vector__XXX

CM_ SG_ 415 Vprzr_DryVnTmr_Stat "Vprzr_DryVnTmr_Stat [source enum/value-table reference]";
 SG_ VehSpd_Disp : 4|12@1+ (0.10000000149,0) [0|409.500006102] "km/h" Vector__XXX

CM_ SG_ 415 VehSpd_Disp "VehSpd_Disp";
 SG_ AirTemp_Outsd_Disp : 16|8@1+ (0.5,-40) [-40|87.5] "degC" Vector__XXX

CM_ SG_ 415 AirTemp_Outsd_Disp "AirTemp_Outsd_Disp";
 SG_ HiBm_Enbl : 26|2@1+ (1,0) [0|3] "" Vector__XXX

CM_ SG_ 415 HiBm_Enbl "HiBm_Enbl [source enum/value-table reference]";
 SG_ PTS_Disp_Stat_IC : 24|2@1+ (1,0) [0|3] "" Vector__XXX

CM_ SG_ 415 PTS_Disp_Stat_IC "PTS_Disp_Stat_IC [source enum/value-table reference]";
 SG_ EngShutOffTm : 28|12@1+ (1,0) [0|4095] "min" Vector__XXX

CM_ SG_ 415 EngShutOffTm "EngShutOffTm";
 SG_ Odo : 40|24@1+ (0.10000000149,0) [0|1677721.525] "km" Vector__XXX

CM_ SG_ 415 Odo "Odo";

BA_ "GenMsgCycleTime" BO_ 415 7;

BO_ 421 DM_FL_A4: 4 ESP_ABR
 SG_ PW_Oprtn_Actv_FL : 7|1@1+ (1,0) [0|1] "" Vector__XXX

CM_ SG_ 421 PW_Oprtn_Actv_FL "PW_Oprtn_Actv_FL [source boolean]";
 SG_ CC_Md_Rq_Dr_FL : 6|1@1+ (1,0) [0|1] "" Vector__XXX

CM_ SG_ 421 CC_Md_Rq_Dr_FL "CC_Md_Rq_Dr_FL [source boolean]";
 SG_ CC_Dir_Dr_FL : 5|1@1+ (1,0) [0|1] "" Vector__XXX

CM_ SG_ 421 CC_Dir_Dr_FL "CC_Dir_Dr_FL [source boolean]";
 SG_ CC_TSSR_Rq_Dr_FL : 4|1@1+ (1,0) [0|1] "" Vector__XXX

CM_ SG_ 421 CC_TSSR_Rq_Dr_FL "CC_TSSR_Rq_Dr_FL [source boolean]";
 SG_ CC_Win_FL_Rq_Dr_FL : 3|1@1+ (1,0) [0|1] "" Vector__XXX

CM_ SG_ 421 CC_Win_FL_Rq_Dr_FL "CC_Win_FL_Rq_Dr_FL [source boolean]";
 SG_ CC_Win_FR_Rq_Dr_FL : 2|1@1+ (1,0) [0|1] "" Vector__XXX

CM_ SG_ 421 CC_Win_FR_Rq_Dr_FL "CC_Win_FR_Rq_Dr_FL [source boolean]";
 SG_ CC_Win_RL_Rq_Dr_FL : 1|1@1+ (1,0) [0|1] "" Vector__XXX

CM_ SG_ 421 CC_Win_RL_Rq_Dr_FL "CC_Win_RL_Rq_Dr_FL [source boolean]";
 SG_ CC_Win_RR_Rq_Dr_FL : 0|1@1+ (1,0) [0|1] "" Vector__XXX

CM_ SG_ 421 CC_Win_RR_Rq_Dr_FL "CC_Win_RR_Rq_Dr_FL [source boolean]";
 SG_ PW_Adj_FL_Dr_FL : 13|3@1+ (1,0) [0|7] "" Vector__XXX

CM_ SG_ 421 PW_Adj_FL_Dr_FL "PW_Adj_FL_Dr_FL [source enum/value-table reference]";
 SG_ PW_Adj_FR_Dr_FL : 9|3@1+ (1,0) [0|7] "" Vector__XXX

CM_ SG_ 421 PW_Adj_FR_Dr_FL "PW_Adj_FR_Dr_FL [source enum/value-table reference]";
 SG_ PW_Adj_RL_Dr_FL : 21|3@1+ (1,0) [0|7] "" Vector__XXX

CM_ SG_ 421 PW_Adj_RL_Dr_FL "PW_Adj_RL_Dr_FL [source enum/value-table reference]";
 SG_ PW_Adj_RR_Dr_FL : 17|3@1+ (1,0) [0|7] "" Vector__XXX

CM_ SG_ 421 PW_Adj_RR_Dr_FL "PW_Adj_RR_Dr_FL [source enum/value-table reference]";
 SG_ MirrAdj_Rt_Lt : 31|1@1+ (1,0) [0|1] "" Vector__XXX

CM_ SG_ 421 MirrAdj_Rt_Lt "MirrAdj_Rt_Lt [source boolean]";
 SG_ MirrAdj_Rt_Rt : 30|1@1+ (1,0) [0|1] "" Vector__XXX

CM_ SG_ 421 MirrAdj_Rt_Rt "MirrAdj_Rt_Rt [source boolean]";
 SG_ MirrAdj_Rt_Up : 29|1@1+ (1,0) [0|1] "" Vector__XXX

CM_ SG_ 421 MirrAdj_Rt_Up "MirrAdj_Rt_Up [source boolean]";
 SG_ MirrAdj_Rt_Down : 28|1@1+ (1,0) [0|1] "" Vector__XXX

CM_ SG_ 421 MirrAdj_Rt_Down "MirrAdj_Rt_Down [source boolean]";
 SG_ MirrFld_Rt_Rq : 26|2@1+ (1,0) [0|3] "" Vector__XXX

CM_ SG_ 421 MirrFld_Rt_Rq "MirrFld_Rt_Rq [source enum/value-table reference]";

BA_ "GenMsgCycleTime" BO_ 421 17;

BO_ 423 DM_FR_A4: 4 ESP_ABR
 SG_ PW_Oprtn_Actv_FR : 7|1@1+ (1,0) [0|1] "" Vector__XXX

CM_ SG_ 423 PW_Oprtn_Actv_FR "PW_Oprtn_Actv_FR [source boolean]";
 SG_ CC_Md_Rq_Dr_FR : 6|1@1+ (1,0) [0|1] "" Vector__XXX

CM_ SG_ 423 CC_Md_Rq_Dr_FR "CC_Md_Rq_Dr_FR [source boolean]";
 SG_ CC_Dir_Dr_FR : 5|1@1+ (1,0) [0|1] "" Vector__XXX

CM_ SG_ 423 CC_Dir_Dr_FR "CC_Dir_Dr_FR [source boolean]";
 SG_ CC_TSSR_Rq_Dr_FR : 4|1@1+ (1,0) [0|1] "" Vector__XXX

CM_ SG_ 423 CC_TSSR_Rq_Dr_FR "CC_TSSR_Rq_Dr_FR [source boolean]";
 SG_ CC_Win_FL_Rq_Dr_FR : 3|1@1+ (1,0) [0|1] "" Vector__XXX

CM_ SG_ 423 CC_Win_FL_Rq_Dr_FR "CC_Win_FL_Rq_Dr_FR [source boolean]";
 SG_ CC_Win_FR_Rq_Dr_FR : 2|1@1+ (1,0) [0|1] "" Vector__XXX

CM_ SG_ 423 CC_Win_FR_Rq_Dr_FR "CC_Win_FR_Rq_Dr_FR [source boolean]";
 SG_ CC_Win_RL_Rq_Dr_FR : 1|1@1+ (1,0) [0|1] "" Vector__XXX

CM_ SG_ 423 CC_Win_RL_Rq_Dr_FR "CC_Win_RL_Rq_Dr_FR [source boolean]";
 SG_ CC_Win_RR_Rq_Dr_FR : 0|1@1+ (1,0) [0|1] "" Vector__XXX

CM_ SG_ 423 CC_Win_RR_Rq_Dr_FR "CC_Win_RR_Rq_Dr_FR [source boolean]";
 SG_ PW_Adj_FL_Dr_FR : 13|3@1+ (1,0) [0|7] "" Vector__XXX

CM_ SG_ 423 PW_Adj_FL_Dr_FR "PW_Adj_FL_Dr_FR [source enum/value-table reference]";
 SG_ PW_Adj_FR_Dr_FR : 9|3@1+ (1,0) [0|7] "" Vector__XXX

CM_ SG_ 423 PW_Adj_FR_Dr_FR "PW_Adj_FR_Dr_FR [source enum/value-table reference]";
 SG_ PW_Adj_RL_Dr_FR : 21|3@1+ (1,0) [0|7] "" Vector__XXX

CM_ SG_ 423 PW_Adj_RL_Dr_FR "PW_Adj_RL_Dr_FR [source enum/value-table reference]";
 SG_ PW_Adj_RR_Dr_FR : 17|3@1+ (1,0) [0|7] "" Vector__XXX

CM_ SG_ 423 PW_Adj_RR_Dr_FR "PW_Adj_RR_Dr_FR [source enum/value-table reference]";
 SG_ MirrAdj_Lt_Lt : 31|1@1+ (1,0) [0|1] "" Vector__XXX

CM_ SG_ 423 MirrAdj_Lt_Lt "MirrAdj_Lt_Lt [source boolean]";
 SG_ MirrAdj_Lt_Rt : 30|1@1+ (1,0) [0|1] "" Vector__XXX

CM_ SG_ 423 MirrAdj_Lt_Rt "MirrAdj_Lt_Rt [source boolean]";
 SG_ MirrAdj_Lt_Up : 29|1@1+ (1,0) [0|1] "" Vector__XXX

CM_ SG_ 423 MirrAdj_Lt_Up "MirrAdj_Lt_Up [source boolean]";
 SG_ MirrAdj_Lt_Down : 28|1@1+ (1,0) [0|1] "" Vector__XXX

CM_ SG_ 423 MirrAdj_Lt_Down "MirrAdj_Lt_Down [source boolean]";
 SG_ MirrFld_Lt_Rq : 26|2@1+ (1,0) [0|3] "" Vector__XXX

CM_ SG_ 423 MirrFld_Lt_Rq "MirrFld_Lt_Rq [source enum/value-table reference]";

BA_ "GenMsgCycleTime" BO_ 423 17;

BO_ 441 ECM_DAC: 8 ESP_ABR
 SG_ ECM_DAC : 0|64@1+ (1,0) [0|9.22337203685e+18] "" Vector__XXX

CM_ SG_ 441 ECM_DAC "ECM_DAC [source string/raw data]";

BA_ "GenMsgCycleTime" BO_ 441 1;

BO_ 449 WIM_IC: 4 ESP_ABR
 SG_ AcustWarn_Actv_IC : 4|1@1+ (1,0) [0|1] "" Vector__XXX

CM_ SG_ 449 AcustWarn_Actv_IC "AcustWarn_Actv_IC [source boolean]";
 SG_ WarnPrio1_Mute_Rq : 0|1@1+ (1,0) [0|1] "" Vector__XXX

CM_ SG_ 449 WarnPrio1_Mute_Rq "WarnPrio1_Mute_Rq [source boolean]";
 SG_ IC_Msg_Disp_Stat : 8|24@1+ (1,0) [0|16777215] "" Vector__XXX

CM_ SG_ 449 IC_Msg_Disp_Stat "IC_Msg_Disp_Stat";

BA_ "GenMsgCycleTime" BO_ 449 3;

BO_ 461 ENG_RS1: 8 ESP_ABR
 SG_ EngTrq_Enbl_Rq_AS : 2|1@1+ (1,0) [0|1] "" Vector__XXX

CM_ SG_ 461 EngTrq_Enbl_Rq_AS "EngTrq_Enbl_Rq_AS [source boolean]";
 SG_ CC_Encode_ECM : 1|1@1+ (1,0) [0|1] "" Vector__XXX

CM_ SG_ 461 CC_Encode_ECM "CC_Encode_ECM [source boolean]";
 SG_ EngTrqSel_D : 3|13@1+ (0.25,-500) [-500|1547.75] "Nm" Vector__XXX

CM_ SG_ 461 EngTrqSel_D "EngTrqSel_D";
 SG_ EngTrq_Enbl_Rq_SBC : 18|1@1+ (1,0) [0|1] "" Vector__XXX

CM_ SG_ 461 EngTrq_Enbl_Rq_SBC "EngTrq_Enbl_Rq_SBC [source boolean]";
 SG_ EngTrqAdjFast_Enbl : 17|1@1+ (1,0) [0|1] "" Vector__XXX

CM_ SG_ 461 EngTrqAdjFast_Enbl "EngTrqAdjFast_Enbl [source boolean]";
 SG_ EngTrqSel_AS : 19|13@1+ (0.25,-500) [-500|1547.75] "Nm" Vector__XXX

CM_ SG_ 461 EngTrqSel_AS "EngTrqSel_AS";
 SG_ EngTrq_Enbl_Rq_TCM : 34|1@1+ (1,0) [0|1] "" Vector__XXX

CM_ SG_ 461 EngTrq_Enbl_Rq_TCM "EngTrq_Enbl_Rq_TCM [source boolean]";
 SG_ EngTrq_Ack_ECM : 33|1@1+ (1,0) [0|1] "" Vector__XXX

CM_ SG_ 461 EngTrq_Ack_ECM "EngTrq_Ack_ECM [source boolean]";
 SG_ EngTrqSel_SBC : 35|13@1+ (0.25,-500) [-500|1547.75] "Nm" Vector__XXX

CM_ SG_ 461 EngTrqSel_SBC "EngTrqSel_SBC";
 SG_ MC_ENG_RS1 : 48|4@1+ (1,0) [0|15] "" Vector__XXX

CM_ SG_ 461 MC_ENG_RS1 "MC_ENG_RS1";
 SG_ CRC_ENG_RS1 : 56|8@1+ (1,0) [0|255] "" Vector__XXX

CM_ SG_ 461 CRC_ENG_RS1 "CRC_ENG_RS1";

BA_ "GenMsgCycleTime" BO_ 461 11;

BO_ 512 DPM_STAT: 1 ESP_ABR
 SG_ DPM_MdLmt_Rq : 6|2@1+ (1,0) [0|3] "" Vector__XXX

CM_ SG_ 512 DPM_MdLmt_Rq "DPM_MdLmt_Rq [source enum/value-table reference]";
 SG_ DPM_ExtMd_Enbl_Rq : 4|2@1+ (1,0) [0|3] "" Vector__XXX

CM_ SG_ 512 DPM_ExtMd_Enbl_Rq "DPM_ExtMd_Enbl_Rq [source enum/value-table reference]";

BA_ "GenMsgCycleTime" BO_ 512 2;

BO_ 513 WHL_STAT1: 8 ESP_ABR
 SG_ WhlPlsCnt_FL : 0|8@1+ (1,0) [0|255] "Impulses" Vector__XXX

CM_ SG_ 513 WhlPlsCnt_FL "WhlPlsCnt_FL";
 SG_ WhlPlsCnt_FR : 8|8@1+ (1,0) [0|255] "Impulses" Vector__XXX

CM_ SG_ 513 WhlPlsCnt_FR "WhlPlsCnt_FR";
 SG_ WhlPlsCnt_RL : 16|8@1+ (1,0) [0|255] "Impulses" Vector__XXX

CM_ SG_ 513 WhlPlsCnt_RL "WhlPlsCnt_RL";
 SG_ WhlPlsCnt_RR : 24|8@1+ (1,0) [0|255] "Impulses" Vector__XXX

CM_ SG_ 513 WhlPlsCnt_RR "WhlPlsCnt_RR";
 SG_ MC_WHL_STAT1 : 48|4@1+ (1,0) [0|15] "" Vector__XXX

CM_ SG_ 513 MC_WHL_STAT1 "MC_WHL_STAT1";
 SG_ CRC_WHL_STAT1 : 56|8@1+ (1,0) [0|255] "" Vector__XXX

CM_ SG_ 513 CRC_WHL_STAT1 "CRC_WHL_STAT1";

BA_ "GenMsgCycleTime" BO_ 513 6;

BO_ 514 ENG_ID: 4 ESP_ABR
 SG_ EngStyle : 0|8@1+ (1,0) [0|255] "" Vector__XXX

CM_ SG_ 514 EngStyle "EngStyle [source enum/value-table reference]";
 SG_ CRC_ENG_ID : 24|8@1+ (1,0) [0|255] "" Vector__XXX

CM_ SG_ 514 CRC_ENG_ID "CRC_ENG_ID";

BA_ "GenMsgCycleTime" BO_ 514 2;

BO_ 515 WHL_STAT2: 8 ESP_ABR
 SG_ WhlRPM_FL : 2|14@1+ (0.5,0) [0|8191.5] "rpm" Vector__XXX

CM_ SG_ 515 WhlRPM_FL "WhlRPM_FL";
 SG_ WhlRPM_FR : 18|14@1+ (0.5,0) [0|8191.5] "rpm" Vector__XXX

CM_ SG_ 515 WhlRPM_FR "WhlRPM_FR";
 SG_ WhlRPM_RL : 34|14@1+ (0.5,0) [0|8191.5] "rpm" Vector__XXX

CM_ SG_ 515 WhlRPM_RL "WhlRPM_RL";
 SG_ WhlRPM_RR : 50|14@1+ (0.5,0) [0|8191.5] "rpm" Vector__XXX

CM_ SG_ 515 WhlRPM_RR "WhlRPM_RR";

BA_ "GenMsgCycleTime" BO_ 515 4;

BO_ 516 VIN: 8 ESP_ABR
 SG_ VIN_MsgPart : 6|2@1+ (1,0) [0|3] "" Vector__XXX

CM_ SG_ 516 VIN_MsgPart "VIN_MsgPart [source enum/value-table reference]";
 SG_ VIN_Data : 8|56@1+ (1,0) [0|7.20575940379e+16] "" Vector__XXX

CM_ SG_ 516 VIN_Data "VIN_Data [source string/raw data]";

BA_ "GenMsgCycleTime" BO_ 516 2;

BO_ 517 PN14_STAT: 8 ESP_ABR
 SG_ PN14_BackupBat_Flt : 5|1@1+ (1,0) [0|1] "" Vector__XXX

CM_ SG_ 517 PN14_BackupBat_Flt "PN14_BackupBat_Flt [source boolean]";
 SG_ PN14_RemPerm : 3|1@1+ (1,0) [0|1] "" Vector__XXX

CM_ SG_ 517 PN14_RemPerm "PN14_RemPerm [source boolean]";
 SG_ PN14_RevBltTns_Off_Rq : 2|1@1+ (1,0) [0|1] "" Vector__XXX

CM_ SG_ 517 PN14_RevBltTns_Off_Rq "PN14_RevBltTns_Off_Rq [source boolean]";
 SG_ PN14_SBC_Add_Off_Rq : 1|1@1+ (1,0) [0|1] "" Vector__XXX

CM_ SG_ 517 PN14_SBC_Add_Off_Rq "PN14_SBC_Add_Off_Rq [source boolean]";
 SG_ PN14_SupBat_Volt : 8|8@1+ (0.10000000149,0) [0|25.50000038] "V" Vector__XXX

CM_ SG_ 517 PN14_SupBat_Volt "PN14_SupBat_Volt";
 SG_ PN14_SupBatCutSw_Stat : 22|2@1+ (1,0) [0|3] "" Vector__XXX

CM_ SG_ 517 PN14_SupBatCutSw_Stat "PN14_SupBatCutSw_Stat [source enum/value-table reference]";
 SG_ PN14_GM1_Actv : 21|1@1+ (1,0) [0|1] "" Vector__XXX

CM_ SG_ 517 PN14_GM1_Actv "PN14_GM1_Actv [source boolean]";
 SG_ PN14_GM1_Avl : 20|1@1+ (1,0) [0|1] "" Vector__XXX

CM_ SG_ 517 PN14_GM1_Avl "PN14_GM1_Avl [source boolean]";
 SG_ PN14_AS_Off_Rq : 30|2@1+ (1,0) [0|3] "" Vector__XXX

CM_ SG_ 517 PN14_AS_Off_Rq "PN14_AS_Off_Rq [source enum/value-table reference]";
 SG_ SPCR_Flt_PN14 : 28|2@1+ (1,0) [0|3] "" Vector__XXX

CM_ SG_ 517 SPCR_Flt_PN14 "SPCR_Flt_PN14 [source enum/value-table reference]";
 SG_ LHC_PosnLmp_Rq : 26|1@1+ (1,0) [0|1] "" Vector__XXX

CM_ SG_ 517 LHC_PosnLmp_Rq "LHC_PosnLmp_Rq [source boolean]";
 SG_ LHC_PkLmp_Rq : 25|1@1+ (1,0) [0|1] "" Vector__XXX

CM_ SG_ 517 LHC_PkLmp_Rq "LHC_PkLmp_Rq [source boolean]";
 SG_ PN14_LHC_Actv : 24|1@1+ (1,0) [0|1] "" Vector__XXX

CM_ SG_ 517 PN14_LHC_Actv "PN14_LHC_Actv [source boolean]";
 SG_ LHC_PTC6_Rq : 39|1@1+ (1,0) [0|1] "" Vector__XXX

CM_ SG_ 517 LHC_PTC6_Rq "LHC_PTC6_Rq [source boolean]";
 SG_ LHC_PTC5_Rq : 38|1@1+ (1,0) [0|1] "" Vector__XXX

CM_ SG_ 517 LHC_PTC5_Rq "LHC_PTC5_Rq [source boolean]";
 SG_ LHC_PTC4_Rq : 37|1@1+ (1,0) [0|1] "" Vector__XXX

CM_ SG_ 517 LHC_PTC4_Rq "LHC_PTC4_Rq [source boolean]";
 SG_ LHC_PTC3_Rq : 36|1@1+ (1,0) [0|1] "" Vector__XXX

CM_ SG_ 517 LHC_PTC3_Rq "LHC_PTC3_Rq [source boolean]";
 SG_ LHC_PTC2_Rq : 35|1@1+ (1,0) [0|1] "" Vector__XXX

CM_ SG_ 517 LHC_PTC2_Rq "LHC_PTC2_Rq [source boolean]";
 SG_ LHC_PTC1_Rq : 34|1@1+ (1,0) [0|1] "" Vector__XXX

CM_ SG_ 517 LHC_PTC1_Rq "LHC_PTC1_Rq [source boolean]";
 SG_ LHC_IntFan_R_50_Rq : 33|1@1+ (1,0) [0|1] "" Vector__XXX

CM_ SG_ 517 LHC_IntFan_R_50_Rq "LHC_IntFan_R_50_Rq [source boolean]";
 SG_ LHC_IntFan_F_50_Rq : 32|1@1+ (1,0) [0|1] "" Vector__XXX

CM_ SG_ 517 LHC_IntFan_F_50_Rq "LHC_IntFan_F_50_Rq [source boolean]";
 SG_ LHC_DSH_Stg2_Rq : 47|1@1+ (1,0) [0|1] "" Vector__XXX

CM_ SG_ 517 LHC_DSH_Stg2_Rq "LHC_DSH_Stg2_Rq [source boolean]";
 SG_ LHC_DSH_Stg1_Rq : 46|1@1+ (1,0) [0|1] "" Vector__XXX

CM_ SG_ 517 LHC_DSH_Stg1_Rq "LHC_DSH_Stg1_Rq [source boolean]";
 SG_ LHC_SeatHtStg3_Rq : 45|1@1+ (1,0) [0|1] "" Vector__XXX

CM_ SG_ 517 LHC_SeatHtStg3_Rq "LHC_SeatHtStg3_Rq [source boolean]";
 SG_ LHC_SeatHtStg2_Rq : 44|1@1+ (1,0) [0|1] "" Vector__XXX

CM_ SG_ 517 LHC_SeatHtStg2_Rq "LHC_SeatHtStg2_Rq [source boolean]";
 SG_ LHC_SeatHtStg1_Rq : 43|1@1+ (1,0) [0|1] "" Vector__XXX

CM_ SG_ 517 LHC_SeatHtStg1_Rq "LHC_SeatHtStg1_Rq [source boolean]";
 SG_ LHC_SeatVn_Rq : 42|1@1+ (1,0) [0|1] "" Vector__XXX

CM_ SG_ 517 LHC_SeatVn_Rq "LHC_SeatVn_Rq [source boolean]";
 SG_ LHC_Tlm_Rq : 41|1@1+ (1,0) [0|1] "" Vector__XXX

CM_ SG_ 517 LHC_Tlm_Rq "LHC_Tlm_Rq [source boolean]";
 SG_ LHC_TrlrSock_Rq : 40|1@1+ (1,0) [0|1] "" Vector__XXX

CM_ SG_ 517 LHC_TrlrSock_Rq "LHC_TrlrSock_Rq [source boolean]";
 SG_ LHC_WprPkHt_Rq : 55|1@1+ (1,0) [0|1] "" Vector__XXX

CM_ SG_ 517 LHC_WprPkHt_Rq "LHC_WprPkHt_Rq [source boolean]";
 SG_ LHC_EBL_Rq : 54|1@1+ (1,0) [0|1] "" Vector__XXX

CM_ SG_ 517 LHC_EBL_Rq "LHC_EBL_Rq [source boolean]";
 SG_ LHC_StW_Ht_Rq : 53|1@1+ (1,0) [0|1] "" Vector__XXX

CM_ SG_ 517 LHC_StW_Ht_Rq "LHC_StW_Ht_Rq [source boolean]";
 SG_ LHC_WShHt_Rq : 52|1@1+ (1,0) [0|1] "" Vector__XXX

CM_ SG_ 517 LHC_WShHt_Rq "LHC_WShHt_Rq [source boolean]";
 SG_ LHC_MirrHt_Rq : 51|1@1+ (1,0) [0|1] "" Vector__XXX

CM_ SG_ 517 LHC_MirrHt_Rq "LHC_MirrHt_Rq [source boolean]";
 SG_ LHC_CoolBox_R_Rq : 50|1@1+ (1,0) [0|1] "" Vector__XXX

CM_ SG_ 517 LHC_CoolBox_R_Rq "LHC_CoolBox_R_Rq [source boolean]";
 SG_ LHC_EngFan_50_Rq : 49|1@1+ (1,0) [0|1] "" Vector__XXX

CM_ SG_ 517 LHC_EngFan_50_Rq "LHC_EngFan_50_Rq [source boolean]";
 SG_ LHC_FogLmp_Ft_Rq : 48|1@1+ (1,0) [0|1] "" Vector__XXX

CM_ SG_ 517 LHC_FogLmp_Ft_Rq "LHC_FogLmp_Ft_Rq [source boolean]";
 SG_ LHC_TrkSock_Rq : 63|1@1+ (1,0) [0|1] "" Vector__XXX

CM_ SG_ 517 LHC_TrkSock_Rq "LHC_TrkSock_Rq [source boolean]";
 SG_ LHC_ComfLmp_Rq : 62|1@1+ (1,0) [0|1] "" Vector__XXX

CM_ SG_ 517 LHC_ComfLmp_Rq "LHC_ComfLmp_Rq [source boolean]";
 SG_ LHC_RHU_Rq : 61|1@1+ (1,0) [0|1] "" Vector__XXX

CM_ SG_ 517 LHC_RHU_Rq "LHC_RHU_Rq [source boolean]";
 SG_ LHC_ICH_Rq : 60|1@1+ (1,0) [0|1] "" Vector__XXX

CM_ SG_ 517 LHC_ICH_Rq "LHC_ICH_Rq [source boolean]";
 SG_ PN14_LHC_Taxi_Rq : 59|1@1+ (1,0) [0|1] "" Vector__XXX

CM_ SG_ 517 PN14_LHC_Taxi_Rq "PN14_LHC_Taxi_Rq [source boolean]";
 SG_ PN14_TransMd_Stat : 56|2@1+ (1,0) [0|3] "" Vector__XXX

CM_ SG_ 517 PN14_TransMd_Stat "PN14_TransMd_Stat [source enum/value-table reference]";

BA_ "GenMsgCycleTime" BO_ 517 43;

BO_ 518 AVI: 8 ESP_ABR
 SG_ TaxiPwrSup_Avl : 7|1@1+ (1,0) [0|1] "" Vector__XXX

CM_ SG_ 518 TaxiPwrSup_Avl "TaxiPwrSup_Avl [source boolean]";
 SG_ TaxiEmgAlm_Avl : 6|1@1+ (1,0) [0|1] "" Vector__XXX

CM_ SG_ 518 TaxiEmgAlm_Avl "TaxiEmgAlm_Avl [source boolean]";
 SG_ TaxiRoofLmpCon_Avl : 5|1@1+ (1,0) [0|1] "" Vector__XXX

CM_ SG_ 518 TaxiRoofLmpCon_Avl "TaxiRoofLmpCon_Avl [source boolean]";
 SG_ RadioHdFree_Avl : 3|1@1+ (1,0) [0|1] "" Vector__XXX

CM_ SG_ 518 RadioHdFree_Avl "RadioHdFree_Avl [source boolean]";
 SG_ ES_EmgVeh_Avl : 2|1@1+ (1,0) [0|1] "" Vector__XXX

CM_ SG_ 518 ES_EmgVeh_Avl "ES_EmgVeh_Avl [source boolean]";
 SG_ GAS_Avl : 0|1@1+ (1,0) [0|1] "" Vector__XXX

CM_ SG_ 518 GAS_Avl "GAS_Avl [source boolean]";
 SG_ EmgOpn_Inact : 15|1@1+ (1,0) [0|1] "" Vector__XXX

CM_ SG_ 518 EmgOpn_Inact "EmgOpn_Inact [source boolean]";
 SG_ RadioData_Avl : 14|1@1+ (1,0) [0|1] "" Vector__XXX

CM_ SG_ 518 RadioData_Avl "RadioData_Avl [source boolean]";
 SG_ VehHandi : 13|1@1+ (1,0) [0|1] "" Vector__XXX

CM_ SG_ 518 VehHandi "VehHandi [source boolean]";
 SG_ CMS2_Avl : 11|1@1+ (1,0) [0|1] "" Vector__XXX

CM_ SG_ 518 CMS2_Avl "CMS2_Avl [source boolean]";
 SG_ IHC_Plus_Avl : 10|1@1+ (1,0) [0|1] "" Vector__XXX

CM_ SG_ 518 IHC_Plus_Avl "IHC_Plus_Avl [source boolean]";
 SG_ KG_Avl : 23|1@1+ (1,0) [0|1] "" Vector__XXX

CM_ SG_ 518 KG_Avl "KG_Avl [source boolean]";
 SG_ PTS_Avl : 22|1@1+ (1,0) [0|1] "" Vector__XXX

CM_ SG_ 518 PTS_Avl "PTS_Avl [source boolean]";
 SG_ RB_R_Avl : 21|1@1+ (1,0) [0|1] "" Vector__XXX

CM_ SG_ 518 RB_R_Avl "RB_R_Avl [source boolean]";
 SG_ Mem_Avl : 20|1@1+ (1,0) [0|1] "" Vector__XXX

CM_ SG_ 518 Mem_Avl "Mem_Avl [source boolean]";
 SG_ XenonHL_Avl : 19|1@1+ (1,0) [0|1] "" Vector__XXX

CM_ SG_ 518 XenonHL_Avl "XenonHL_Avl [source boolean]";
 SG_ APC_Avl : 31|1@1+ (1,0) [0|1] "" Vector__XXX

CM_ SG_ 518 APC_Avl "APC_Avl [source boolean]";
 SG_ FTW_Avl : 30|1@1+ (1,0) [0|1] "" Vector__XXX

CM_ SG_ 518 FTW_Avl "FTW_Avl [source boolean]";
 SG_ PKAS_Avl : 29|1@1+ (1,0) [0|1] "" Vector__XXX

CM_ SG_ 518 PKAS_Avl "PKAS_Avl [source boolean]";
 SG_ CMS_Avl : 28|1@1+ (1,0) [0|1] "" Vector__XXX

CM_ SG_ 518 CMS_Avl "CMS_Avl [source boolean]";
 SG_ SLA_Avl : 27|1@1+ (1,0) [0|1] "" Vector__XXX

CM_ SG_ 518 SLA_Avl "SLA_Avl [source boolean]";
 SG_ BrkCC_Avl : 26|1@1+ (1,0) [0|1] "" Vector__XXX

CM_ SG_ 518 BrkCC_Avl "BrkCC_Avl [source boolean]";
 SG_ DTR_Avl : 25|1@1+ (1,0) [0|1] "" Vector__XXX

CM_ SG_ 518 DTR_Avl "DTR_Avl [source boolean]";
 SG_ NV_Avl : 24|1@1+ (1,0) [0|1] "" Vector__XXX

CM_ SG_ 518 NV_Avl "NV_Avl [source boolean]";
 SG_ BSM_Avl : 39|1@1+ (1,0) [0|1] "" Vector__XXX

CM_ SG_ 518 BSM_Avl "BSM_Avl [source boolean]";
 SG_ CURV_Avl : 38|1@1+ (1,0) [0|1] "" Vector__XXX

CM_ SG_ 518 CURV_Avl "CURV_Avl [source boolean]";
 SG_ ADTR_Avl : 37|1@1+ (1,0) [0|1] "" Vector__XXX

CM_ SG_ 518 ADTR_Avl "ADTR_Avl [source boolean]";
 SG_ APG_Avl : 36|1@1+ (1,0) [0|1] "" Vector__XXX

CM_ SG_ 518 APG_Avl "APG_Avl [source boolean]";
 SG_ TAPS_Avl : 34|1@1+ (1,0) [0|1] "" Vector__XXX

CM_ SG_ 518 TAPS_Avl "TAPS_Avl [source boolean]";
 SG_ IHC_Avl : 33|1@1+ (1,0) [0|1] "" Vector__XXX

CM_ SG_ 518 IHC_Avl "IHC_Avl [source boolean]";
 SG_ ALDW_Avl : 32|1@1+ (1,0) [0|1] "" Vector__XXX

CM_ SG_ 518 ALDW_Avl "ALDW_Avl [source boolean]";
 SG_ SeatBkRstAdj_R_Avl : 47|1@1+ (1,0) [0|1] "" Vector__XXX

CM_ SG_ 518 SeatBkRstAdj_R_Avl "SeatBkRstAdj_R_Avl [source boolean]";
 SG_ IdvdlSeat_R_Avl : 46|1@1+ (1,0) [0|1] "" Vector__XXX

CM_ SG_ 518 IdvdlSeat_R_Avl "IdvdlSeat_R_Avl [source boolean]";
 SG_ PTCM_Avl : 45|1@1+ (1,0) [0|1] "" Vector__XXX

CM_ SG_ 518 PTCM_Avl "PTCM_Avl [source boolean]";
 SG_ DL_AuxProt_Avl : 44|1@1+ (1,0) [0|1] "" Vector__XXX

CM_ SG_ 518 DL_AuxProt_Avl "DL_AuxProt_Avl [source boolean]";
 SG_ DrAuxProt_Avl : 43|1@1+ (1,0) [0|1] "" Vector__XXX

CM_ SG_ 518 DrAuxProt_Avl "DrAuxProt_Avl [source boolean]";
 SG_ TPM_Avl : 40|2@1+ (1,0) [0|3] "" Vector__XXX

CM_ SG_ 518 TPM_Avl "TPM_Avl [source enum/value-table reference]";
 SG_ VehFixMaxSpd : 48|8@1+ (1,0) [0|255] "km/h" Vector__XXX

CM_ SG_ 518 VehFixMaxSpd "VehFixMaxSpd";
 SG_ CRC_AVI : 56|8@1+ (1,0) [0|255] "" Vector__XXX

CM_ SG_ 518 CRC_AVI "CRC_AVI";

BA_ "GenMsgCycleTime" BO_ 518 39;

BO_ 519 CVI: 8 ESP_ABR
 SG_ Group : 4|4@1+ (1,0) [0|15] "" Vector__XXX

CM_ SG_ 519 Group "Group [source enum/value-table reference]";
 SG_ Country : 0|4@1+ (1,0) [0|15] "" Vector__XXX

CM_ SG_ 519 Country "Country [source enum/value-table reference]";
 SG_ VehLine : 10|6@1+ (1,0) [0|63] "" Vector__XXX

CM_ SG_ 519 VehLine "VehLine [source enum/value-table reference]";
 SG_ Guard : 8|2@1+ (1,0) [0|3] "" Vector__XXX

CM_ SG_ 519 Guard "Guard [source enum/value-table reference]";
 SG_ VehLinePack : 22|2@1+ (1,0) [0|3] "" Vector__XXX

CM_ SG_ 519 VehLinePack "VehLinePack [source enum/value-table reference]";
 SG_ VehLineYear : 17|5@1+ (1,0) [0|31] "" Vector__XXX

CM_ SG_ 519 VehLineYear "VehLineYear [source enum/value-table reference]";
 SG_ VSTS_Avl : 16|1@1+ (1,0) [0|1] "" Vector__XXX

CM_ SG_ 519 VSTS_Avl "VSTS_Avl [source boolean]";
 SG_ BodyStyle : 27|5@1+ (1,0) [0|31] "" Vector__XXX

CM_ SG_ 519 BodyStyle "BodyStyle [source enum/value-table reference]";
 SG_ StStyle : 25|2@1+ (1,0) [0|3] "" Vector__XXX

CM_ SG_ 519 StStyle "StStyle [source enum/value-table reference]";
 SG_ PSTS_Avl : 24|1@1+ (1,0) [0|1] "" Vector__XXX

CM_ SG_ 519 PSTS_Avl "PSTS_Avl [source boolean]";
 SG_ EngStyle : 32|8@1+ (1,0) [0|255] "" Vector__XXX

CM_ SG_ 519 EngStyle "EngStyle [source enum/value-table reference]";
 SG_ TCM_Avl : 47|1@1+ (1,0) [0|1] "" Vector__XXX

CM_ SG_ 519 TCM_Avl "TCM_Avl [source boolean]";
 SG_ HVAC_Avl : 46|1@1+ (1,0) [0|1] "" Vector__XXX

CM_ SG_ 519 HVAC_Avl "HVAC_Avl [source boolean]";
 SG_ TrlrHtch_Avl : 45|1@1+ (1,0) [0|1] "" Vector__XXX

CM_ SG_ 519 TrlrHtch_Avl "TrlrHtch_Avl [source boolean]";
 SG_ VTA_Avl : 44|1@1+ (1,0) [0|1] "" Vector__XXX

CM_ SG_ 519 VTA_Avl "VTA_Avl [source boolean]";
 SG_ PCD_Avl : 43|1@1+ (1,0) [0|1] "" Vector__XXX

CM_ SG_ 519 PCD_Avl "PCD_Avl [source boolean]";
 SG_ ICH_Avl : 42|1@1+ (1,0) [0|1] "" Vector__XXX

CM_ SG_ 519 ICH_Avl "ICH_Avl [source boolean]";
 SG_ LgtSens_Avl : 41|1@1+ (1,0) [0|1] "" Vector__XXX

CM_ SG_ 519 LgtSens_Avl "LgtSens_Avl [source boolean]";
 SG_ RainSens_Avl : 40|1@1+ (1,0) [0|1] "" Vector__XXX

CM_ SG_ 519 RainSens_Avl "RainSens_Avl [source boolean]";
 SG_ HVACStyle : 54|2@1+ (1,0) [0|3] "" Vector__XXX

CM_ SG_ 519 HVACStyle "HVACStyle [source enum/value-table reference]";
 SG_ VehOPTPack : 52|2@1+ (1,0) [0|3] "" Vector__XXX

CM_ SG_ 519 VehOPTPack "VehOPTPack [source enum/value-table reference]";
 SG_ Cplt_SL_Enbl : 51|1@1+ (1,0) [0|1] "" Vector__XXX

CM_ SG_ 519 Cplt_SL_Enbl "Cplt_SL_Enbl [source boolean]";
 SG_ RoofStyle : 48|3@1+ (1,0) [0|7] "" Vector__XXX

CM_ SG_ 519 RoofStyle "RoofStyle [source enum/value-table reference]";
 SG_ CRC_CVI : 56|8@1+ (1,0) [0|255] "" Vector__XXX

CM_ SG_ 519 CRC_CVI "CRC_CVI";

BA_ "GenMsgCycleTime" BO_ 519 24;

BO_ 520 AVI2: 8 ESP_ABR
 SG_ MirrFld_Avl : 7|1@1+ (1,0) [0|1] "" Vector__XXX

CM_ SG_ 520 MirrFld_Avl "MirrFld_Avl [source boolean]";
 SG_ Presf_Avl : 6|1@1+ (1,0) [0|1] "" Vector__XXX

CM_ SG_ 520 Presf_Avl "Presf_Avl [source boolean]";
 SG_ TELEAID_Avl : 5|1@1+ (1,0) [0|1] "" Vector__XXX

CM_ SG_ 520 TELEAID_Avl "TELEAID_Avl [source boolean]";
 SG_ PddlLmp_Avl : 4|1@1+ (1,0) [0|1] "" Vector__XXX

CM_ SG_ 520 PddlLmp_Avl "PddlLmp_Avl [source boolean]";
 SG_ WarnLmp_Avl : 3|1@1+ (1,0) [0|1] "" Vector__XXX

CM_ SG_ 520 WarnLmp_Avl "WarnLmp_Avl [source boolean]";
 SG_ EntrLmp_Avl : 2|1@1+ (1,0) [0|1] "" Vector__XXX

CM_ SG_ 520 EntrLmp_Avl "EntrLmp_Avl [source boolean]";
 SG_ Win_R_PartOpn : 1|1@1+ (1,0) [0|1] "" Vector__XXX

CM_ SG_ 520 Win_R_PartOpn "Win_R_PartOpn [source boolean]";
 SG_ ADC_Avl : 0|1@1+ (1,0) [0|1] "" Vector__XXX

CM_ SG_ 520 ADC_Avl "ADC_Avl [source boolean]";
 SG_ WinStyle : 14|2@1+ (1,0) [0|3] "" Vector__XXX

CM_ SG_ 520 WinStyle "WinStyle [source enum/value-table reference]";
 SG_ SpecVehPW_FL_Avl : 13|1@1+ (1,0) [0|1] "" Vector__XXX

CM_ SG_ 520 SpecVehPW_FL_Avl "SpecVehPW_FL_Avl [source boolean]";
 SG_ SpecVehPW_FR_Avl : 12|1@1+ (1,0) [0|1] "" Vector__XXX

CM_ SG_ 520 SpecVehPW_FR_Avl "SpecVehPW_FR_Avl [source boolean]";
 SG_ SpecVehPW_RL_Avl : 11|1@1+ (1,0) [0|1] "" Vector__XXX

CM_ SG_ 520 SpecVehPW_RL_Avl "SpecVehPW_RL_Avl [source boolean]";
 SG_ SpecVehPW_RR_Avl : 10|1@1+ (1,0) [0|1] "" Vector__XXX

CM_ SG_ 520 SpecVehPW_RR_Avl "SpecVehPW_RR_Avl [source boolean]";
 SG_ Mem_P_Avl : 9|1@1+ (1,0) [0|1] "" Vector__XXX

CM_ SG_ 520 Mem_P_Avl "Mem_P_Avl [source boolean]";
 SG_ AmbLgt_Avl : 23|1@1+ (1,0) [0|1] "" Vector__XXX

CM_ SG_ 520 AmbLgt_Avl "AmbLgt_Avl [source boolean]";
 SG_ SeatHt_R_Avl : 22|1@1+ (1,0) [0|1] "" Vector__XXX

CM_ SG_ 520 SeatHt_R_Avl "SeatHt_R_Avl [source boolean]";
 SG_ RoofLmpSup_PrmntActv : 21|1@1+ (1,0) [0|1] "" Vector__XXX

CM_ SG_ 520 RoofLmpSup_PrmntActv "RoofLmpSup_PrmntActv [source boolean]";
 SG_ SPCR_Style : 19|2@1+ (1,0) [0|3] "" Vector__XXX

CM_ SG_ 520 SPCR_Style "SPCR_Style [source enum/value-table reference]";
 SG_ LDP_Avl : 18|1@1+ (1,0) [0|1] "" Vector__XXX

CM_ SG_ 520 LDP_Avl "LDP_Avl [source boolean]";
 SG_ LCMS_Avl : 17|1@1+ (1,0) [0|1] "" Vector__XXX

CM_ SG_ 520 LCMS_Avl "LCMS_Avl [source boolean]";
 SG_ DTR_PlusLgt_Avl : 16|1@1+ (1,0) [0|1] "" Vector__XXX

CM_ SG_ 520 DTR_PlusLgt_Avl "DTR_PlusLgt_Avl [source boolean]";
 SG_ EM_Style : 26|6@1+ (1,0) [0|63] "" Vector__XXX

CM_ SG_ 520 EM_Style "EM_Style [source enum/value-table reference]";
 SG_ SSA_Avl : 24|1@1+ (1,0) [0|1] "" Vector__XXX

CM_ SG_ 520 SSA_Avl "SSA_Avl [source boolean]";
 SG_ ABC_Avl : 39|1@1+ (1,0) [0|1] "" Vector__XXX

CM_ SG_ 520 ABC_Avl "ABC_Avl [source boolean]";
 SG_ DualView_Avl : 38|1@1+ (1,0) [0|1] "" Vector__XXX

CM_ SG_ 520 DualView_Avl "DualView_Avl [source boolean]";
 SG_ PS_Style : 46|2@1+ (1,0) [0|3] "" Vector__XXX

CM_ SG_ 520 PS_Style "PS_Style [source enum/value-table reference]";
 SG_ STA_Avl : 45|1@1+ (1,0) [0|1] "" Vector__XXX

CM_ SG_ 520 STA_Avl "STA_Avl [source boolean]";
 SG_ AmbLgt_BiCol_Avl : 43|1@1+ (1,0) [0|1] "" Vector__XXX

CM_ SG_ 520 AmbLgt_BiCol_Avl "AmbLgt_BiCol_Avl [source boolean]";
 SG_ CRC_AVI2 : 56|8@1+ (1,0) [0|255] "" Vector__XXX

CM_ SG_ 520 CRC_AVI2 "CRC_AVI2";

BA_ "GenMsgCycleTime" BO_ 520 29;

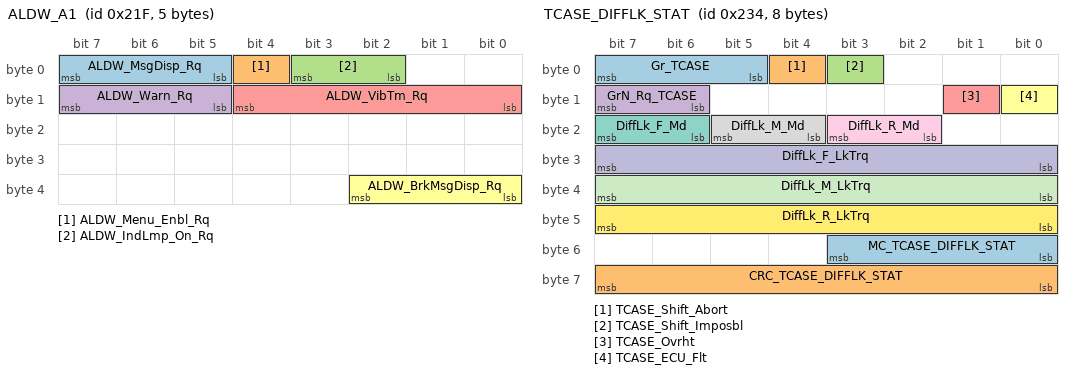
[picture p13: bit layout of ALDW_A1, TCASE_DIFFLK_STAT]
BO_ 543 ALDW_A1: 5 ESP_ABR
 SG_ ALDW_MsgDisp_Rq : 5|3@1+ (1,0) [0|7] "" Vector__XXX

CM_ SG_ 543 ALDW_MsgDisp_Rq "ALDW_MsgDisp_Rq [source enum/value-table reference]";
 SG_ ALDW_Menu_Enbl_Rq : 4|1@1+ (1,0) [0|1] "" Vector__XXX

CM_ SG_ 543 ALDW_Menu_Enbl_Rq "ALDW_Menu_Enbl_Rq [source boolean]";
 SG_ ALDW_IndLmp_On_Rq : 2|2@1+ (1,0) [0|3] "" Vector__XXX

CM_ SG_ 543 ALDW_IndLmp_On_Rq "ALDW_IndLmp_On_Rq [source enum/value-table reference]";
 SG_ ALDW_Warn_Rq : 13|3@1+ (1,0) [0|7] "" Vector__XXX

CM_ SG_ 543 ALDW_Warn_Rq "ALDW_Warn_Rq [source enum/value-table reference]";
 SG_ ALDW_VibTm_Rq : 8|5@1+ (1,0) [0|31] "ms" Vector__XXX

CM_ SG_ 543 ALDW_VibTm_Rq "ALDW_VibTm_Rq [source enum/value-table reference]";
 SG_ ALDW_BrkMsgDisp_Rq : 32|3@1+ (1,0) [0|7] "" Vector__XXX

CM_ SG_ 543 ALDW_BrkMsgDisp_Rq "ALDW_BrkMsgDisp_Rq [source enum/value-table reference]";

BA_ "GenMsgCycleTime" BO_ 543 6;

BO_ 564 TCASE_DIFFLK_STAT: 8 ESP_ABR
 SG_ Gr_TCASE : 5|3@1+ (1,0) [0|7] "" Vector__XXX

CM_ SG_ 564 Gr_TCASE "Gr_TCASE [source enum/value-table reference]";
 SG_ TCASE_Shift_Abort : 4|1@1+ (1,0) [0|1] "" Vector__XXX

CM_ SG_ 564 TCASE_Shift_Abort "TCASE_Shift_Abort [source boolean]";
 SG_ TCASE_Shift_Imposbl : 3|1@1+ (1,0) [0|1] "" Vector__XXX

CM_ SG_ 564 TCASE_Shift_Imposbl "TCASE_Shift_Imposbl [source boolean]";
 SG_ GrN_Rq_TCASE : 14|2@1+ (1,0) [0|3] "" Vector__XXX

CM_ SG_ 564 GrN_Rq_TCASE "GrN_Rq_TCASE [source enum/value-table reference]";
 SG_ TCASE_Ovrht : 9|1@1+ (1,0) [0|1] "" Vector__XXX

CM_ SG_ 564 TCASE_Ovrht "TCASE_Ovrht [source boolean]";
 SG_ TCASE_ECU_Flt : 8|1@1+ (1,0) [0|1] "" Vector__XXX

CM_ SG_ 564 TCASE_ECU_Flt "TCASE_ECU_Flt [source boolean]";
 SG_ DiffLk_F_Md : 22|2@1+ (1,0) [0|3] "" Vector__XXX

CM_ SG_ 564 DiffLk_F_Md "DiffLk_F_Md [source enum/value-table reference]";
 SG_ DiffLk_M_Md : 20|2@1+ (1,0) [0|3] "" Vector__XXX

CM_ SG_ 564 DiffLk_M_Md "DiffLk_M_Md [source enum/value-table reference]";
 SG_ DiffLk_R_Md : 18|2@1+ (1,0) [0|3] "" Vector__XXX

CM_ SG_ 564 DiffLk_R_Md "DiffLk_R_Md [source enum/value-table reference]";
 SG_ DiffLk_F_LkTrq : 24|8@1+ (10,0) [0|2550] "Nm" Vector__XXX

CM_ SG_ 564 DiffLk_F_LkTrq "DiffLk_F_LkTrq";
 SG_ DiffLk_M_LkTrq : 32|8@1+ (10,0) [0|2550] "Nm" Vector__XXX

CM_ SG_ 564 DiffLk_M_LkTrq "DiffLk_M_LkTrq";
 SG_ DiffLk_R_LkTrq : 40|8@1+ (10,0) [0|2550] "Nm" Vector__XXX

CM_ SG_ 564 DiffLk_R_LkTrq "DiffLk_R_LkTrq";
 SG_ MC_TCASE_DIFFLK_STAT : 48|4@1+ (1,0) [0|15] "" Vector__XXX

CM_ SG_ 564 MC_TCASE_DIFFLK_STAT "MC_TCASE_DIFFLK_STAT";
 SG_ CRC_TCASE_DIFFLK_STAT : 56|8@1+ (1,0) [0|255] "" Vector__XXX

CM_ SG_ 564 CRC_TCASE_DIFFLK_STAT "CRC_TCASE_DIFFLK_STAT";

BA_ "GenMsgCycleTime" BO_ 564 14;

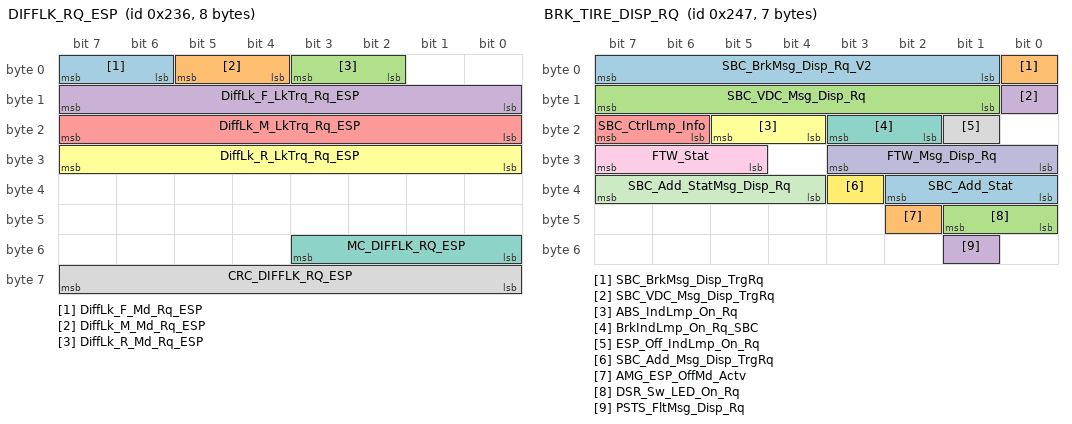
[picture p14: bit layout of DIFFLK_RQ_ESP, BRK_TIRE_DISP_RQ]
BO_ 566 DIFFLK_RQ_ESP: 8 ESP_ABR
 SG_ DiffLk_F_Md_Rq_ESP : 6|2@1+ (1,0) [0|3] "" Vector__XXX

CM_ SG_ 566 DiffLk_F_Md_Rq_ESP "DiffLk_F_Md_Rq_ESP [source enum/value-table reference]";
 SG_ DiffLk_M_Md_Rq_ESP : 4|2@1+ (1,0) [0|3] "" Vector__XXX

CM_ SG_ 566 DiffLk_M_Md_Rq_ESP "DiffLk_M_Md_Rq_ESP [source enum/value-table reference]";
 SG_ DiffLk_R_Md_Rq_ESP : 2|2@1+ (1,0) [0|3] "" Vector__XXX

CM_ SG_ 566 DiffLk_R_Md_Rq_ESP "DiffLk_R_Md_Rq_ESP [source enum/value-table reference]";
 SG_ DiffLk_F_LkTrq_Rq_ESP : 8|8@1+ (10,0) [0|2550] "Nm" Vector__XXX

CM_ SG_ 566 DiffLk_F_LkTrq_Rq_ESP "DiffLk_F_LkTrq_Rq_ESP";
 SG_ DiffLk_M_LkTrq_Rq_ESP : 16|8@1+ (10,0) [0|2550] "Nm" Vector__XXX

CM_ SG_ 566 DiffLk_M_LkTrq_Rq_ESP "DiffLk_M_LkTrq_Rq_ESP";
 SG_ DiffLk_R_LkTrq_Rq_ESP : 24|8@1+ (10,0) [0|2550] "Nm" Vector__XXX

CM_ SG_ 566 DiffLk_R_LkTrq_Rq_ESP "DiffLk_R_LkTrq_Rq_ESP";
 SG_ MC_DIFFLK_RQ_ESP : 48|4@1+ (1,0) [0|15] "" Vector__XXX

CM_ SG_ 566 MC_DIFFLK_RQ_ESP "MC_DIFFLK_RQ_ESP";
 SG_ CRC_DIFFLK_RQ_ESP : 56|8@1+ (1,0) [0|255] "" Vector__XXX

CM_ SG_ 566 CRC_DIFFLK_RQ_ESP "CRC_DIFFLK_RQ_ESP";

BA_ "GenMsgCycleTime" BO_ 566 8;

BO_ 581 VEH_DYN_STAT: 8 ESP_ABR
 SG_ VehYawRate_Raw : 0|16@1+ (0.00999999977648,-327.679992676) [-327.679992676|327.669992676] "deg/s" Vector__XXX

CM_ SG_ 581 VehYawRate_Raw "VehYawRate_Raw";
 SG_ VehYawRateOffset : 16|8@1+ (0.0799999982119,-10.2399997711) [-10.2399997711|10.1599997729] "deg/s" Vector__XXX

CM_ SG_ 581 VehYawRateOffset "VehYawRateOffset";
 SG_ VehAccel_X_Offset : 24|8@1+ (0.019999999553,-2.55999994278) [-2.55999994278|2.53999994323] "m/s2" Vector__XXX

CM_ SG_ 581 VehAccel_X_Offset "VehAccel_X_Offset";
 SG_ VehAccel_X : 32|8@1+ (0.0799999982119,-10.2399997711) [-10.2399997711|10.1599997729] "m/s2" Vector__XXX

CM_ SG_ 581 VehAccel_X "VehAccel_X";
 SG_ VehAccel_Y : 40|8@1+ (0.0799999982119,-10.2399997711) [-10.2399997711|10.1599997729] "m/s2" Vector__XXX

CM_ SG_ 581 VehAccel_Y "VehAccel_Y";
 SG_ MC_VEH_DYN_STAT : 48|4@1+ (1,0) [0|15] "" Vector__XXX

CM_ SG_ 581 MC_VEH_DYN_STAT "MC_VEH_DYN_STAT";
 SG_ VehAccel_Y_Offset : 56|8@1+ (0.019999999553,-2.55999994278) [-2.55999994278|2.53999994323] "m/s2" Vector__XXX

CM_ SG_ 581 VehAccel_Y_Offset "VehAccel_Y_Offset";

BA_ "GenMsgCycleTime" BO_ 581 7;

BO_ 583 BRK_TIRE_DISP_RQ: 7 ESP_ABR
 SG_ SBC_BrkMsg_Disp_Rq_V2 : 1|7@1+ (1,0) [0|127] "" Vector__XXX

CM_ SG_ 583 SBC_BrkMsg_Disp_Rq_V2 "SBC_BrkMsg_Disp_Rq_V2 [source enum/value-table reference]";
 SG_ SBC_BrkMsg_Disp_TrgRq : 0|1@1+ (1,0) [0|1] "" Vector__XXX

CM_ SG_ 583 SBC_BrkMsg_Disp_TrgRq "SBC_BrkMsg_Disp_TrgRq [source boolean]";
 SG_ SBC_VDC_Msg_Disp_Rq : 9|7@1+ (1,0) [0|127] "" Vector__XXX

CM_ SG_ 583 SBC_VDC_Msg_Disp_Rq "SBC_VDC_Msg_Disp_Rq [source enum/value-table reference]";
 SG_ SBC_VDC_Msg_Disp_TrgRq : 8|1@1+ (1,0) [0|1] "" Vector__XXX

CM_ SG_ 583 SBC_VDC_Msg_Disp_TrgRq "SBC_VDC_Msg_Disp_TrgRq [source boolean]";
 SG_ SBC_CtrlLmp_Info : 22|2@1+ (1,0) [0|3] "" Vector__XXX

CM_ SG_ 583 SBC_CtrlLmp_Info "SBC_CtrlLmp_Info [source enum/value-table reference]";
 SG_ ABS_IndLmp_On_Rq : 20|2@1+ (1,0) [0|3] "" Vector__XXX

CM_ SG_ 583 ABS_IndLmp_On_Rq "ABS_IndLmp_On_Rq [source enum/value-table reference]";
 SG_ BrkIndLmp_On_Rq_SBC : 18|2@1+ (1,0) [0|3] "" Vector__XXX

CM_ SG_ 583 BrkIndLmp_On_Rq_SBC "BrkIndLmp_On_Rq_SBC [source enum/value-table reference]";
 SG_ ESP_Off_IndLmp_On_Rq : 17|1@1+ (1,0) [0|1] "" Vector__XXX

CM_ SG_ 583 ESP_Off_IndLmp_On_Rq "ESP_Off_IndLmp_On_Rq [source boolean]";
 SG_ FTW_Stat : 29|3@1+ (1,0) [0|7] "" Vector__XXX

CM_ SG_ 583 FTW_Stat "FTW_Stat [source enum/value-table reference]";
 SG_ FTW_Msg_Disp_Rq : 24|4@1+ (1,0) [0|15] "" Vector__XXX

CM_ SG_ 583 FTW_Msg_Disp_Rq "FTW_Msg_Disp_Rq [source enum/value-table reference]";
 SG_ SBC_Add_StatMsg_Disp_Rq : 36|4@1+ (1,0) [0|15] "" Vector__XXX

CM_ SG_ 583 SBC_Add_StatMsg_Disp_Rq "SBC_Add_StatMsg_Disp_Rq [source enum/value-table reference]";
 SG_ SBC_Add_Msg_Disp_TrgRq : 35|1@1+ (1,0) [0|1] "" Vector__XXX

CM_ SG_ 583 SBC_Add_Msg_Disp_TrgRq "SBC_Add_Msg_Disp_TrgRq [source boolean]";
 SG_ SBC_Add_Stat : 32|3@1+ (1,0) [0|7] "" Vector__XXX

CM_ SG_ 583 SBC_Add_Stat "SBC_Add_Stat [source enum/value-table reference]";
 SG_ AMG_ESP_OffMd_Actv : 42|1@1+ (1,0) [0|1] "" Vector__XXX

CM_ SG_ 583 AMG_ESP_OffMd_Actv "AMG_ESP_OffMd_Actv [source boolean]";
 SG_ DSR_Sw_LED_On_Rq : 40|2@1+ (1,0) [0|3] "" Vector__XXX

CM_ SG_ 583 DSR_Sw_LED_On_Rq "DSR_Sw_LED_On_Rq [source enum/value-table reference]";
 SG_ PSTS_FltMsg_Disp_Rq : 49|1@1+ (1,0) [0|1] "" Vector__XXX

CM_ SG_ 583 PSTS_FltMsg_Disp_Rq "PSTS_FltMsg_Disp_Rq [source boolean]";

BA_ "GenMsgCycleTime" BO_ 583 16;

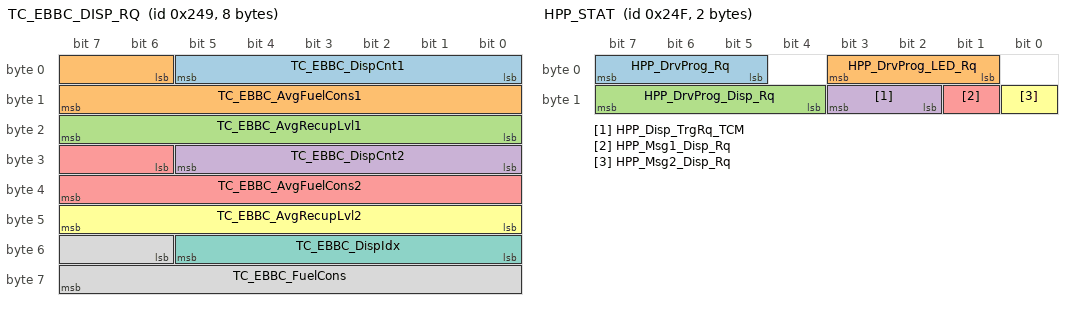
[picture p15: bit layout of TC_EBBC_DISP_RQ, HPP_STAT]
BO_ 585 TC_EBBC_DISP_RQ: 8 ESP_ABR
 SG_ TC_EBBC_DispCnt1 : 0|6@1+ (1,0) [0|63] "" Vector__XXX

CM_ SG_ 585 TC_EBBC_DispCnt1 "TC_EBBC_DispCnt1";
 SG_ TC_EBBC_AvgFuelCons1 : 6|10@1+ (0.10000000149,0) [0|102.300001524] "l/100km" Vector__XXX

CM_ SG_ 585 TC_EBBC_AvgFuelCons1 "TC_EBBC_AvgFuelCons1";
 SG_ TC_EBBC_AvgRecupLvl1 : 16|8@1+ (0.5,0) [0|127.5] "%" Vector__XXX

CM_ SG_ 585 TC_EBBC_AvgRecupLvl1 "TC_EBBC_AvgRecupLvl1";
 SG_ TC_EBBC_DispCnt2 : 24|6@1+ (1,0) [0|63] "" Vector__XXX

CM_ SG_ 585 TC_EBBC_DispCnt2 "TC_EBBC_DispCnt2";
 SG_ TC_EBBC_AvgFuelCons2 : 30|10@1+ (0.10000000149,0) [0|102.300001524] "l/100km" Vector__XXX

CM_ SG_ 585 TC_EBBC_AvgFuelCons2 "TC_EBBC_AvgFuelCons2";
 SG_ TC_EBBC_AvgRecupLvl2 : 40|8@1+ (0.5,0) [0|127.5] "%" Vector__XXX

CM_ SG_ 585 TC_EBBC_AvgRecupLvl2 "TC_EBBC_AvgRecupLvl2";
 SG_ TC_EBBC_DispIdx : 48|6@1+ (1,0) [0|63] "" Vector__XXX

CM_ SG_ 585 TC_EBBC_DispIdx "TC_EBBC_DispIdx";
 SG_ TC_EBBC_FuelCons : 54|10@1+ (0.10000000149,0) [0|102.300001524] "l/100km" Vector__XXX

CM_ SG_ 585 TC_EBBC_FuelCons "TC_EBBC_FuelCons";

BA_ "GenMsgCycleTime" BO_ 585 8;

BO_ 590 HPP_SW_STAT: 2 ESP_ABR
 SG_ HPP_Sw_Dir : 14|2@1+ (1,0) [0|3] "" Vector__XXX

CM_ SG_ 590 HPP_Sw_Dir "HPP_Sw_Dir [source enum/value-table reference]";
 SG_ HPP_Sw_Inc : 11|3@1+ (1,0) [0|7] "" Vector__XXX

CM_ SG_ 590 HPP_Sw_Inc "HPP_Sw_Inc";

BA_ "GenMsgCycleTime" BO_ 590 2;

BO_ 591 HPP_STAT: 2 ESP_ABR
 SG_ HPP_DrvProg_Rq : 5|3@1+ (1,0) [0|7] "" Vector__XXX

CM_ SG_ 591 HPP_DrvProg_Rq "HPP_DrvProg_Rq [source enum/value-table reference]";
 SG_ HPP_DrvProg_LED_Rq : 1|3@1+ (1,0) [0|7] "" Vector__XXX

CM_ SG_ 591 HPP_DrvProg_LED_Rq "HPP_DrvProg_LED_Rq [source enum/value-table reference]";
 SG_ HPP_DrvProg_Disp_Rq : 12|4@1+ (1,0) [0|15] "" Vector__XXX

CM_ SG_ 591 HPP_DrvProg_Disp_Rq "HPP_DrvProg_Disp_Rq [source enum/value-table reference]";
 SG_ HPP_Disp_TrgRq_TCM : 10|2@1+ (1,0) [0|3] "" Vector__XXX

CM_ SG_ 591 HPP_Disp_TrgRq_TCM "HPP_Disp_TrgRq_TCM [source enum/value-table reference]";
 SG_ HPP_Msg1_Disp_Rq : 9|1@1+ (1,0) [0|1] "" Vector__XXX

CM_ SG_ 591 HPP_Msg1_Disp_Rq "HPP_Msg1_Disp_Rq [source boolean]";
 SG_ HPP_Msg2_Disp_Rq : 8|1@1+ (1,0) [0|1] "" Vector__XXX

CM_ SG_ 591 HPP_Msg2_Disp_Rq "HPP_Msg2_Disp_Rq [source boolean]";

BA_ "GenMsgCycleTime" BO_ 591 6;

BO_ 643 BODY_R1: 8 ESP_ABR
 SG_ DrRLtch_FL_Stat : 6|2@1+ (1,0) [0|3] "" Vector__XXX

CM_ SG_ 643 DrRLtch_FL_Stat "DrRLtch_FL_Stat [source enum/value-table reference]";
 SG_ DrRLtch_FR_Stat : 4|2@1+ (1,0) [0|3] "" Vector__XXX

CM_ SG_ 643 DrRLtch_FR_Stat "DrRLtch_FR_Stat [source enum/value-table reference]";
 SG_ DrRLtch_RL_Stat : 2|2@1+ (1,0) [0|3] "" Vector__XXX

CM_ SG_ 643 DrRLtch_RL_Stat "DrRLtch_RL_Stat [source enum/value-table reference]";
 SG_ DrRLtch_RR_Stat : 0|2@1+ (1,0) [0|3] "" Vector__XXX

CM_ SG_ 643 DrRLtch_RR_Stat "DrRLtch_RR_Stat [source enum/value-table reference]";
 SG_ DL_RLtch_Stat : 14|2@1+ (1,0) [0|3] "" Vector__XXX

CM_ SG_ 643 DL_RLtch_Stat "DL_RLtch_Stat [source enum/value-table reference]";
 SG_ EngHd_Stat : 12|2@1+ (1,0) [0|3] "" Vector__XXX

CM_ SG_ 643 EngHd_Stat "EngHd_Stat [source enum/value-table reference]";
 SG_ VTA_Alm_Actv : 10|1@1+ (1,0) [0|1] "" Vector__XXX

CM_ SG_ 643 VTA_Alm_Actv "VTA_Alm_Actv [source boolean]";
 SG_ LgtSens_Twlgt : 21|3@1+ (1,0) [0|7] "Steps" Vector__XXX

CM_ SG_ 643 LgtSens_Twlgt "LgtSens_Twlgt";
 SG_ LgtSens_SNA : 20|1@1+ (1,0) [0|1] "" Vector__XXX

CM_ SG_ 643 LgtSens_SNA "LgtSens_SNA [source boolean]";
 SG_ LgtSens_Tunnel : 19|1@1+ (1,0) [0|1] "" Vector__XXX

CM_ SG_ 643 LgtSens_Tunnel "LgtSens_Tunnel [source boolean]";
 SG_ LgtSens_Flt : 18|1@1+ (1,0) [0|1] "" Vector__XXX

CM_ SG_ 643 LgtSens_Flt "LgtSens_Flt [source boolean]";
 SG_ LgtSens_Night : 17|1@1+ (1,0) [0|1] "" Vector__XXX

CM_ SG_ 643 LgtSens_Night "LgtSens_Night [source boolean]";
 SG_ ADL_LoBm_On_Rq : 16|1@1+ (1,0) [0|1] "" Vector__XXX

CM_ SG_ 643 ADL_LoBm_On_Rq "ADL_LoBm_On_Rq [source boolean]";
 SG_ Trlr_Stat : 30|2@1+ (1,0) [0|3] "" Vector__XXX

CM_ SG_ 643 Trlr_Stat "Trlr_Stat [source enum/value-table reference]";
 SG_ Hrn_On : 29|1@1+ (1,0) [0|1] "" Vector__XXX

CM_ SG_ 643 Hrn_On "Hrn_On [source boolean]";
 SG_ Term54_Actv : 28|1@1+ (1,0) [0|1] "" Vector__XXX

CM_ SG_ 643 Term54_Actv "Term54_Actv [source boolean]";
 SG_ MPkBrk_Stat : 27|1@1+ (1,0) [0|1] "" Vector__XXX

CM_ SG_ 643 MPkBrk_Stat "MPkBrk_Stat [source boolean]";
 SG_ WprOutsdPkPosn : 26|1@1+ (1,0) [0|1] "" Vector__XXX

CM_ SG_ 643 WprOutsdPkPosn "WprOutsdPkPosn [source boolean]";
 SG_ LoBm_On_Rq : 39|1@1+ (1,0) [0|1] "" Vector__XXX

CM_ SG_ 643 LoBm_On_Rq "LoBm_On_Rq [source boolean]";
 SG_ HiBm_On : 38|1@1+ (1,0) [0|1] "" Vector__XXX

CM_ SG_ 643 HiBm_On "HiBm_On [source boolean]";
 SG_ IrLmp_D_Lt_Flt : 37|1@1+ (1,0) [0|1] "" Vector__XXX

CM_ SG_ 643 IrLmp_D_Lt_Flt "IrLmp_D_Lt_Flt [source boolean]";
 SG_ IrLmp_P_Rt_Flt : 36|1@1+ (1,0) [0|1] "" Vector__XXX

CM_ SG_ 643 IrLmp_P_Rt_Flt "IrLmp_P_Rt_Flt [source boolean]";
 SG_ LoBm_D_Lt_Flt : 35|1@1+ (1,0) [0|1] "" Vector__XXX

CM_ SG_ 643 LoBm_D_Lt_Flt "LoBm_D_Lt_Flt [source boolean]";
 SG_ LoBm_P_Rt_Flt : 34|1@1+ (1,0) [0|1] "" Vector__XXX

CM_ SG_ 643 LoBm_P_Rt_Flt "LoBm_P_Rt_Flt [source boolean]";
 SG_ RevGr_Engg : 32|2@1+ (1,0) [0|3] "" Vector__XXX

CM_ SG_ 643 RevGr_Engg "RevGr_Engg [source enum/value-table reference]";
 SG_ AirTemp_Insd : 40|8@1+ (0.25,0) [0|63.75] "degC" Vector__XXX

CM_ SG_ 643 AirTemp_Insd "AirTemp_Insd";
 SG_ Bckl_Sw_RL_Stat_SAM_R : 54|2@1+ (1,0) [0|3] "" Vector__XXX

CM_ SG_ 643 Bckl_Sw_RL_Stat_SAM_R "Bckl_Sw_RL_Stat_SAM_R [source enum/value-table reference]";
 SG_ Bckl_Sw_RR_Stat_SAM_R : 52|2@1+ (1,0) [0|3] "" Vector__XXX

CM_ SG_ 643 Bckl_Sw_RR_Stat_SAM_R "Bckl_Sw_RR_Stat_SAM_R [source enum/value-table reference]";
 SG_ Bckl_Sw_RM_Stat_SAM_R : 50|2@1+ (1,0) [0|3] "" Vector__XXX

CM_ SG_ 643 Bckl_Sw_RM_Stat_SAM_R "Bckl_Sw_RM_Stat_SAM_R [source enum/value-table reference]";
 SG_ StW_Cond_Stat : 48|2@1+ (1,0) [0|3] "" Vector__XXX

CM_ SG_ 643 StW_Cond_Stat "StW_Cond_Stat [source enum/value-table reference]";
 SG_ AirTemp_Outsd : 56|8@1+ (1,0) [0|255] "degC" Vector__XXX

CM_ SG_ 643 AirTemp_Outsd "AirTemp_Outsd [source enum/value-table reference]";

BA_ "GenMsgCycleTime" BO_ 643 31;

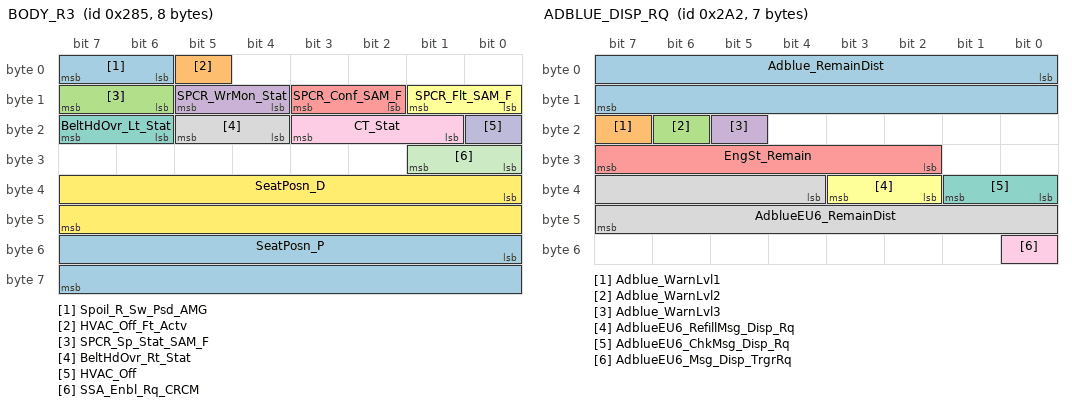
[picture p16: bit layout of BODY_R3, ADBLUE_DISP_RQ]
BO_ 645 BODY_R3: 8 ESP_ABR
 SG_ Spoil_R_Sw_Psd_AMG : 6|2@1+ (1,0) [0|3] "" Vector__XXX

CM_ SG_ 645 Spoil_R_Sw_Psd_AMG "Spoil_R_Sw_Psd_AMG [source enum/value-table reference]";
 SG_ HVAC_Off_Ft_Actv : 5|1@1+ (1,0) [0|1] "" Vector__XXX

CM_ SG_ 645 HVAC_Off_Ft_Actv "HVAC_Off_Ft_Actv [source boolean]";
 SG_ SPCR_Sp_Stat_SAM_F : 14|2@1+ (1,0) [0|3] "" Vector__XXX

CM_ SG_ 645 SPCR_Sp_Stat_SAM_F "SPCR_Sp_Stat_SAM_F [source enum/value-table reference]";
 SG_ SPCR_WrMon_Stat : 12|2@1+ (1,0) [0|3] "" Vector__XXX

CM_ SG_ 645 SPCR_WrMon_Stat "SPCR_WrMon_Stat [source enum/value-table reference]";
 SG_ SPCR_Conf_SAM_F : 10|2@1+ (1,0) [0|3] "" Vector__XXX

CM_ SG_ 645 SPCR_Conf_SAM_F "SPCR_Conf_SAM_F [source enum/value-table reference]";
 SG_ SPCR_Flt_SAM_F : 8|2@1+ (1,0) [0|3] "" Vector__XXX

CM_ SG_ 645 SPCR_Flt_SAM_F "SPCR_Flt_SAM_F [source enum/value-table reference]";
 SG_ BeltHdOvr_Lt_Stat : 22|2@1+ (1,0) [0|3] "" Vector__XXX

CM_ SG_ 645 BeltHdOvr_Lt_Stat "BeltHdOvr_Lt_Stat [source enum/value-table reference]";
 SG_ BeltHdOvr_Rt_Stat : 20|2@1+ (1,0) [0|3] "" Vector__XXX

CM_ SG_ 645 BeltHdOvr_Rt_Stat "BeltHdOvr_Rt_Stat [source enum/value-table reference]";
 SG_ CT_Stat : 17|3@1+ (1,0) [0|7] "" Vector__XXX

CM_ SG_ 645 CT_Stat "CT_Stat [source enum/value-table reference]";
 SG_ HVAC_Off : 16|1@1+ (1,0) [0|1] "" Vector__XXX

CM_ SG_ 645 HVAC_Off "HVAC_Off [source boolean]";
 SG_ SSA_Enbl_Rq_CRCM : 24|2@1+ (1,0) [0|3] "" Vector__XXX

CM_ SG_ 645 SSA_Enbl_Rq_CRCM "SSA_Enbl_Rq_CRCM [source enum/value-table reference]";
 SG_ SeatPosn_D : 32|16@1+ (1,0) [0|65535] "RotorRevolut" Vector__XXX

CM_ SG_ 645 SeatPosn_D "SeatPosn_D";
 SG_ SeatPosn_P : 48|16@1+ (1,0) [0|65535] "RotorRevolut" Vector__XXX

CM_ SG_ 645 SeatPosn_P "SeatPosn_P";

BA_ "GenMsgCycleTime" BO_ 645 13;

BO_ 655 EAC_A1: 8 ESP_ABR
 SG_ CompSpd : 0|8@1+ (50,0) [0|12750] "rpm" Vector__XXX

CM_ SG_ 655 CompSpd "CompSpd";
 SG_ Comp_Oprtn_Stat : 14|2@1+ (1,0) [0|3] "" Vector__XXX

CM_ SG_ 655 Comp_Oprtn_Stat "Comp_Oprtn_Stat [source enum/value-table reference]";
 SG_ EAC_TempLmt : 13|1@1+ (1,0) [0|1] "" Vector__XXX

CM_ SG_ 655 EAC_TempLmt "EAC_TempLmt [source boolean]";
 SG_ EAC_VoltLmt : 12|1@1+ (1,0) [0|1] "" Vector__XXX

CM_ SG_ 655 EAC_VoltLmt "EAC_VoltLmt [source boolean]";
 SG_ EAC_CurrLmt : 11|1@1+ (1,0) [0|1] "" Vector__XXX

CM_ SG_ 655 EAC_CurrLmt "EAC_CurrLmt [source boolean]";
 SG_ EAC_PressLmt : 10|1@1+ (1,0) [0|1] "" Vector__XXX

CM_ SG_ 655 EAC_PressLmt "EAC_PressLmt [source boolean]";
 SG_ EAC_EmgOprtn_PwrSpdLmt : 9|1@1+ (1,0) [0|1] "" Vector__XXX

CM_ SG_ 655 EAC_EmgOprtn_PwrSpdLmt "EAC_EmgOprtn_PwrSpdLmt [source boolean]";
 SG_ EAC_EmgOprtn_OnOffLmt : 8|1@1+ (1,0) [0|1] "" Vector__XXX

CM_ SG_ 655 EAC_EmgOprtn_OnOffLmt "EAC_EmgOprtn_OnOffLmt [source boolean]";
 SG_ EAC_Curr : 16|8@1+ (0.5,0) [0|127.5] "A" Vector__XXX

CM_ SG_ 655 EAC_Curr "EAC_Curr";
 SG_ EAC_Volt : 24|8@1+ (1,0) [0|255] "V" Vector__XXX

CM_ SG_ 655 EAC_Volt "EAC_Volt";
 SG_ EAC_Sp_Volt_Lo : 39|1@1+ (1,0) [0|1] "" Vector__XXX

CM_ SG_ 655 EAC_Sp_Volt_Lo "EAC_Sp_Volt_Lo [source boolean]";
 SG_ EAC_Sp_Volt_Hi : 38|1@1+ (1,0) [0|1] "" Vector__XXX

CM_ SG_ 655 EAC_Sp_Volt_Hi "EAC_Sp_Volt_Hi [source boolean]";
 SG_ EAC_Sp_Temp_Excess : 37|1@1+ (1,0) [0|1] "" Vector__XXX

CM_ SG_ 655 EAC_Sp_Temp_Excess "EAC_Sp_Temp_Excess [source boolean]";
 SG_ EAC_Sp_Trq_Excess : 36|1@1+ (1,0) [0|1] "" Vector__XXX

CM_ SG_ 655 EAC_Sp_Trq_Excess "EAC_Sp_Trq_Excess [source boolean]";
 SG_ EAC_Sp_CAN_Flt : 35|1@1+ (1,0) [0|1] "" Vector__XXX

CM_ SG_ 655 EAC_Sp_CAN_Flt "EAC_Sp_CAN_Flt [source boolean]";
 SG_ EAC_Sp_ExtPwrSup_Flt : 34|1@1+ (1,0) [0|1] "" Vector__XXX

CM_ SG_ 655 EAC_Sp_ExtPwrSup_Flt "EAC_Sp_ExtPwrSup_Flt [source boolean]";
 SG_ EAC_Sp_IntPwrSup_Flt : 33|1@1+ (1,0) [0|1] "" Vector__XXX

CM_ SG_ 655 EAC_Sp_IntPwrSup_Flt "EAC_Sp_IntPwrSup_Flt [source boolean]";
 SG_ EAC_Sp_Press_Flt : 32|1@1+ (1,0) [0|1] "" Vector__XXX

CM_ SG_ 655 EAC_Sp_Press_Flt "EAC_Sp_Press_Flt [source boolean]";
 SG_ EAC_Off_VoltSens_Flt : 47|1@1+ (1,0) [0|1] "" Vector__XXX

CM_ SG_ 655 EAC_Off_VoltSens_Flt "EAC_Off_VoltSens_Flt [source boolean]";
 SG_ EAC_Off_TempSens_Flt : 46|1@1+ (1,0) [0|1] "" Vector__XXX

CM_ SG_ 655 EAC_Off_TempSens_Flt "EAC_Off_TempSens_Flt [source boolean]";
 SG_ EAC_Off_CurrSens_Flt : 45|1@1+ (1,0) [0|1] "" Vector__XXX

CM_ SG_ 655 EAC_Off_CurrSens_Flt "EAC_Off_CurrSens_Flt [source boolean]";
 SG_ EAC_Off_ShrtCurr : 44|1@1+ (1,0) [0|1] "" Vector__XXX

CM_ SG_ 655 EAC_Off_ShrtCurr "EAC_Off_ShrtCurr [source boolean]";
 SG_ EAC_Off_Stall : 43|1@1+ (1,0) [0|1] "" Vector__XXX

CM_ SG_ 655 EAC_Off_Stall "EAC_Off_Stall [source boolean]";
 SG_ EAC_EmgOprtn_PwrLmt_Flt : 42|1@1+ (1,0) [0|1] "" Vector__XXX

CM_ SG_ 655 EAC_EmgOprtn_PwrLmt_Flt "EAC_EmgOprtn_PwrLmt_Flt [source boolean]";
 SG_ EAC_EmgOprtn_SpdLmt_Flt : 41|1@1+ (1,0) [0|1] "" Vector__XXX

CM_ SG_ 655 EAC_EmgOprtn_SpdLmt_Flt "EAC_EmgOprtn_SpdLmt_Flt [source boolean]";
 SG_ EAC_EmgOprtn_OnOffLmt_Flt : 40|1@1+ (1,0) [0|1] "" Vector__XXX

CM_ SG_ 655 EAC_EmgOprtn_OnOffLmt_Flt "EAC_EmgOprtn_OnOffLmt_Flt [source boolean]";
 SG_ EAC_ThermTemp_Max : 48|8@1+ (1,-50) [-50|205] "degC" Vector__XXX

CM_ SG_ 655 EAC_ThermTemp_Max "EAC_ThermTemp_Max";
 SG_ EAC_OutCurr : 56|8@1+ (0.5,0) [0|127.5] "A" Vector__XXX

CM_ SG_ 655 EAC_OutCurr "EAC_OutCurr";

BA_ "GenMsgCycleTime" BO_ 655 28;

BO_ 674 ADBLUE_DISP_RQ: 7 ESP_ABR
 SG_ Adblue_RemainDist : 0|16@1+ (1,-32767) [-32767|32768] "km" Vector__XXX

CM_ SG_ 674 Adblue_RemainDist "Adblue_RemainDist";
 SG_ Adblue_WarnLvl1 : 23|1@1+ (1,0) [0|1] "" Vector__XXX

CM_ SG_ 674 Adblue_WarnLvl1 "Adblue_WarnLvl1 [source boolean]";
 SG_ Adblue_WarnLvl2 : 22|1@1+ (1,0) [0|1] "" Vector__XXX

CM_ SG_ 674 Adblue_WarnLvl2 "Adblue_WarnLvl2 [source boolean]";
 SG_ Adblue_WarnLvl3 : 21|1@1+ (1,0) [0|1] "" Vector__XXX

CM_ SG_ 674 Adblue_WarnLvl3 "Adblue_WarnLvl3 [source boolean]";
 SG_ EngSt_Remain : 26|6@1+ (1,0) [0|63] "" Vector__XXX

CM_ SG_ 674 EngSt_Remain "EngSt_Remain";
 SG_ AdblueEU6_RefillMsg_Disp_Rq : 34|2@1+ (1,0) [0|3] "" Vector__XXX

CM_ SG_ 674 AdblueEU6_RefillMsg_Disp_Rq "AdblueEU6_RefillMsg_Disp_Rq [source enum/value-table reference]";
 SG_ AdblueEU6_ChkMsg_Disp_Rq : 32|2@1+ (1,0) [0|3] "" Vector__XXX

CM_ SG_ 674 AdblueEU6_ChkMsg_Disp_Rq "AdblueEU6_ChkMsg_Disp_Rq [source enum/value-table reference]";
 SG_ AdblueEU6_RemainDist : 36|12@1+ (1,0) [0|4095] "km" Vector__XXX

CM_ SG_ 674 AdblueEU6_RemainDist "AdblueEU6_RemainDist";
 SG_ AdblueEU6_Msg_Disp_TrgrRq : 48|1@1+ (1,0) [0|1] "" Vector__XXX

CM_ SG_ 674 AdblueEU6_Msg_Disp_TrgrRq "AdblueEU6_Msg_Disp_TrgrRq [source boolean]";

BA_ "GenMsgCycleTime" BO_ 674 9;

BO_ 725 PNHV_STAT: 8 ESP_ABR
 SG_ PNHV_SupBatCutSw_Stat : 6|2@1+ (1,0) [0|3] "" Vector__XXX

CM_ SG_ 725 PNHV_SupBatCutSw_Stat "PNHV_SupBatCutSw_Stat [source enum/value-table reference]";
 SG_ PNHV_PreChrgRst_Ovrht : 5|1@1+ (1,0) [0|1] "" Vector__XXX

CM_ SG_ 725 PNHV_PreChrgRst_Ovrht "PNHV_PreChrgRst_Ovrht [source boolean]";
 SG_ PNHV_SupBat_LkErr : 4|1@1+ (1,0) [0|1] "" Vector__XXX

CM_ SG_ 725 PNHV_SupBat_LkErr "PNHV_SupBat_LkErr [source boolean]";
 SG_ PNHV_SupBat_CoolVlv_Stat : 3|1@1+ (1,0) [0|1] "" Vector__XXX

CM_ SG_ 725 PNHV_SupBat_CoolVlv_Stat "PNHV_SupBat_CoolVlv_Stat [source boolean]";
 SG_ PNHV_SupBat_Cool_Rq : 2|1@1+ (1,0) [0|1] "" Vector__XXX

CM_ SG_ 725 PNHV_SupBat_Cool_Rq "PNHV_SupBat_Cool_Rq [source boolean]";
 SG_ PNHV_IntIso_Err : 1|1@1+ (1,0) [0|1] "" Vector__XXX

CM_ SG_ 725 PNHV_IntIso_Err "PNHV_IntIso_Err [source boolean]";
 SG_ PNHV_ExtIso_Err : 0|1@1+ (1,0) [0|1] "" Vector__XXX

CM_ SG_ 725 PNHV_ExtIso_Err "PNHV_ExtIso_Err [source boolean]";
 SG_ PNHV_SupBatCmpt_OutOfRng : 15|1@1+ (1,0) [0|1] "" Vector__XXX

CM_ SG_ 725 PNHV_SupBatCmpt_OutOfRng "PNHV_SupBatCmpt_OutOfRng [source boolean]";
 SG_ PNHV_SupBatCmptFlt : 14|1@1+ (1,0) [0|1] "" Vector__XXX

CM_ SG_ 725 PNHV_SupBatCmptFlt "PNHV_SupBatCmptFlt [source boolean]";
 SG_ PNHV_SupBat_ImmCool_Rq : 13|1@1+ (1,0) [0|1] "" Vector__XXX

CM_ SG_ 725 PNHV_SupBat_ImmCool_Rq "PNHV_SupBat_ImmCool_Rq [source boolean]";
 SG_ PNHV_SupBatSrv_Rq : 12|1@1+ (1,0) [0|1] "" Vector__XXX

CM_ SG_ 725 PNHV_SupBatSrv_Rq "PNHV_SupBatSrv_Rq [source boolean]";
 SG_ PNHV_SupBat_LHOM : 11|1@1+ (1,0) [0|1] "" Vector__XXX

CM_ SG_ 725 PNHV_SupBat_LHOM "PNHV_SupBat_LHOM [source boolean]";
 SG_ PNHV_SupBatNoCurr_Rq : 10|1@1+ (1,0) [0|1] "" Vector__XXX

CM_ SG_ 725 PNHV_SupBatNoCurr_Rq "PNHV_SupBatNoCurr_Rq [source boolean]";
 SG_ PNHV_SupBatCutFast_Opn_Rq : 9|1@1+ (1,0) [0|1] "" Vector__XXX

CM_ SG_ 725 PNHV_SupBatCutFast_Opn_Rq "PNHV_SupBatCutFast_Opn_Rq [source boolean]";
 SG_ PNHV_SupBatCutImm_Opn_Rq : 8|1@1+ (1,0) [0|1] "" Vector__XXX

CM_ SG_ 725 PNHV_SupBatCutImm_Opn_Rq "PNHV_SupBatCutImm_Opn_Rq [source boolean]";
 SG_ PNHV_SupBat_Temp : 16|8@1+ (1,-50) [-50|205] "degC" Vector__XXX

CM_ SG_ 725 PNHV_SupBat_Temp "PNHV_SupBat_Temp";
 SG_ PNHV_SupBat_CpctyLoss_Pred : 24|8@1+ (0.5,0) [0|127.5] "%" Vector__XXX

CM_ SG_ 725 PNHV_SupBat_CpctyLoss_Pred "PNHV_SupBat_CpctyLoss_Pred";
 SG_ PNHV_Iso_CriticErr : 37|1@1+ (1,0) [0|1] "" Vector__XXX

CM_ SG_ 725 PNHV_Iso_CriticErr "PNHV_Iso_CriticErr [source boolean]";
 SG_ PNHV_SupBat_SOC_Recal_Rq : 36|1@1+ (1,0) [0|1] "" Vector__XXX

CM_ SG_ 725 PNHV_SupBat_SOC_Recal_Rq "PNHV_SupBat_SOC_Recal_Rq [source boolean]";
 SG_ PNHV_SupBat_Volt_Src : 35|1@1+ (1,0) [0|1] "" Vector__XXX

CM_ SG_ 725 PNHV_SupBat_Volt_Src "PNHV_SupBat_Volt_Src [source boolean]";
 SG_ PNHV_SupBat_SOC : 38|10@1+ (0.10000000149,0) [0|102.300001524] "%" Vector__XXX

CM_ SG_ 725 PNHV_SupBat_SOC "PNHV_SupBat_SOC";
 SG_ PNHV_SupBat_CellVolt_Max : 48|8@1+ (0.00999999977648,2) [2|4.549999943] "V" Vector__XXX

CM_ SG_ 725 PNHV_SupBat_CellVolt_Max "PNHV_SupBat_CellVolt_Max";
 SG_ PNHV_SupBat_CellVolt_Min : 56|8@1+ (0.00999999977648,2) [2|4.549999943] "V" Vector__XXX

CM_ SG_ 725 PNHV_SupBat_CellVolt_Min "PNHV_SupBat_CellVolt_Min";

BA_ "GenMsgCycleTime" BO_ 725 23;

BO_ 743 EM2_DAC: 8 ESP_ABR
 SG_ EM2_DAC : 0|64@1+ (1,0) [0|9.22337203685e+18] "" Vector__XXX

CM_ SG_ 743 EM2_DAC "EM2_DAC [source string/raw data]";

BA_ "GenMsgCycleTime" BO_ 743 1;

BO_ 744 HYBRID_R1: 2 ESP_ABR
 SG_ PNHV_CoolPwr_Rq : 0|8@1+ (20,0) [0|5100] "W" Vector__XXX

CM_ SG_ 744 PNHV_CoolPwr_Rq "PNHV_CoolPwr_Rq";
 SG_ PNHV_CoolInletTemp : 8|8@1+ (0.5,-40) [-40|87.5] "degC" Vector__XXX

CM_ SG_ 744 PNHV_CoolInletTemp "PNHV_CoolInletTemp";

BA_ "GenMsgCycleTime" BO_ 744 2;

BO_ 747 DAC_TCM: 8 ESP_ABR
 SG_ DAC_TCM : 0|64@1+ (1,0) [0|9.22337203685e+18] "" Vector__XXX

CM_ SG_ 747 DAC_TCM "DAC_TCM [source string/raw data]";

BA_ "GenMsgCycleTime" BO_ 747 1;

BO_ 749 DAC_EM2: 8 ESP_ABR
 SG_ DAC_EM2 : 0|64@1+ (1,0) [0|9.22337203685e+18] "" Vector__XXX

CM_ SG_ 749 DAC_EM2 "DAC_EM2 [source string/raw data]";

BA_ "GenMsgCycleTime" BO_ 749 1;

BO_ 750 PTS_A1: 8 ESP_ABR
 SG_ PTS_TP_Flt : 7|1@1+ (1,0) [0|1] "" Vector__XXX

CM_ SG_ 750 PTS_TP_Flt "PTS_TP_Flt [source boolean]";
 SG_ APX_Beep_Rq : 6|1@1+ (1,0) [0|1] "" Vector__XXX

CM_ SG_ 750 APX_Beep_Rq "APX_Beep_Rq [source boolean]";
 SG_ APX_Menu_Enbl_Rq : 4|2@1+ (1,0) [0|3] "" Vector__XXX

CM_ SG_ 750 APX_Menu_Enbl_Rq "APX_Menu_Enbl_Rq [source enum/value-table reference]";
 SG_ PkGuid_Actv : 1|1@1+ (1,0) [0|1] "" Vector__XXX

CM_ SG_ 750 PkGuid_Actv "PkGuid_Actv [source boolean]";
 SG_ PTS_Off : 0|1@1+ (1,0) [0|1] "" Vector__XXX

CM_ SG_ 750 PTS_Off "PTS_Off [source boolean]";
 SG_ PTS_AcustWarn : 15|1@1+ (1,0) [0|1] "" Vector__XXX

CM_ SG_ 750 PTS_AcustWarn "PTS_AcustWarn [source boolean]";
 SG_ PTS_SwLED_Rq_PTS : 13|2@1+ (1,0) [0|3] "" Vector__XXX

CM_ SG_ 750 PTS_SwLED_Rq_PTS "PTS_SwLED_Rq_PTS [source enum/value-table reference]";
 SG_ Freq_Ft : 23|1@1+ (1,0) [0|1] "" Vector__XXX

CM_ SG_ 750 Freq_Ft "Freq_Ft [source boolean]";
 SG_ Vol_Ft : 21|2@1+ (1,0) [0|3] "" Vector__XXX

CM_ SG_ 750 Vol_Ft "Vol_Ft [source enum/value-table reference]";
 SG_ WarnElem_FL_Stat_V2 : 28|4@1+ (1,0) [0|15] "" Vector__XXX

CM_ SG_ 750 WarnElem_FL_Stat_V2 "WarnElem_FL_Stat_V2 [source enum/value-table reference]";
 SG_ WarnElem_FR_Stat_V2 : 24|4@1+ (1,0) [0|15] "" Vector__XXX

CM_ SG_ 750 WarnElem_FR_Stat_V2 "WarnElem_FR_Stat_V2 [source enum/value-table reference]";
 SG_ Snd_FL : 36|4@1+ (1,0) [0|15] "" Vector__XXX

CM_ SG_ 750 Snd_FL "Snd_FL [source enum/value-table reference]";
 SG_ Snd_FR : 32|4@1+ (1,0) [0|15] "" Vector__XXX

CM_ SG_ 750 Snd_FR "Snd_FR [source enum/value-table reference]";
 SG_ Freq_R : 47|1@1+ (1,0) [0|1] "" Vector__XXX

CM_ SG_ 750 Freq_R "Freq_R [source boolean]";
 SG_ Vol_R : 45|2@1+ (1,0) [0|3] "" Vector__XXX

CM_ SG_ 750 Vol_R "Vol_R [source enum/value-table reference]";
 SG_ WarnElem_RL_Stat_V2 : 52|4@1+ (1,0) [0|15] "" Vector__XXX

CM_ SG_ 750 WarnElem_RL_Stat_V2 "WarnElem_RL_Stat_V2 [source enum/value-table reference]";
 SG_ WarnElem_RR_Stat_V2 : 48|4@1+ (1,0) [0|15] "" Vector__XXX

CM_ SG_ 750 WarnElem_RR_Stat_V2 "WarnElem_RR_Stat_V2 [source enum/value-table reference]";
 SG_ Snd_RL : 60|4@1+ (1,0) [0|15] "" Vector__XXX

CM_ SG_ 750 Snd_RL "Snd_RL [source enum/value-table reference]";
 SG_ Snd_RR : 56|4@1+ (1,0) [0|15] "" Vector__XXX

CM_ SG_ 750 Snd_RR "Snd_RR [source enum/value-table reference]";

BA_ "GenMsgCycleTime" BO_ 750 19;

BO_ 752 TCM_DAC: 8 ESP_ABR
 SG_ TCM_DAC : 0|64@1+ (1,0) [0|9.22337203685e+18] "" Vector__XXX

CM_ SG_ 752 TCM_DAC "TCM_DAC [source string/raw data]";

BA_ "GenMsgCycleTime" BO_ 752 1;

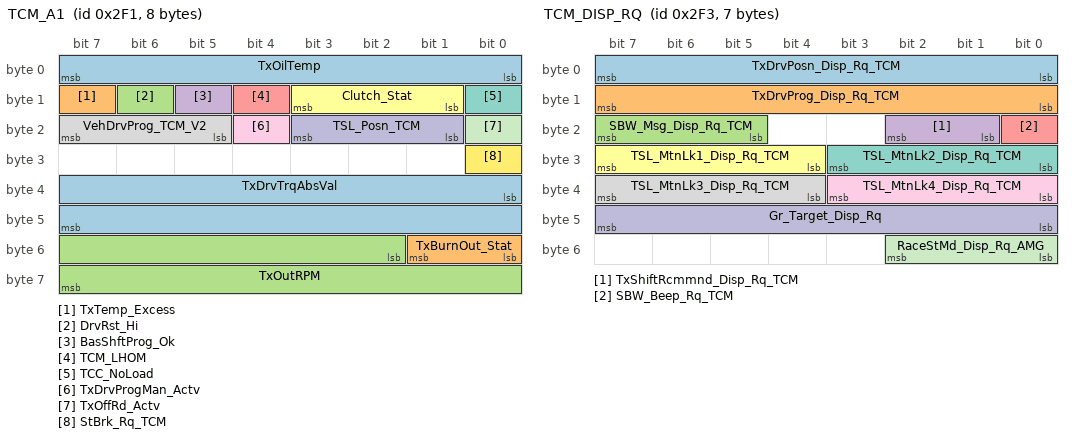
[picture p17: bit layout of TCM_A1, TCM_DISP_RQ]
BO_ 753 TCM_A1: 8 ESP_ABR
 SG_ TxOilTemp : 0|8@1+ (1,-50) [-50|205] "degC" Vector__XXX

CM_ SG_ 753 TxOilTemp "TxOilTemp";
 SG_ TxTemp_Excess : 15|1@1+ (1,0) [0|1] "" Vector__XXX

CM_ SG_ 753 TxTemp_Excess "TxTemp_Excess [source boolean]";
 SG_ DrvRst_Hi : 14|1@1+ (1,0) [0|1] "" Vector__XXX

CM_ SG_ 753 DrvRst_Hi "DrvRst_Hi [source boolean]";
 SG_ BasShftProg_Ok : 13|1@1+ (1,0) [0|1] "" Vector__XXX

CM_ SG_ 753 BasShftProg_Ok "BasShftProg_Ok [source boolean]";
 SG_ TCM_LHOM : 12|1@1+ (1,0) [0|1] "" Vector__XXX

CM_ SG_ 753 TCM_LHOM "TCM_LHOM [source boolean]";
 SG_ Clutch_Stat : 9|3@1+ (1,0) [0|7] "" Vector__XXX

CM_ SG_ 753 Clutch_Stat "Clutch_Stat [source enum/value-table reference]";
 SG_ TCC_NoLoad : 8|1@1+ (1,0) [0|1] "" Vector__XXX

CM_ SG_ 753 TCC_NoLoad "TCC_NoLoad [source boolean]";
 SG_ VehDrvProg_TCM_V2 : 21|3@1+ (1,0) [0|7] "" Vector__XXX

CM_ SG_ 753 VehDrvProg_TCM_V2 "VehDrvProg_TCM_V2 [source enum/value-table reference]";
 SG_ TxDrvProgMan_Actv : 20|1@1+ (1,0) [0|1] "" Vector__XXX

CM_ SG_ 753 TxDrvProgMan_Actv "TxDrvProgMan_Actv [source boolean]";
 SG_ TSL_Posn_TCM : 17|3@1+ (1,0) [0|7] "" Vector__XXX

CM_ SG_ 753 TSL_Posn_TCM "TSL_Posn_TCM [source enum/value-table reference]";
 SG_ TxOffRd_Actv : 16|1@1+ (1,0) [0|1] "" Vector__XXX

CM_ SG_ 753 TxOffRd_Actv "TxOffRd_Actv [source boolean]";
 SG_ StBrk_Rq_TCM : 24|1@1+ (1,0) [0|1] "" Vector__XXX

CM_ SG_ 753 StBrk_Rq_TCM "StBrk_Rq_TCM [source boolean]";
 SG_ TxDrvTrqAbsVal : 32|16@1+ (1,0) [0|65535] "Nm" Vector__XXX

CM_ SG_ 753 TxDrvTrqAbsVal "TxDrvTrqAbsVal";
 SG_ TxBurnOut_Stat : 48|2@1+ (1,0) [0|3] "" Vector__XXX

CM_ SG_ 753 TxBurnOut_Stat "TxBurnOut_Stat [source enum/value-table reference]";
 SG_ TxOutRPM : 50|14@1+ (1,0) [0|16383] "rpm" Vector__XXX

CM_ SG_ 753 TxOutRPM "TxOutRPM";

BA_ "GenMsgCycleTime" BO_ 753 15;

BO_ 755 TCM_DISP_RQ: 7 ESP_ABR
 SG_ TxDrvPosn_Disp_Rq_TCM : 0|8@1+ (1,0) [0|255] "" Vector__XXX

CM_ SG_ 755 TxDrvPosn_Disp_Rq_TCM "TxDrvPosn_Disp_Rq_TCM [source enum/value-table reference]";
 SG_ TxDrvProg_Disp_Rq_TCM : 8|8@1+ (1,0) [0|255] "" Vector__XXX

CM_ SG_ 755 TxDrvProg_Disp_Rq_TCM "TxDrvProg_Disp_Rq_TCM [source enum/value-table reference]";
 SG_ SBW_Msg_Disp_Rq_TCM : 21|3@1+ (1,0) [0|7] "" Vector__XXX

CM_ SG_ 755 SBW_Msg_Disp_Rq_TCM "SBW_Msg_Disp_Rq_TCM [source enum/value-table reference]";
 SG_ TxShiftRcmmnd_Disp_Rq_TCM : 17|2@1+ (1,0) [0|3] "" Vector__XXX

CM_ SG_ 755 TxShiftRcmmnd_Disp_Rq_TCM "TxShiftRcmmnd_Disp_Rq_TCM [source enum/value-table reference]";
 SG_ SBW_Beep_Rq_TCM : 16|1@1+ (1,0) [0|1] "" Vector__XXX

CM_ SG_ 755 SBW_Beep_Rq_TCM "SBW_Beep_Rq_TCM [source boolean]";
 SG_ TSL_MtnLk1_Disp_Rq_TCM : 28|4@1+ (1,0) [0|15] "" Vector__XXX

CM_ SG_ 755 TSL_MtnLk1_Disp_Rq_TCM "TSL_MtnLk1_Disp_Rq_TCM [source enum/value-table reference]";
 SG_ TSL_MtnLk2_Disp_Rq_TCM : 24|4@1+ (1,0) [0|15] "" Vector__XXX

CM_ SG_ 755 TSL_MtnLk2_Disp_Rq_TCM "TSL_MtnLk2_Disp_Rq_TCM [source enum/value-table reference]";
 SG_ TSL_MtnLk3_Disp_Rq_TCM : 36|4@1+ (1,0) [0|15] "" Vector__XXX

CM_ SG_ 755 TSL_MtnLk3_Disp_Rq_TCM "TSL_MtnLk3_Disp_Rq_TCM [source enum/value-table reference]";
 SG_ TSL_MtnLk4_Disp_Rq_TCM : 32|4@1+ (1,0) [0|15] "" Vector__XXX

CM_ SG_ 755 TSL_MtnLk4_Disp_Rq_TCM "TSL_MtnLk4_Disp_Rq_TCM [source enum/value-table reference]";
 SG_ Gr_Target_Disp_Rq : 40|8@1+ (1,0) [0|255] "" Vector__XXX

CM_ SG_ 755 Gr_Target_Disp_Rq "Gr_Target_Disp_Rq [source enum/value-table reference]";
 SG_ RaceStMd_Disp_Rq_AMG : 48|3@1+ (1,0) [0|7] "" Vector__XXX

CM_ SG_ 755 RaceStMd_Disp_Rq_AMG "RaceStMd_Disp_Rq_AMG [source enum/value-table reference]";

BA_ "GenMsgCycleTime" BO_ 755 11;

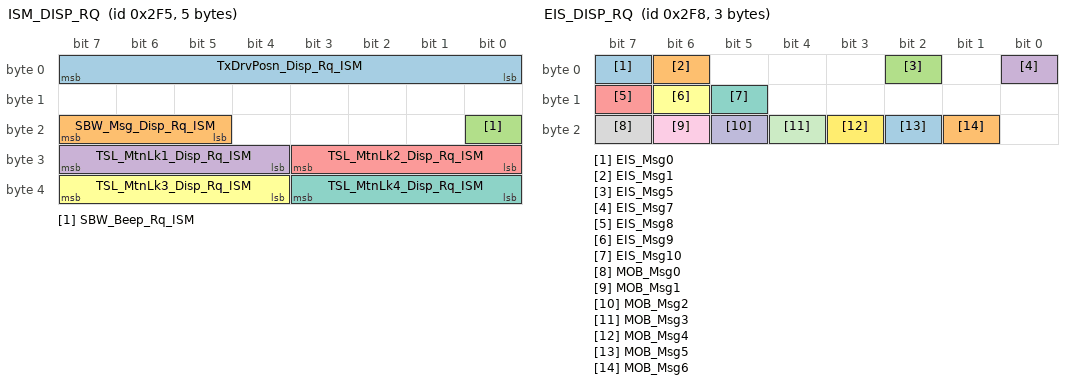
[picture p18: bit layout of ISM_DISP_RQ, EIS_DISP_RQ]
BO_ 757 ISM_DISP_RQ: 5 ESP_ABR
 SG_ TxDrvPosn_Disp_Rq_ISM : 0|8@1+ (1,0) [0|255] "" Vector__XXX

CM_ SG_ 757 TxDrvPosn_Disp_Rq_ISM "TxDrvPosn_Disp_Rq_ISM [source enum/value-table reference]";
 SG_ SBW_Msg_Disp_Rq_ISM : 21|3@1+ (1,0) [0|7] "" Vector__XXX

CM_ SG_ 757 SBW_Msg_Disp_Rq_ISM "SBW_Msg_Disp_Rq_ISM [source enum/value-table reference]";
 SG_ SBW_Beep_Rq_ISM : 16|1@1+ (1,0) [0|1] "" Vector__XXX

CM_ SG_ 757 SBW_Beep_Rq_ISM "SBW_Beep_Rq_ISM [source boolean]";
 SG_ TSL_MtnLk1_Disp_Rq_ISM : 28|4@1+ (1,0) [0|15] "" Vector__XXX

CM_ SG_ 757 TSL_MtnLk1_Disp_Rq_ISM "TSL_MtnLk1_Disp_Rq_ISM [source enum/value-table reference]";
 SG_ TSL_MtnLk2_Disp_Rq_ISM : 24|4@1+ (1,0) [0|15] "" Vector__XXX

CM_ SG_ 757 TSL_MtnLk2_Disp_Rq_ISM "TSL_MtnLk2_Disp_Rq_ISM [source enum/value-table reference]";
 SG_ TSL_MtnLk3_Disp_Rq_ISM : 36|4@1+ (1,0) [0|15] "" Vector__XXX

CM_ SG_ 757 TSL_MtnLk3_Disp_Rq_ISM "TSL_MtnLk3_Disp_Rq_ISM [source enum/value-table reference]";
 SG_ TSL_MtnLk4_Disp_Rq_ISM : 32|4@1+ (1,0) [0|15] "" Vector__XXX

CM_ SG_ 757 TSL_MtnLk4_Disp_Rq_ISM "TSL_MtnLk4_Disp_Rq_ISM [source enum/value-table reference]";

BA_ "GenMsgCycleTime" BO_ 757 7;

BO_ 758 ISM_DAC: 8 ESP_ABR
 SG_ ISM_DAC : 0|64@1+ (1,0) [0|9.22337203685e+18] "" Vector__XXX

CM_ SG_ 758 ISM_DAC "ISM_DAC [source string/raw data]";

BA_ "GenMsgCycleTime" BO_ 758 1;

BO_ 759 SG_A1_ECM: 6 ESP_ABR
 SG_ SG_OutDC_Curr_ECM : 0|16@1+ (0.10000000149,-3276.60009766) [-3276.60009766|3276.9] "A" Vector__XXX

CM_ SG_ 759 SG_OutDC_Curr_ECM "SG_OutDC_Curr_ECM";
 SG_ SG_OutDC_Volt_ECM : 16|16@1+ (0.10000000149,0) [0|6553.50009765] "V" Vector__XXX

CM_ SG_ 759 SG_OutDC_Volt_ECM "SG_OutDC_Volt_ECM";
 SG_ PN14_GenExctCurr : 32|8@1+ (0.0500000007451,0) [0|12.75000019] "A" Vector__XXX

CM_ SG_ 759 PN14_GenExctCurr "PN14_GenExctCurr";
 SG_ PN14_GenSupplr : 45|3@1+ (1,0) [0|7] "" Vector__XXX

CM_ SG_ 759 PN14_GenSupplr "PN14_GenSupplr [source enum/value-table reference]";
 SG_ PN14_GenStyle : 41|4@1+ (1,0) [0|15] "" Vector__XXX

CM_ SG_ 759 PN14_GenStyle "PN14_GenStyle [source enum/value-table reference]";

BA_ "GenMsgCycleTime" BO_ 759 5;

BO_ 760 EIS_DISP_RQ: 3 ESP_ABR
 SG_ EIS_Msg0 : 7|1@1+ (1,0) [0|1] "" Vector__XXX

CM_ SG_ 760 EIS_Msg0 "EIS_Msg0 [source boolean]";
 SG_ EIS_Msg1 : 6|1@1+ (1,0) [0|1] "" Vector__XXX

CM_ SG_ 760 EIS_Msg1 "EIS_Msg1 [source boolean]";
 SG_ EIS_Msg5 : 2|1@1+ (1,0) [0|1] "" Vector__XXX

CM_ SG_ 760 EIS_Msg5 "EIS_Msg5 [source boolean]";
 SG_ EIS_Msg7 : 0|1@1+ (1,0) [0|1] "" Vector__XXX

CM_ SG_ 760 EIS_Msg7 "EIS_Msg7 [source boolean]";
 SG_ EIS_Msg8 : 15|1@1+ (1,0) [0|1] "" Vector__XXX

CM_ SG_ 760 EIS_Msg8 "EIS_Msg8 [source boolean]";
 SG_ EIS_Msg9 : 14|1@1+ (1,0) [0|1] "" Vector__XXX

CM_ SG_ 760 EIS_Msg9 "EIS_Msg9 [source boolean]";
 SG_ EIS_Msg10 : 13|1@1+ (1,0) [0|1] "" Vector__XXX

CM_ SG_ 760 EIS_Msg10 "EIS_Msg10 [source boolean]";
 SG_ MOB_Msg0 : 23|1@1+ (1,0) [0|1] "" Vector__XXX

CM_ SG_ 760 MOB_Msg0 "MOB_Msg0 [source boolean]";
 SG_ MOB_Msg1 : 22|1@1+ (1,0) [0|1] "" Vector__XXX

CM_ SG_ 760 MOB_Msg1 "MOB_Msg1 [source boolean]";
 SG_ MOB_Msg2 : 21|1@1+ (1,0) [0|1] "" Vector__XXX

CM_ SG_ 760 MOB_Msg2 "MOB_Msg2 [source boolean]";
 SG_ MOB_Msg3 : 20|1@1+ (1,0) [0|1] "" Vector__XXX

CM_ SG_ 760 MOB_Msg3 "MOB_Msg3 [source boolean]";
 SG_ MOB_Msg4 : 19|1@1+ (1,0) [0|1] "" Vector__XXX

CM_ SG_ 760 MOB_Msg4 "MOB_Msg4 [source boolean]";
 SG_ MOB_Msg5 : 18|1@1+ (1,0) [0|1] "" Vector__XXX

CM_ SG_ 760 MOB_Msg5 "MOB_Msg5 [source boolean]";
 SG_ MOB_Msg6 : 17|1@1+ (1,0) [0|1] "" Vector__XXX

CM_ SG_ 760 MOB_Msg6 "MOB_Msg6 [source boolean]";

BA_ "GenMsgCycleTime" BO_ 760 14;

BO_ 766 DAC_ISM: 8 ESP_ABR
 SG_ DAC_ISM : 0|64@1+ (1,0) [0|9.22337203685e+18] "" Vector__XXX

CM_ SG_ 766 DAC_ISM "DAC_ISM [source string/raw data]";

BA_ "GenMsgCycleTime" BO_ 766 1;

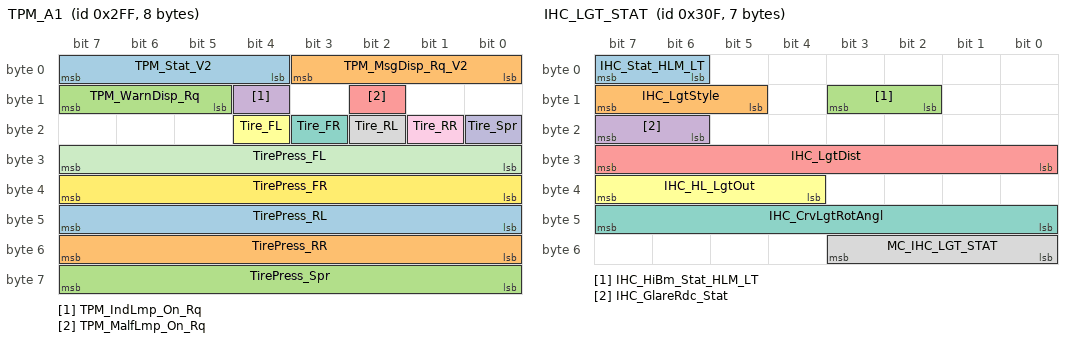
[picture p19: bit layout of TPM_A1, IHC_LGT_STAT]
BO_ 767 TPM_A1: 8 ESP_ABR
 SG_ TPM_Stat_V2 : 4|4@1+ (1,0) [0|15] "" Vector__XXX

CM_ SG_ 767 TPM_Stat_V2 "TPM_Stat_V2 [source enum/value-table reference]";
 SG_ TPM_MsgDisp_Rq_V2 : 0|4@1+ (1,0) [0|15] "" Vector__XXX

CM_ SG_ 767 TPM_MsgDisp_Rq_V2 "TPM_MsgDisp_Rq_V2 [source enum/value-table reference]";
 SG_ TPM_WarnDisp_Rq : 13|3@1+ (1,0) [0|7] "" Vector__XXX

CM_ SG_ 767 TPM_WarnDisp_Rq "TPM_WarnDisp_Rq [source enum/value-table reference]";
 SG_ TPM_IndLmp_On_Rq : 12|1@1+ (1,0) [0|1] "" Vector__XXX

CM_ SG_ 767 TPM_IndLmp_On_Rq "TPM_IndLmp_On_Rq [source boolean]";
 SG_ TPM_MalfLmp_On_Rq : 10|1@1+ (1,0) [0|1] "" Vector__XXX

CM_ SG_ 767 TPM_MalfLmp_On_Rq "TPM_MalfLmp_On_Rq [source boolean]";
 SG_ Tire_FL : 20|1@1+ (1,0) [0|1] "" Vector__XXX

CM_ SG_ 767 Tire_FL "Tire_FL [source boolean]";
 SG_ Tire_FR : 19|1@1+ (1,0) [0|1] "" Vector__XXX

CM_ SG_ 767 Tire_FR "Tire_FR [source boolean]";
 SG_ Tire_RL : 18|1@1+ (1,0) [0|1] "" Vector__XXX

CM_ SG_ 767 Tire_RL "Tire_RL [source boolean]";
 SG_ Tire_RR : 17|1@1+ (1,0) [0|1] "" Vector__XXX

CM_ SG_ 767 Tire_RR "Tire_RR [source boolean]";
 SG_ Tire_Spr : 16|1@1+ (1,0) [0|1] "" Vector__XXX

CM_ SG_ 767 Tire_Spr "Tire_Spr [source boolean]";
 SG_ TirePress_FL : 24|8@1+ (1,0) [0|255] "bar" Vector__XXX

CM_ SG_ 767 TirePress_FL "TirePress_FL [source enum/value-table reference]";
 SG_ TirePress_FR : 32|8@1+ (1,0) [0|255] "bar" Vector__XXX

CM_ SG_ 767 TirePress_FR "TirePress_FR [source enum/value-table reference]";
 SG_ TirePress_RL : 40|8@1+ (1,0) [0|255] "bar" Vector__XXX

CM_ SG_ 767 TirePress_RL "TirePress_RL [source enum/value-table reference]";
 SG_ TirePress_RR : 48|8@1+ (1,0) [0|255] "bar" Vector__XXX

CM_ SG_ 767 TirePress_RR "TirePress_RR [source enum/value-table reference]";
 SG_ TirePress_Spr : 56|8@1+ (1,0) [0|255] "bar" Vector__XXX

CM_ SG_ 767 TirePress_Spr "TirePress_Spr [source enum/value-table reference]";

BA_ "GenMsgCycleTime" BO_ 767 15;

BO_ 770 DAC_ECM: 8 ESP_ABR
 SG_ DAC_ECM : 0|64@1+ (1,0) [0|9.22337203685e+18] "" Vector__XXX

CM_ SG_ 770 DAC_ECM "DAC_ECM [source string/raw data]";

BA_ "GenMsgCycleTime" BO_ 770 1;

BO_ 773 OCM_A1: 4 ESP_ABR
 SG_ OC_P_OCM : 5|3@1+ (1,0) [0|7] "" Vector__XXX

CM_ SG_ 773 OC_P_OCM "OC_P_OCM [source enum/value-table reference]";
 SG_ OC_P_Flt_OCM : 4|1@1+ (1,0) [0|1] "" Vector__XXX

CM_ SG_ 773 OC_P_Flt_OCM "OC_P_Flt_OCM [source boolean]";
 SG_ OC_P_Fast_OCM : 2|2@1+ (1,0) [0|3] "" Vector__XXX

CM_ SG_ 773 OC_P_Fast_OCM "OC_P_Fast_OCM [source enum/value-table reference]";
 SG_ OCM_Id : 16|8@1+ (1,0) [0|255] "" Vector__XXX

CM_ SG_ 773 OCM_Id "OCM_Id [source enum/value-table reference]";
 SG_ OCM_MsgDisp_Rq : 30|2@1+ (1,0) [0|3] "" Vector__XXX

CM_ SG_ 773 OCM_MsgDisp_Rq "OCM_MsgDisp_Rq [source enum/value-table reference]";

BA_ "GenMsgCycleTime" BO_ 773 5;

BO_ 774 EAC_RQ: 6 ESP_ABR
 SG_ CompSpd_Target : 0|8@1+ (50,0) [0|12750] "rpm" Vector__XXX

CM_ SG_ 774 CompSpd_Target "CompSpd_Target";
 SG_ Comp_On_Rq : 14|2@1+ (1,0) [0|3] "" Vector__XXX

CM_ SG_ 774 Comp_On_Rq "Comp_On_Rq [source enum/value-table reference]";
 SG_ HVAC_MaxCool_Rq : 8|1@1+ (1,0) [0|1] "" Vector__XXX

CM_ SG_ 774 HVAC_MaxCool_Rq "HVAC_MaxCool_Rq [source boolean]";
 SG_ R134a_Press_Stat : 32|16@1+ (0.10000000149,0) [0|6553.50009765] "bar" Vector__XXX

CM_ SG_ 774 R134a_Press_Stat "R134a_Press_Stat";

BA_ "GenMsgCycleTime" BO_ 774 4;

BO_ 778 TP_TELEAID_IC5: 8 ESP_ABR
 SG_ TP_TELEAID_IC : 0|64@1+ (1,0) [0|9.22337203685e+18] "" Vector__XXX

CM_ SG_ 778 TP_TELEAID_IC "TP_TELEAID_IC [source string/raw data]";

BA_ "GenMsgCycleTime" BO_ 778 1;

BO_ 781 ECM_A1: 8 ESP_ABR
 SG_ EngCoolTemp : 0|8@1+ (1,-40) [-40|215] "degC" Vector__XXX

CM_ SG_ 781 EngCoolTemp "EngCoolTemp";
 SG_ IntkAirTemp : 8|8@1+ (1,-40) [-40|215] "degC" Vector__XXX

CM_ SG_ 781 IntkAirTemp "IntkAirTemp";
 SG_ EngOilTemp : 16|8@1+ (1,-40) [-40|215] "degC" Vector__XXX

CM_ SG_ 781 EngOilTemp "EngOilTemp";
 SG_ EngOilLvl : 24|8@1+ (0.314960628748,0) [0|80.3149603307] "mm" Vector__XXX

CM_ SG_ 781 EngOilLvl "EngOilLvl";
 SG_ EngOilQual : 32|8@1+ (0.0196850392967,1) [1|6.01968502067] "" Vector__XXX

CM_ SG_ 781 EngOilQual "EngOilQual";
 SG_ FuelCons : 40|16@1+ (0.216681420803,0) [0|14200.2169123] "l/250ms" Vector__XXX

CM_ SG_ 781 FuelCons "FuelCons";
 SG_ AirPress_Outsd : 56|8@1+ (7.79527568817,0) [0|1987.79530048] "hPa" Vector__XXX

CM_ SG_ 781 AirPress_Outsd "AirPress_Outsd";

BA_ "GenMsgCycleTime" BO_ 781 7;

BO_ 782 SAM_F_DISP_RQ2: 6 ESP_ABR
 SG_ CoolIndLmp_On_Rq : 3|1@1+ (1,0) [0|1] "" Vector__XXX

CM_ SG_ 782 CoolIndLmp_On_Rq "CoolIndLmp_On_Rq [source boolean]";
 SG_ WashWtrIndLmp_On_Rq : 2|1@1+ (1,0) [0|1] "" Vector__XXX

CM_ SG_ 782 WashWtrIndLmp_On_Rq "WashWtrIndLmp_On_Rq [source boolean]";
 SG_ BrkFldIndLmp_On_Rq : 1|1@1+ (1,0) [0|1] "" Vector__XXX

CM_ SG_ 782 BrkFldIndLmp_On_Rq "BrkFldIndLmp_On_Rq [source boolean]";
 SG_ BrkLnWearIndLmp_On_Rq : 0|1@1+ (1,0) [0|1] "" Vector__XXX

CM_ SG_ 782 BrkLnWearIndLmp_On_Rq "BrkLnWearIndLmp_On_Rq [source boolean]";
 SG_ IrLmp_Lt_Flt : 15|1@1+ (1,0) [0|1] "" Vector__XXX

CM_ SG_ 782 IrLmp_Lt_Flt "IrLmp_Lt_Flt [source boolean]";
 SG_ SM_FL_Flt : 14|1@1+ (1,0) [0|1] "" Vector__XXX

CM_ SG_ 782 SM_FL_Flt "SM_FL_Flt [source boolean]";
 SG_ TurnLmp_FL_Flt : 13|1@1+ (1,0) [0|1] "" Vector__XXX

CM_ SG_ 782 TurnLmp_FL_Flt "TurnLmp_FL_Flt [source boolean]";
 SG_ PkLmp_FL_Flt : 12|1@1+ (1,0) [0|1] "" Vector__XXX

CM_ SG_ 782 PkLmp_FL_Flt "PkLmp_FL_Flt [source boolean]";
 SG_ LoBm_Lt_Flt : 11|1@1+ (1,0) [0|1] "" Vector__XXX

CM_ SG_ 782 LoBm_Lt_Flt "LoBm_Lt_Flt [source boolean]";
 SG_ HiBm_Lt_Flt : 10|1@1+ (1,0) [0|1] "" Vector__XXX

CM_ SG_ 782 HiBm_Lt_Flt "HiBm_Lt_Flt [source boolean]";
 SG_ FogLmp_FL_Flt : 9|1@1+ (1,0) [0|1] "" Vector__XXX

CM_ SG_ 782 FogLmp_FL_Flt "FogLmp_FL_Flt [source boolean]";
 SG_ DRL_Lt_Flt : 8|1@1+ (1,0) [0|1] "" Vector__XXX

CM_ SG_ 782 DRL_Lt_Flt "DRL_Lt_Flt [source boolean]";
 SG_ TurnLmp_R_Flt : 23|1@1+ (1,0) [0|1] "" Vector__XXX

CM_ SG_ 782 TurnLmp_R_Flt "TurnLmp_R_Flt [source boolean]";
 SG_ TurnLmp_R_Flt_TM : 22|1@1+ (1,0) [0|1] "" Vector__XXX

CM_ SG_ 782 TurnLmp_R_Flt_TM "TurnLmp_R_Flt_TM [source boolean]";
 SG_ EmgLgtPath_Flt_SAM_F : 21|1@1+ (1,0) [0|1] "" Vector__XXX

CM_ SG_ 782 EmgLgtPath_Flt_SAM_F "EmgLgtPath_Flt_SAM_F [source boolean]";
 SG_ SL_LoBm_Actv : 18|2@1+ (1,0) [0|3] "" Vector__XXX

CM_ SG_ 782 SL_LoBm_Actv "SL_LoBm_Actv [source enum/value-table reference]";
 SG_ SL_PkLmp_FL_Actv : 17|1@1+ (1,0) [0|1] "" Vector__XXX

CM_ SG_ 782 SL_PkLmp_FL_Actv "SL_PkLmp_FL_Actv [source boolean]";
 SG_ SL_TurnLmp_FL_Actv : 16|1@1+ (1,0) [0|1] "" Vector__XXX

CM_ SG_ 782 SL_TurnLmp_FL_Actv "SL_TurnLmp_FL_Actv [source boolean]";
 SG_ IrLmp_Rt_Flt : 31|1@1+ (1,0) [0|1] "" Vector__XXX

CM_ SG_ 782 IrLmp_Rt_Flt "IrLmp_Rt_Flt [source boolean]";
 SG_ SM_FR_Flt : 30|1@1+ (1,0) [0|1] "" Vector__XXX

CM_ SG_ 782 SM_FR_Flt "SM_FR_Flt [source boolean]";
 SG_ TurnLmp_FR_Flt : 29|1@1+ (1,0) [0|1] "" Vector__XXX

CM_ SG_ 782 TurnLmp_FR_Flt "TurnLmp_FR_Flt [source boolean]";
 SG_ PkLmp_FR_Flt : 28|1@1+ (1,0) [0|1] "" Vector__XXX

CM_ SG_ 782 PkLmp_FR_Flt "PkLmp_FR_Flt [source boolean]";
 SG_ LoBm_Rt_Flt : 27|1@1+ (1,0) [0|1] "" Vector__XXX

CM_ SG_ 782 LoBm_Rt_Flt "LoBm_Rt_Flt [source boolean]";
 SG_ HiBm_Rt_Flt : 26|1@1+ (1,0) [0|1] "" Vector__XXX

CM_ SG_ 782 HiBm_Rt_Flt "HiBm_Rt_Flt [source boolean]";
 SG_ FogLmp_FR_Flt : 25|1@1+ (1,0) [0|1] "" Vector__XXX

CM_ SG_ 782 FogLmp_FR_Flt "FogLmp_FR_Flt [source boolean]";
 SG_ DRL_Rt_Flt : 24|1@1+ (1,0) [0|1] "" Vector__XXX

CM_ SG_ 782 DRL_Rt_Flt "DRL_Rt_Flt [source boolean]";
 SG_ IHC_Actv : 39|1@1+ (1,0) [0|1] "" Vector__XXX

CM_ SG_ 782 IHC_Actv "IHC_Actv [source boolean]";
 SG_ IHC_Menu_Rq : 38|1@1+ (1,0) [0|1] "" Vector__XXX

CM_ SG_ 782 IHC_Menu_Rq "IHC_Menu_Rq [source boolean]";
 SG_ IHC_FltDisp_Rq : 35|3@1+ (1,0) [0|7] "" Vector__XXX

CM_ SG_ 782 IHC_FltDisp_Rq "IHC_FltDisp_Rq [source enum/value-table reference]";
 SG_ SL_PkLmp_FR_Actv : 33|1@1+ (1,0) [0|1] "" Vector__XXX

CM_ SG_ 782 SL_PkLmp_FR_Actv "SL_PkLmp_FR_Actv [source boolean]";
 SG_ SL_TurnLmp_FR_Actv : 32|1@1+ (1,0) [0|1] "" Vector__XXX

CM_ SG_ 782 SL_TurnLmp_FR_Actv "SL_TurnLmp_FR_Actv [source boolean]";
 SG_ EngHd_Stat_SAM_F : 46|2@1+ (1,0) [0|3] "" Vector__XXX

CM_ SG_ 782 EngHd_Stat_SAM_F "EngHd_Stat_SAM_F [source enum/value-table reference]";
 SG_ EngHd_Flt_Stat_SAM_F : 44|2@1+ (1,0) [0|3] "" Vector__XXX

CM_ SG_ 782 EngHd_Flt_Stat_SAM_F "EngHd_Flt_Stat_SAM_F [source enum/value-table reference]";

BA_ "GenMsgCycleTime" BO_ 782 33;

BO_ 783 IHC_LGT_STAT: 7 ESP_ABR
 SG_ IHC_Stat_HLM_LT : 6|2@1+ (1,0) [0|3] "" Vector__XXX

CM_ SG_ 783 IHC_Stat_HLM_LT "IHC_Stat_HLM_LT [source enum/value-table reference]";
 SG_ IHC_LgtStyle : 13|3@1+ (1,0) [0|7] "" Vector__XXX

CM_ SG_ 783 IHC_LgtStyle "IHC_LgtStyle [source enum/value-table reference]";
 SG_ IHC_HiBm_Stat_HLM_LT : 10|2@1+ (1,0) [0|3] "" Vector__XXX

CM_ SG_ 783 IHC_HiBm_Stat_HLM_LT "IHC_HiBm_Stat_HLM_LT [source enum/value-table reference]";
 SG_ IHC_GlareRdc_Stat : 22|2@1+ (1,0) [0|3] "" Vector__XXX

CM_ SG_ 783 IHC_GlareRdc_Stat "IHC_GlareRdc_Stat [source enum/value-table reference]";
 SG_ IHC_LgtDist : 24|8@1+ (2.5,0) [0|637.5] "m" Vector__XXX

CM_ SG_ 783 IHC_LgtDist "IHC_LgtDist";
 SG_ IHC_HL_LgtOut : 36|4@1+ (0.5,32) [32|39.5] "W" Vector__XXX

CM_ SG_ 783 IHC_HL_LgtOut "IHC_HL_LgtOut";
 SG_ IHC_CrvLgtRotAngl : 40|8@1+ (0.20000000298,-20) [-20|31.00000076] "deg" Vector__XXX

CM_ SG_ 783 IHC_CrvLgtRotAngl "IHC_CrvLgtRotAngl";
 SG_ MC_IHC_LGT_STAT : 48|4@1+ (1,0) [0|15] "" Vector__XXX

CM_ SG_ 783 MC_IHC_LGT_STAT "MC_IHC_LGT_STAT";

BA_ "GenMsgCycleTime" BO_ 783 8;

BO_ 793 TELEAID_A2: 1 ESP_ABR
 SG_ TELEAID_Alive : 0|1@1+ (1,0) [0|1] "" Vector__XXX

CM_ SG_ 793 TELEAID_Alive "TELEAID_Alive [source boolean]";

BA_ "GenMsgCycleTime" BO_ 793 1;
